VERSION "HINBNNNYYNNNYYNNNNNNNNNNNNYNNNYYYNNYNNNNNN/4//%%/4/'%**4NNN///"

NS_ :

BS_:

BU_: VirtualNMTMaster Sensor_3_ID28 Sensor_2_ID27 Sensor_1_ID23 Display_ID10

BO_ 1820 HBGuard_028: 1 Sensor_3_ID28
 SG_ Toggle : 7|1@1+ (1,0) [0|0] "" Vector__XXX
 SG_ State : 0|7@1+ (1,0) [0|0] "" Vector__XXX

BO_ 262 N28_SRDO1_Inv: 4 Sensor_3_ID28
 SG_ Pressure_1_inverted : 0|32@1- (1,0) [0|1200] "" Vector__XXX

BO_ 261 N28_SRDO1: 4 Sensor_3_ID28
 SG_ Pressure_1 : 0|32@1- (1,0) [0|1200] "" Vector__XXX

BO_ 1436 SSDO_028: 8 Sensor_3_ID28
 SG_ Pressure_1_inverted_6402_02 m2 : 32|32@1- (1,0) [0|1200] "" Vector__XXX
 SG_ Pressure_1_6402_01 m1 : 32|32@1- (1,0) [0|1200] "" Vector__XXX
 SG_ Highest_sub_index_supported_6402 m0 : 32|8@1+ (1,0) [0|255] "" Vector__XXX
 SG_ SubIndex_6402 m25602M : 24|8@1+ (1,0) [0|2] "" Vector__XXX
 SG_ Safety_Checksum_13FF_01 m1 : 32|16@1+ (1,0) [0|65535] "" Vector__XXX
 SG_ Safety_checksum_Number_of_entrie m0 : 32|8@1+ (1,0) [0|255] "" Vector__XXX
 SG_ SubIndex_13FF m5119M : 24|8@1+ (1,0) [0|1] "" Vector__XXX
 SG_ Configuration_valid_13FE m0 : 32|8@1+ (1,0) [0|255] "" Vector__XXX
 SG_ SubIndex_13FE m5118M : 24|8@1+ (1,0) [0|0] "" Vector__XXX
 SG_ SRDO1_mapping_inv_Byte1_1381_02 m2 : 32|32@1+ (1,0) [0|4294967295] "" Vector__XXX
 SG_ SRDO1_mapping_Byte1_1381_01 m1 : 32|32@1+ (1,0) [0|4294967295] "" Vector__XXX
 SG_ SRDO1_Number_of_mapped_objects_1 m0 : 32|8@1+ (1,0) [0|255] "" Vector__XXX
 SG_ SubIndex_1381 m4993M : 24|8@1+ (1,0) [0|2] "" Vector__XXX
 SG_ SRDO1_communication_par_COB_ID_2 m6 : 32|32@1+ (1,0) [0|4294967295] "" Vector__XXX
 SG_ SRDO1_communication_par_COB_ID_1 m5 : 32|32@1+ (1,0) [0|4294967295] "" Vector__XXX
 SG_ SRDO1_communication_par_Transmis m4 : 32|8@1+ (1,0) [254|254] "" Vector__XXX
 SG_ SRDO1_communication_par_refresh_ m2 : 32|16@1+ (1,0) [10|65535] "" Vector__XXX
 SG_ SRDO1_communication_par_Informat m1 : 32|8@1+ (1,0) [0|1] "" Vector__XXX
 SG_ Highest_sub_index_supported_1301 m0 : 32|8@1+ (1,0) [0|255] "" Vector__XXX
 SG_ SubIndex_1301 m4865M : 24|8@1+ (1,0) [0|6] "" Vector__XXX
 SG_ Serial_number_1018_04 m4 : 32|32@1+ (1,0) [0|4294967295] "" Vector__XXX
 SG_ Revision_number_1018_03 m3 : 32|32@1+ (1,0) [0|4294967295] "" Vector__XXX
 SG_ Product_Code_1018_02 m2 : 32|32@1+ (1,0) [0|4294967295] "" Vector__XXX
 SG_ Vendor_Id_1018_01 m1 : 32|32@1+ (1,0) [0|4294967295] "" Vector__XXX
 SG_ Highest_sub_index_supported_1018 m0 : 32|8@1+ (1,0) [1|4] "" Vector__XXX
 SG_ SubIndex_1018 m4120M : 24|8@1+ (1,0) [0|4] "" Vector__XXX
 SG_ Producer_Heartbeat_Time_1017 m0 : 32|16@1+ (1,0) [0|65535] "" Vector__XXX
 SG_ SubIndex_1017 m4119M : 24|8@1+ (1,0) [0|0] "" Vector__XXX
 SG_ Consumer_Heartbeat_Time16_1016_1 m16 : 32|32@1+ (1,0) [0|4294967295] "" Vector__XXX
 SG_ Consumer_Heartbeat_Time15_1016_0 m15 : 32|32@1+ (1,0) [0|4294967295] "" Vector__XXX
 SG_ Consumer_Heartbeat_Time14_1016_0 m14 : 32|32@1+ (1,0) [0|4294967295] "" Vector__XXX
 SG_ Consumer_Heartbeat_Time13_1016_0 m13 : 32|32@1+ (1,0) [0|4294967295] "" Vector__XXX
 SG_ Consumer_Heartbeat_Time12_1016_0 m12 : 32|32@1+ (1,0) [0|4294967295] "" Vector__XXX
 SG_ Consumer_Heartbeat_Time11_1016_0 m11 : 32|32@1+ (1,0) [0|4294967295] "" Vector__XXX
 SG_ Consumer_Heartbeat_Time10_1016_0 m10 : 32|32@1+ (1,0) [0|4294967295] "" Vector__XXX
 SG_ Consumer_Heartbeat_Time9_1016_09 m9 : 32|32@1+ (1,0) [0|4294967295] "" Vector__XXX
 SG_ Consumer_Heartbeat_Time8_1016_08 m8 : 32|32@1+ (1,0) [0|4294967295] "" Vector__XXX
 SG_ Consumer_Heartbeat_Time7_1016_07 m7 : 32|32@1+ (1,0) [0|4294967295] "" Vector__XXX
 SG_ Consumer_Heartbeat_Time6_1016_06 m6 : 32|32@1+ (1,0) [0|4294967295] "" Vector__XXX
 SG_ Consumer_Heartbeat_Time5_1016_05 m5 : 32|32@1+ (1,0) [0|4294967295] "" Vector__XXX
 SG_ Consumer_Heartbeat_Time4_1016_04 m4 : 32|32@1+ (1,0) [0|4294967295] "" Vector__XXX
 SG_ Consumer_Heartbeat_Time3_1016_03 m3 : 32|32@1+ (1,0) [0|4294967295] "" Vector__XXX
 SG_ Consumer_Heartbeat_Time2_1016_02 m2 : 32|32@1+ (1,0) [0|4294967295] "" Vector__XXX
 SG_ Consumer_Heartbeat_Time1_1016_01 m1 : 32|32@1+ (1,0) [0|4294967295] "" Vector__XXX
 SG_ NrOfObjects_1016_00 m0 : 32|8@1+ (1,0) [0|255] "" Vector__XXX
 SG_ SubIndex_1016 m4118M : 24|8@1+ (1,0) [0|16] "" Vector__XXX
 SG_ COB_ID_EMCY_1014 m0 : 32|32@1+ (1,0) [128|3221225471] "" Vector__XXX
 SG_ SubIndex_1014 m4116M : 24|8@1+ (1,0) [0|0] "" Vector__XXX
 SG_ Restore_all_Default_Parameters_1 m1 : 32|32@1+ (1,0) [0|4294967295] "" Vector__XXX
 SG_ Highest_sub_index_supported_1011 m0 : 32|8@1+ (1,0) [0|255] "" Vector__XXX
 SG_ SubIndex_1011 m4113M : 24|8@1+ (1,0) [0|1] "" Vector__XXX
 SG_ Save_all_Parameters_1010_01 m1 : 32|32@1+ (1,0) [0|4294967295] "" Vector__XXX
 SG_ Highest_sub_index_supported_1010 m0 : 32|8@1+ (1,0) [0|255] "" Vector__XXX
 SG_ SubIndex_1010 m4112M : 24|8@1+ (1,0) [0|1] "" Vector__XXX
 SG_ Life_Time_Factor_100D m0 : 32|8@1+ (1,0) [0|255] "" Vector__XXX
 SG_ SubIndex_100D m4109M : 24|8@1+ (1,0) [0|0] "" Vector__XXX
 SG_ Guard_Time_100C m0 : 32|16@1+ (1,0) [0|65535] "" Vector__XXX
 SG_ SubIndex_100C m4108M : 24|8@1+ (1,0) [0|0] "" Vector__XXX
 SG_ Sync_Window_Length_1007 m0 : 32|32@1+ (1,0) [0|4294967295] "" Vector__XXX
 SG_ SubIndex_1007 m4103M : 24|8@1+ (1,0) [0|0] "" Vector__XXX
 SG_ Communication_Cycle_Period_1006 m0 : 32|32@1+ (1,0) [0|4294967295] "" Vector__XXX
 SG_ SubIndex_1006 m4102M : 24|8@1+ (1,0) [0|0] "" Vector__XXX
 SG_ COB_ID_SYNC_1005 m0 : 32|32@1+ (1,0) [128|4294967295] "" Vector__XXX
 SG_ SubIndex_1005 m4101M : 24|8@1+ (1,0) [0|0] "" Vector__XXX
 SG_ Standard_error_field_1003_09 m9 : 32|32@1+ (1,0) [0|4294967295] "" Vector__XXX
 SG_ Standard_error_field_1003_08 m8 : 32|32@1+ (1,0) [0|4294967295] "" Vector__XXX
 SG_ Standard_error_field_1003_07 m7 : 32|32@1+ (1,0) [0|4294967295] "" Vector__XXX
 SG_ Standard_error_field_1003_06 m6 : 32|32@1+ (1,0) [0|4294967295] "" Vector__XXX
 SG_ Standard_error_field_1003_05 m5 : 32|32@1+ (1,0) [0|4294967295] "" Vector__XXX
 SG_ Standard_error_field_1003_04 m4 : 32|32@1+ (1,0) [0|4294967295] "" Vector__XXX
 SG_ Standard_error_field_1003_03 m3 : 32|32@1+ (1,0) [0|4294967295] "" Vector__XXX
 SG_ Standard_error_field_1003_02 m2 : 32|32@1+ (1,0) [0|4294967295] "" Vector__XXX
 SG_ Standard_error_field_1003_01 m1 : 32|32@1+ (1,0) [0|4294967295] "" Vector__XXX
 SG_ Number_of_Errors_1003_00 m0 : 32|8@1+ (1,0) [0|255] "" Vector__XXX
 SG_ SubIndex_1003 m4099M : 24|8@1+ (1,0) [0|9] "" Vector__XXX
 SG_ Error_Register_1001 m0 : 32|8@1+ (1,0) [0|255] "" Vector__XXX
 SG_ SubIndex_1001 m4097M : 24|8@1+ (1,0) [0|0] "" Vector__XXX
 SG_ Device_Type_1000 m0 : 32|32@1+ (1,0) [0|4294967295] "" Vector__XXX
 SG_ SubIndex_1000 m4096M : 24|8@1+ (1,0) [0|0] "" Vector__XXX
 SG_ Index m1M : 8|16@1+ (1,0) [4096|25602] "" Vector__XXX
 SG_ TransferType m1M : 1|1@1+ (1,0) [0|1] "" Vector__XXX
 SG_ NotUsedBytes m1 : 2|2@1+ (1,0) [0|3] "" Vector__XXX
 SG_ SizeIndicator m1 : 0|1@1+ (1,0) [0|1] "" Vector__XXX
 SG_ SCS M : 5|3@1+ (1,0) [0|6] "" Vector__XXX

BO_ 1564 CSDO_028: 8 Vector__XXX
 SG_ Pressure_1_inverted_6402_02 m2 : 32|32@1- (1,0) [0|1200] ""  Sensor_3_ID28
 SG_ Pressure_1_6402_01 m1 : 32|32@1- (1,0) [0|1200] ""  Sensor_3_ID28
 SG_ Highest_sub_index_supported_0000 m0 : 32|8@1+ (1,0) [0|255] ""  Sensor_3_ID28
 SG_ SubIndex_6402 m25602M : 24|8@1+ (1,0) [0|2] ""  Sensor_3_ID28
 SG_ Safety_Checksum_13FF_01 m1 : 32|16@1+ (1,0) [0|65535] ""  Sensor_3_ID28
 SG_ Safety_checksum_Number_of_e_0000 m0 : 32|8@1+ (1,0) [0|255] ""  Sensor_3_ID28
 SG_ SubIndex_13FF m5119M : 24|8@1+ (1,0) [0|1] ""  Sensor_3_ID28
 SG_ Configuration_valid_13FE m0 : 32|8@1+ (1,0) [0|255] ""  Sensor_3_ID28
 SG_ SubIndex_13FE m5118M : 24|8@1+ (1,0) [0|0] ""  Sensor_3_ID28
 SG_ SRDO1_mapping_inv_Byte1_1381_02 m2 : 32|32@1+ (1,0) [0|4294967295] ""  Sensor_3_ID28
 SG_ SRDO1_mapping_Byte1_1381_01 m1 : 32|32@1+ (1,0) [0|4294967295] ""  Sensor_3_ID28
 SG_ SRDO1_Number_of_mapped_obje_0000 m0 : 32|8@1+ (1,0) [0|255] ""  Sensor_3_ID28
 SG_ SubIndex_1381 m4993M : 24|8@1+ (1,0) [0|2] ""  Sensor_3_ID28
 SG_ SRDO1_communication_par_COB_0000 m6 : 32|32@1+ (1,0) [0|4294967295] ""  Sensor_3_ID28
 SG_ SRDO1_communication_par_COB_0001 m5 : 32|32@1+ (1,0) [0|4294967295] ""  Sensor_3_ID28
 SG_ SRDO1_communication_par_Tra_0000 m4 : 32|8@1+ (1,0) [254|254] ""  Sensor_3_ID28
 SG_ SRDO1_communication_par_ref_0000 m2 : 32|16@1+ (1,0) [10|65535] ""  Sensor_3_ID28
 SG_ SRDO1_communication_par_Inf_0000 m1 : 32|8@1+ (1,0) [0|1] ""  Sensor_3_ID28
 SG_ Highest_sub_index_supported_0001 m0 : 32|8@1+ (1,0) [0|255] ""  Sensor_3_ID28
 SG_ SubIndex_1301 m4865M : 24|8@1+ (1,0) [0|6] ""  Sensor_3_ID28
 SG_ Serial_number_1018_04 m4 : 32|32@1+ (1,0) [0|4294967295] ""  Sensor_3_ID28
 SG_ Revision_number_1018_03 m3 : 32|32@1+ (1,0) [0|4294967295] ""  Sensor_3_ID28
 SG_ Product_Code_1018_02 m2 : 32|32@1+ (1,0) [0|4294967295] ""  Sensor_3_ID28
 SG_ Vendor_Id_1018_01 m1 : 32|32@1+ (1,0) [0|4294967295] ""  Sensor_3_ID28
 SG_ Highest_sub_index_supported_0002 m0 : 32|8@1+ (1,0) [1|4] ""  Sensor_3_ID28
 SG_ SubIndex_1018 m4120M : 24|8@1+ (1,0) [0|4] ""  Sensor_3_ID28
 SG_ Producer_Heartbeat_Time_1017 m0 : 32|16@1+ (1,0) [0|65535] ""  Sensor_3_ID28
 SG_ SubIndex_1017 m4119M : 24|8@1+ (1,0) [0|0] ""  Sensor_3_ID28
 SG_ Consumer_Heartbeat_Time16_1_0000 m16 : 32|32@1+ (1,0) [0|4294967295] ""  Sensor_3_ID28
 SG_ Consumer_Heartbeat_Time15_1_0000 m15 : 32|32@1+ (1,0) [0|4294967295] ""  Sensor_3_ID28
 SG_ Consumer_Heartbeat_Time14_1_0000 m14 : 32|32@1+ (1,0) [0|4294967295] ""  Sensor_3_ID28
 SG_ Consumer_Heartbeat_Time13_1_0000 m13 : 32|32@1+ (1,0) [0|4294967295] ""  Sensor_3_ID28
 SG_ Consumer_Heartbeat_Time12_1_0000 m12 : 32|32@1+ (1,0) [0|4294967295] ""  Sensor_3_ID28
 SG_ Consumer_Heartbeat_Time11_1_0000 m11 : 32|32@1+ (1,0) [0|4294967295] ""  Sensor_3_ID28
 SG_ Consumer_Heartbeat_Time10_1_0000 m10 : 32|32@1+ (1,0) [0|4294967295] ""  Sensor_3_ID28
 SG_ Consumer_Heartbeat_Time9_1016_09 m9 : 32|32@1+ (1,0) [0|4294967295] ""  Sensor_3_ID28
 SG_ Consumer_Heartbeat_Time8_1016_08 m8 : 32|32@1+ (1,0) [0|4294967295] ""  Sensor_3_ID28
 SG_ Consumer_Heartbeat_Time7_1016_07 m7 : 32|32@1+ (1,0) [0|4294967295] ""  Sensor_3_ID28
 SG_ Consumer_Heartbeat_Time6_1016_06 m6 : 32|32@1+ (1,0) [0|4294967295] ""  Sensor_3_ID28
 SG_ Consumer_Heartbeat_Time5_1016_05 m5 : 32|32@1+ (1,0) [0|4294967295] ""  Sensor_3_ID28
 SG_ Consumer_Heartbeat_Time4_1016_04 m4 : 32|32@1+ (1,0) [0|4294967295] ""  Sensor_3_ID28
 SG_ Consumer_Heartbeat_Time3_1016_03 m3 : 32|32@1+ (1,0) [0|4294967295] ""  Sensor_3_ID28
 SG_ Consumer_Heartbeat_Time2_1016_02 m2 : 32|32@1+ (1,0) [0|4294967295] ""  Sensor_3_ID28
 SG_ Consumer_Heartbeat_Time1_1016_01 m1 : 32|32@1+ (1,0) [0|4294967295] ""  Sensor_3_ID28
 SG_ NrOfObjects_1016_00 m0 : 32|8@1+ (1,0) [0|255] ""  Sensor_3_ID28
 SG_ SubIndex_1016 m4118M : 24|8@1+ (1,0) [0|16] ""  Sensor_3_ID28
 SG_ COB_ID_EMCY_1014 m0 : 32|32@1+ (1,0) [128|3221225471] ""  Sensor_3_ID28
 SG_ SubIndex_1014 m4116M : 24|8@1+ (1,0) [0|0] ""  Sensor_3_ID28
 SG_ Restore_all_Default_Paramet_0000 m1 : 32|32@1+ (1,0) [0|4294967295] ""  Sensor_3_ID28
 SG_ Highest_sub_index_supported_0003 m0 : 32|8@1+ (1,0) [0|255] ""  Sensor_3_ID28
 SG_ SubIndex_1011 m4113M : 24|8@1+ (1,0) [0|1] ""  Sensor_3_ID28
 SG_ Save_all_Parameters_1010_01 m1 : 32|32@1+ (1,0) [0|4294967295] ""  Sensor_3_ID28
 SG_ Highest_sub_index_supported_0004 m0 : 32|8@1+ (1,0) [0|255] ""  Sensor_3_ID28
 SG_ SubIndex_1010 m4112M : 24|8@1+ (1,0) [0|1] ""  Sensor_3_ID28
 SG_ Life_Time_Factor_100D m0 : 32|8@1+ (1,0) [0|255] ""  Sensor_3_ID28
 SG_ SubIndex_100D m4109M : 24|8@1+ (1,0) [0|0] ""  Sensor_3_ID28
 SG_ Guard_Time_100C m0 : 32|16@1+ (1,0) [0|65535] ""  Sensor_3_ID28
 SG_ SubIndex_100C m4108M : 24|8@1+ (1,0) [0|0] ""  Sensor_3_ID28
 SG_ Sync_Window_Length_1007 m0 : 32|32@1+ (1,0) [0|4294967295] ""  Sensor_3_ID28
 SG_ SubIndex_1007 m4103M : 24|8@1+ (1,0) [0|0] ""  Sensor_3_ID28
 SG_ Communication_Cycle_Period_1006 m0 : 32|32@1+ (1,0) [0|4294967295] ""  Sensor_3_ID28
 SG_ SubIndex_1006 m4102M : 24|8@1+ (1,0) [0|0] ""  Sensor_3_ID28
 SG_ COB_ID_SYNC_1005 m0 : 32|32@1+ (1,0) [128|4294967295] ""  Sensor_3_ID28
 SG_ SubIndex_1005 m4101M : 24|8@1+ (1,0) [0|0] ""  Sensor_3_ID28
 SG_ Standard_error_field_1003_09 m9 : 32|32@1+ (1,0) [0|4294967295] ""  Sensor_3_ID28
 SG_ Standard_error_field_1003_08 m8 : 32|32@1+ (1,0) [0|4294967295] ""  Sensor_3_ID28
 SG_ Standard_error_field_1003_07 m7 : 32|32@1+ (1,0) [0|4294967295] ""  Sensor_3_ID28
 SG_ Standard_error_field_1003_06 m6 : 32|32@1+ (1,0) [0|4294967295] ""  Sensor_3_ID28
 SG_ Standard_error_field_1003_05 m5 : 32|32@1+ (1,0) [0|4294967295] ""  Sensor_3_ID28
 SG_ Standard_error_field_1003_04 m4 : 32|32@1+ (1,0) [0|4294967295] ""  Sensor_3_ID28
 SG_ Standard_error_field_1003_03 m3 : 32|32@1+ (1,0) [0|4294967295] ""  Sensor_3_ID28
 SG_ Standard_error_field_1003_02 m2 : 32|32@1+ (1,0) [0|4294967295] ""  Sensor_3_ID28
 SG_ Standard_error_field_1003_01 m1 : 32|32@1+ (1,0) [0|4294967295] ""  Sensor_3_ID28
 SG_ Number_of_Errors_1003_00 m0 : 32|8@1+ (1,0) [0|255] ""  Sensor_3_ID28
 SG_ SubIndex_1003 m4099M : 24|8@1+ (1,0) [0|9] ""  Sensor_3_ID28
 SG_ Error_Register_1001 m0 : 32|8@1+ (1,0) [0|255] ""  Sensor_3_ID28
 SG_ SubIndex_1001 m4097M : 24|8@1+ (1,0) [0|0] ""  Sensor_3_ID28
 SG_ Device_Type_1000 m0 : 32|32@1+ (1,0) [0|4294967295] ""  Sensor_3_ID28
 SG_ SubIndex_1000 m4096M : 24|8@1+ (1,0) [0|0] ""  Sensor_3_ID28
 SG_ Index m1M : 8|16@1+ (1,0) [4096|25602] ""  Sensor_3_ID28
 SG_ TransferType m1M : 1|1@1+ (1,0) [0|1] ""  Sensor_3_ID28
 SG_ NotUsedBytes m1 : 2|2@1+ (1,0) [0|3] ""  Sensor_3_ID28
 SG_ SizeIndicator m1 : 0|1@1+ (1,0) [0|1] ""  Sensor_3_ID28
 SG_ CCS M : 5|3@1+ (1,0) [0|6] ""  Sensor_3_ID28

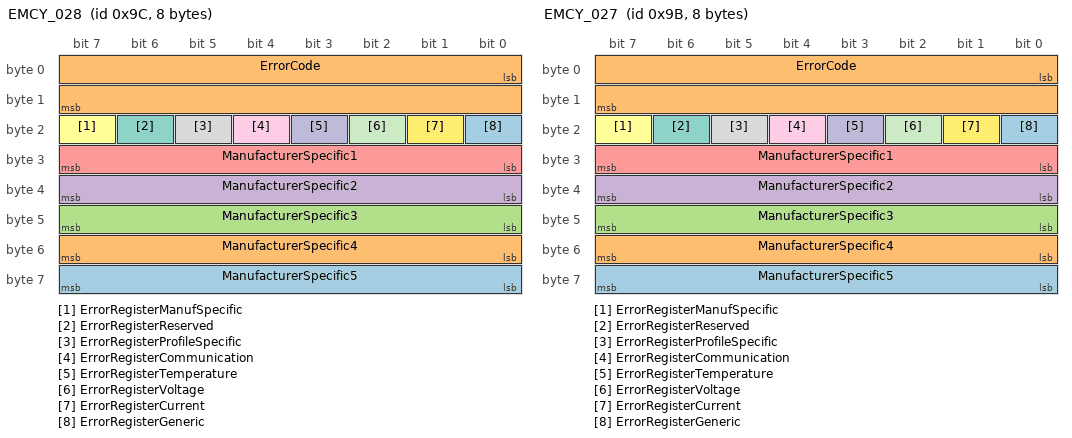
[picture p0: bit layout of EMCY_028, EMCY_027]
BO_ 156 EMCY_028: 8 Sensor_3_ID28
 SG_ ManufacturerSpecific5 : 56|8@1+ (1,0) [0|0] "" Vector__XXX
 SG_ ManufacturerSpecific4 : 48|8@1+ (1,0) [0|0] "" Vector__XXX
 SG_ ManufacturerSpecific3 : 40|8@1+ (1,0) [0|0] "" Vector__XXX
 SG_ ManufacturerSpecific2 : 32|8@1+ (1,0) [0|0] "" Vector__XXX
 SG_ ManufacturerSpecific1 : 24|8@1+ (1,0) [0|0] "" Vector__XXX
 SG_ ErrorRegisterManufSpecific : 23|1@1+ (1,0) [0|0] "" Vector__XXX
 SG_ ErrorRegisterReserved : 22|1@1+ (1,0) [0|0] "" Vector__XXX
 SG_ ErrorRegisterProfileSpecific : 21|1@1+ (1,0) [0|0] "" Vector__XXX
 SG_ ErrorRegisterCommunication : 20|1@1+ (1,0) [0|0] "" Vector__XXX
 SG_ ErrorRegisterTemperature : 19|1@1+ (1,0) [0|0] "" Vector__XXX
 SG_ ErrorRegisterVoltage : 18|1@1+ (1,0) [0|0] "" Vector__XXX
 SG_ ErrorRegisterCurrent : 17|1@1+ (1,0) [0|0] "" Vector__XXX
 SG_ ErrorRegisterGeneric : 16|1@1+ (1,0) [0|0] "" Vector__XXX
 SG_ ErrorCode : 0|16@1+ (1,0) [0|0] "" Vector__XXX

BO_ 1819 HBGuard_027: 1 Sensor_2_ID27
 SG_ Toggle : 7|1@1+ (1,0) [0|0] "" Vector__XXX
 SG_ State : 0|7@1+ (1,0) [0|0] "" Vector__XXX

BO_ 260 N27_SRDO1_Inv: 4 Sensor_2_ID27
 SG_ Pressure_1_inverted : 0|32@1- (1,0) [0|1200] "" Vector__XXX

BO_ 259 N27_SRDO1: 4 Sensor_2_ID27
 SG_ Pressure_1 : 0|32@1- (1,0) [0|1200] "" Vector__XXX

BO_ 1435 SSDO_027: 8 Sensor_2_ID27
 SG_ Pressure_1_inverted_6402_02 m2 : 32|32@1- (1,0) [0|1200] "" Vector__XXX
 SG_ Pressure_1_6402_01 m1 : 32|32@1- (1,0) [0|1200] "" Vector__XXX
 SG_ Highest_sub_index_supported_0005 m0 : 32|8@1+ (1,0) [0|255] "" Vector__XXX
 SG_ SubIndex_6402 m25602M : 24|8@1+ (1,0) [0|2] "" Vector__XXX
 SG_ Safety_Checksum_13FF_01 m1 : 32|16@1+ (1,0) [0|65535] "" Vector__XXX
 SG_ Safety_checksum_Number_of_e_0001 m0 : 32|8@1+ (1,0) [0|255] "" Vector__XXX
 SG_ SubIndex_13FF m5119M : 24|8@1+ (1,0) [0|1] "" Vector__XXX
 SG_ Configuration_valid_13FE m0 : 32|8@1+ (1,0) [0|255] "" Vector__XXX
 SG_ SubIndex_13FE m5118M : 24|8@1+ (1,0) [0|0] "" Vector__XXX
 SG_ SRDO1_mapping_inv_Byte1_1381_02 m2 : 32|32@1+ (1,0) [0|4294967295] "" Vector__XXX
 SG_ SRDO1_mapping_Byte1_1381_01 m1 : 32|32@1+ (1,0) [0|4294967295] "" Vector__XXX
 SG_ SRDO1_Number_of_mapped_obje_0001 m0 : 32|8@1+ (1,0) [0|255] "" Vector__XXX
 SG_ SubIndex_1381 m4993M : 24|8@1+ (1,0) [0|2] "" Vector__XXX
 SG_ SRDO1_communication_par_COB_0002 m6 : 32|32@1+ (1,0) [0|4294967295] "" Vector__XXX
 SG_ SRDO1_communication_par_COB_0003 m5 : 32|32@1+ (1,0) [0|4294967295] "" Vector__XXX
 SG_ SRDO1_communication_par_Tra_0001 m4 : 32|8@1+ (1,0) [254|254] "" Vector__XXX
 SG_ SRDO1_communication_par_ref_0001 m2 : 32|16@1+ (1,0) [10|65535] "" Vector__XXX
 SG_ SRDO1_communication_par_Inf_0001 m1 : 32|8@1+ (1,0) [0|1] "" Vector__XXX
 SG_ Highest_sub_index_supported_0006 m0 : 32|8@1+ (1,0) [0|255] "" Vector__XXX
 SG_ SubIndex_1301 m4865M : 24|8@1+ (1,0) [0|6] "" Vector__XXX
 SG_ Serial_number_1018_04 m4 : 32|32@1+ (1,0) [0|4294967295] "" Vector__XXX
 SG_ Revision_number_1018_03 m3 : 32|32@1+ (1,0) [0|4294967295] "" Vector__XXX
 SG_ Product_Code_1018_02 m2 : 32|32@1+ (1,0) [0|4294967295] "" Vector__XXX
 SG_ Vendor_Id_1018_01 m1 : 32|32@1+ (1,0) [0|4294967295] "" Vector__XXX
 SG_ Highest_sub_index_supported_0007 m0 : 32|8@1+ (1,0) [1|4] "" Vector__XXX
 SG_ SubIndex_1018 m4120M : 24|8@1+ (1,0) [0|4] "" Vector__XXX
 SG_ Producer_Heartbeat_Time_1017 m0 : 32|16@1+ (1,0) [0|65535] "" Vector__XXX
 SG_ SubIndex_1017 m4119M : 24|8@1+ (1,0) [0|0] "" Vector__XXX
 SG_ Consumer_Heartbeat_Time16_1_0001 m16 : 32|32@1+ (1,0) [0|4294967295] "" Vector__XXX
 SG_ Consumer_Heartbeat_Time15_1_0001 m15 : 32|32@1+ (1,0) [0|4294967295] "" Vector__XXX
 SG_ Consumer_Heartbeat_Time14_1_0001 m14 : 32|32@1+ (1,0) [0|4294967295] "" Vector__XXX
 SG_ Consumer_Heartbeat_Time13_1_0001 m13 : 32|32@1+ (1,0) [0|4294967295] "" Vector__XXX
 SG_ Consumer_Heartbeat_Time12_1_0001 m12 : 32|32@1+ (1,0) [0|4294967295] "" Vector__XXX
 SG_ Consumer_Heartbeat_Time11_1_0001 m11 : 32|32@1+ (1,0) [0|4294967295] "" Vector__XXX
 SG_ Consumer_Heartbeat_Time10_1_0001 m10 : 32|32@1+ (1,0) [0|4294967295] "" Vector__XXX
 SG_ Consumer_Heartbeat_Time9_1016_09 m9 : 32|32@1+ (1,0) [0|4294967295] "" Vector__XXX
 SG_ Consumer_Heartbeat_Time8_1016_08 m8 : 32|32@1+ (1,0) [0|4294967295] "" Vector__XXX
 SG_ Consumer_Heartbeat_Time7_1016_07 m7 : 32|32@1+ (1,0) [0|4294967295] "" Vector__XXX
 SG_ Consumer_Heartbeat_Time6_1016_06 m6 : 32|32@1+ (1,0) [0|4294967295] "" Vector__XXX
 SG_ Consumer_Heartbeat_Time5_1016_05 m5 : 32|32@1+ (1,0) [0|4294967295] "" Vector__XXX
 SG_ Consumer_Heartbeat_Time4_1016_04 m4 : 32|32@1+ (1,0) [0|4294967295] "" Vector__XXX
 SG_ Consumer_Heartbeat_Time3_1016_03 m3 : 32|32@1+ (1,0) [0|4294967295] "" Vector__XXX
 SG_ Consumer_Heartbeat_Time2_1016_02 m2 : 32|32@1+ (1,0) [0|4294967295] "" Vector__XXX
 SG_ Consumer_Heartbeat_Time1_1016_01 m1 : 32|32@1+ (1,0) [0|4294967295] "" Vector__XXX
 SG_ NrOfObjects_1016_00 m0 : 32|8@1+ (1,0) [0|255] "" Vector__XXX
 SG_ SubIndex_1016 m4118M : 24|8@1+ (1,0) [0|16] "" Vector__XXX
 SG_ COB_ID_EMCY_1014 m0 : 32|32@1+ (1,0) [128|3221225471] "" Vector__XXX
 SG_ SubIndex_1014 m4116M : 24|8@1+ (1,0) [0|0] "" Vector__XXX
 SG_ Restore_all_Default_Paramet_0001 m1 : 32|32@1+ (1,0) [0|4294967295] "" Vector__XXX
 SG_ Highest_sub_index_supported_0008 m0 : 32|8@1+ (1,0) [0|255] "" Vector__XXX
 SG_ SubIndex_1011 m4113M : 24|8@1+ (1,0) [0|1] "" Vector__XXX
 SG_ Save_all_Parameters_1010_01 m1 : 32|32@1+ (1,0) [0|4294967295] "" Vector__XXX
 SG_ Highest_sub_index_supported_0009 m0 : 32|8@1+ (1,0) [0|255] "" Vector__XXX
 SG_ SubIndex_1010 m4112M : 24|8@1+ (1,0) [0|1] "" Vector__XXX
 SG_ Life_Time_Factor_100D m0 : 32|8@1+ (1,0) [0|255] "" Vector__XXX
 SG_ SubIndex_100D m4109M : 24|8@1+ (1,0) [0|0] "" Vector__XXX
 SG_ Guard_Time_100C m0 : 32|16@1+ (1,0) [0|65535] "" Vector__XXX
 SG_ SubIndex_100C m4108M : 24|8@1+ (1,0) [0|0] "" Vector__XXX
 SG_ Sync_Window_Length_1007 m0 : 32|32@1+ (1,0) [0|4294967295] "" Vector__XXX
 SG_ SubIndex_1007 m4103M : 24|8@1+ (1,0) [0|0] "" Vector__XXX
 SG_ Communication_Cycle_Period_1006 m0 : 32|32@1+ (1,0) [0|4294967295] "" Vector__XXX
 SG_ SubIndex_1006 m4102M : 24|8@1+ (1,0) [0|0] "" Vector__XXX
 SG_ COB_ID_SYNC_1005 m0 : 32|32@1+ (1,0) [128|4294967295] "" Vector__XXX
 SG_ SubIndex_1005 m4101M : 24|8@1+ (1,0) [0|0] "" Vector__XXX
 SG_ Standard_error_field_1003_09 m9 : 32|32@1+ (1,0) [0|4294967295] "" Vector__XXX
 SG_ Standard_error_field_1003_08 m8 : 32|32@1+ (1,0) [0|4294967295] "" Vector__XXX
 SG_ Standard_error_field_1003_07 m7 : 32|32@1+ (1,0) [0|4294967295] "" Vector__XXX
 SG_ Standard_error_field_1003_06 m6 : 32|32@1+ (1,0) [0|4294967295] "" Vector__XXX
 SG_ Standard_error_field_1003_05 m5 : 32|32@1+ (1,0) [0|4294967295] "" Vector__XXX
 SG_ Standard_error_field_1003_04 m4 : 32|32@1+ (1,0) [0|4294967295] "" Vector__XXX
 SG_ Standard_error_field_1003_03 m3 : 32|32@1+ (1,0) [0|4294967295] "" Vector__XXX
 SG_ Standard_error_field_1003_02 m2 : 32|32@1+ (1,0) [0|4294967295] "" Vector__XXX
 SG_ Standard_error_field_1003_01 m1 : 32|32@1+ (1,0) [0|4294967295] "" Vector__XXX
 SG_ Number_of_Errors_1003_00 m0 : 32|8@1+ (1,0) [0|255] "" Vector__XXX
 SG_ SubIndex_1003 m4099M : 24|8@1+ (1,0) [0|9] "" Vector__XXX
 SG_ Error_Register_1001 m0 : 32|8@1+ (1,0) [0|255] "" Vector__XXX
 SG_ SubIndex_1001 m4097M : 24|8@1+ (1,0) [0|0] "" Vector__XXX
 SG_ Device_Type_1000 m0 : 32|32@1+ (1,0) [0|4294967295] "" Vector__XXX
 SG_ SubIndex_1000 m4096M : 24|8@1+ (1,0) [0|0] "" Vector__XXX
 SG_ Index m1M : 8|16@1+ (1,0) [4096|25602] "" Vector__XXX
 SG_ TransferType m1M : 1|1@1+ (1,0) [0|1] "" Vector__XXX
 SG_ NotUsedBytes m1 : 2|2@1+ (1,0) [0|3] "" Vector__XXX
 SG_ SizeIndicator m1 : 0|1@1+ (1,0) [0|1] "" Vector__XXX
 SG_ SCS M : 5|3@1+ (1,0) [0|6] "" Vector__XXX

BO_ 1563 CSDO_027: 8 Vector__XXX
 SG_ Pressure_1_inverted_6402_02 m2 : 32|32@1- (1,0) [0|1200] ""  Sensor_2_ID27
 SG_ Pressure_1_6402_01 m1 : 32|32@1- (1,0) [0|1200] ""  Sensor_2_ID27
 SG_ Highest_sub_index_supported_0010 m0 : 32|8@1+ (1,0) [0|255] ""  Sensor_2_ID27
 SG_ SubIndex_6402 m25602M : 24|8@1+ (1,0) [0|2] ""  Sensor_2_ID27
 SG_ Safety_Checksum_13FF_01 m1 : 32|16@1+ (1,0) [0|65535] ""  Sensor_2_ID27
 SG_ Safety_checksum_Number_of_e_0002 m0 : 32|8@1+ (1,0) [0|255] ""  Sensor_2_ID27
 SG_ SubIndex_13FF m5119M : 24|8@1+ (1,0) [0|1] ""  Sensor_2_ID27
 SG_ Configuration_valid_13FE m0 : 32|8@1+ (1,0) [0|255] ""  Sensor_2_ID27
 SG_ SubIndex_13FE m5118M : 24|8@1+ (1,0) [0|0] ""  Sensor_2_ID27
 SG_ SRDO1_mapping_inv_Byte1_1381_02 m2 : 32|32@1+ (1,0) [0|4294967295] ""  Sensor_2_ID27
 SG_ SRDO1_mapping_Byte1_1381_01 m1 : 32|32@1+ (1,0) [0|4294967295] ""  Sensor_2_ID27
 SG_ SRDO1_Number_of_mapped_obje_0002 m0 : 32|8@1+ (1,0) [0|255] ""  Sensor_2_ID27
 SG_ SubIndex_1381 m4993M : 24|8@1+ (1,0) [0|2] ""  Sensor_2_ID27
 SG_ SRDO1_communication_par_COB_0004 m6 : 32|32@1+ (1,0) [0|4294967295] ""  Sensor_2_ID27
 SG_ SRDO1_communication_par_COB_0005 m5 : 32|32@1+ (1,0) [0|4294967295] ""  Sensor_2_ID27
 SG_ SRDO1_communication_par_Tra_0002 m4 : 32|8@1+ (1,0) [254|254] ""  Sensor_2_ID27
 SG_ SRDO1_communication_par_ref_0002 m2 : 32|16@1+ (1,0) [10|65535] ""  Sensor_2_ID27
 SG_ SRDO1_communication_par_Inf_0002 m1 : 32|8@1+ (1,0) [0|1] ""  Sensor_2_ID27
 SG_ Highest_sub_index_supported_0011 m0 : 32|8@1+ (1,0) [0|255] ""  Sensor_2_ID27
 SG_ SubIndex_1301 m4865M : 24|8@1+ (1,0) [0|6] ""  Sensor_2_ID27
 SG_ Serial_number_1018_04 m4 : 32|32@1+ (1,0) [0|4294967295] ""  Sensor_2_ID27
 SG_ Revision_number_1018_03 m3 : 32|32@1+ (1,0) [0|4294967295] ""  Sensor_2_ID27
 SG_ Product_Code_1018_02 m2 : 32|32@1+ (1,0) [0|4294967295] ""  Sensor_2_ID27
 SG_ Vendor_Id_1018_01 m1 : 32|32@1+ (1,0) [0|4294967295] ""  Sensor_2_ID27
 SG_ Highest_sub_index_supported_0012 m0 : 32|8@1+ (1,0) [1|4] ""  Sensor_2_ID27
 SG_ SubIndex_1018 m4120M : 24|8@1+ (1,0) [0|4] ""  Sensor_2_ID27
 SG_ Producer_Heartbeat_Time_1017 m0 : 32|16@1+ (1,0) [0|65535] ""  Sensor_2_ID27
 SG_ SubIndex_1017 m4119M : 24|8@1+ (1,0) [0|0] ""  Sensor_2_ID27
 SG_ Consumer_Heartbeat_Time16_1_0002 m16 : 32|32@1+ (1,0) [0|4294967295] ""  Sensor_2_ID27
 SG_ Consumer_Heartbeat_Time15_1_0002 m15 : 32|32@1+ (1,0) [0|4294967295] ""  Sensor_2_ID27
 SG_ Consumer_Heartbeat_Time14_1_0002 m14 : 32|32@1+ (1,0) [0|4294967295] ""  Sensor_2_ID27
 SG_ Consumer_Heartbeat_Time13_1_0002 m13 : 32|32@1+ (1,0) [0|4294967295] ""  Sensor_2_ID27
 SG_ Consumer_Heartbeat_Time12_1_0002 m12 : 32|32@1+ (1,0) [0|4294967295] ""  Sensor_2_ID27
 SG_ Consumer_Heartbeat_Time11_1_0002 m11 : 32|32@1+ (1,0) [0|4294967295] ""  Sensor_2_ID27
 SG_ Consumer_Heartbeat_Time10_1_0002 m10 : 32|32@1+ (1,0) [0|4294967295] ""  Sensor_2_ID27
 SG_ Consumer_Heartbeat_Time9_1016_09 m9 : 32|32@1+ (1,0) [0|4294967295] ""  Sensor_2_ID27
 SG_ Consumer_Heartbeat_Time8_1016_08 m8 : 32|32@1+ (1,0) [0|4294967295] ""  Sensor_2_ID27
 SG_ Consumer_Heartbeat_Time7_1016_07 m7 : 32|32@1+ (1,0) [0|4294967295] ""  Sensor_2_ID27
 SG_ Consumer_Heartbeat_Time6_1016_06 m6 : 32|32@1+ (1,0) [0|4294967295] ""  Sensor_2_ID27
 SG_ Consumer_Heartbeat_Time5_1016_05 m5 : 32|32@1+ (1,0) [0|4294967295] ""  Sensor_2_ID27
 SG_ Consumer_Heartbeat_Time4_1016_04 m4 : 32|32@1+ (1,0) [0|4294967295] ""  Sensor_2_ID27
 SG_ Consumer_Heartbeat_Time3_1016_03 m3 : 32|32@1+ (1,0) [0|4294967295] ""  Sensor_2_ID27
 SG_ Consumer_Heartbeat_Time2_1016_02 m2 : 32|32@1+ (1,0) [0|4294967295] ""  Sensor_2_ID27
 SG_ Consumer_Heartbeat_Time1_1016_01 m1 : 32|32@1+ (1,0) [0|4294967295] ""  Sensor_2_ID27
 SG_ NrOfObjects_1016_00 m0 : 32|8@1+ (1,0) [0|255] ""  Sensor_2_ID27
 SG_ SubIndex_1016 m4118M : 24|8@1+ (1,0) [0|16] ""  Sensor_2_ID27
 SG_ COB_ID_EMCY_1014 m0 : 32|32@1+ (1,0) [128|3221225471] ""  Sensor_2_ID27
 SG_ SubIndex_1014 m4116M : 24|8@1+ (1,0) [0|0] ""  Sensor_2_ID27
 SG_ Restore_all_Default_Paramet_0002 m1 : 32|32@1+ (1,0) [0|4294967295] ""  Sensor_2_ID27
 SG_ Highest_sub_index_supported_0013 m0 : 32|8@1+ (1,0) [0|255] ""  Sensor_2_ID27
 SG_ SubIndex_1011 m4113M : 24|8@1+ (1,0) [0|1] ""  Sensor_2_ID27
 SG_ Save_all_Parameters_1010_01 m1 : 32|32@1+ (1,0) [0|4294967295] ""  Sensor_2_ID27
 SG_ Highest_sub_index_supported_0014 m0 : 32|8@1+ (1,0) [0|255] ""  Sensor_2_ID27
 SG_ SubIndex_1010 m4112M : 24|8@1+ (1,0) [0|1] ""  Sensor_2_ID27
 SG_ Life_Time_Factor_100D m0 : 32|8@1+ (1,0) [0|255] ""  Sensor_2_ID27
 SG_ SubIndex_100D m4109M : 24|8@1+ (1,0) [0|0] ""  Sensor_2_ID27
 SG_ Guard_Time_100C m0 : 32|16@1+ (1,0) [0|65535] ""  Sensor_2_ID27
 SG_ SubIndex_100C m4108M : 24|8@1+ (1,0) [0|0] ""  Sensor_2_ID27
 SG_ Sync_Window_Length_1007 m0 : 32|32@1+ (1,0) [0|4294967295] ""  Sensor_2_ID27
 SG_ SubIndex_1007 m4103M : 24|8@1+ (1,0) [0|0] ""  Sensor_2_ID27
 SG_ Communication_Cycle_Period_1006 m0 : 32|32@1+ (1,0) [0|4294967295] ""  Sensor_2_ID27
 SG_ SubIndex_1006 m4102M : 24|8@1+ (1,0) [0|0] ""  Sensor_2_ID27
 SG_ COB_ID_SYNC_1005 m0 : 32|32@1+ (1,0) [128|4294967295] ""  Sensor_2_ID27
 SG_ SubIndex_1005 m4101M : 24|8@1+ (1,0) [0|0] ""  Sensor_2_ID27
 SG_ Standard_error_field_1003_09 m9 : 32|32@1+ (1,0) [0|4294967295] ""  Sensor_2_ID27
 SG_ Standard_error_field_1003_08 m8 : 32|32@1+ (1,0) [0|4294967295] ""  Sensor_2_ID27
 SG_ Standard_error_field_1003_07 m7 : 32|32@1+ (1,0) [0|4294967295] ""  Sensor_2_ID27
 SG_ Standard_error_field_1003_06 m6 : 32|32@1+ (1,0) [0|4294967295] ""  Sensor_2_ID27
 SG_ Standard_error_field_1003_05 m5 : 32|32@1+ (1,0) [0|4294967295] ""  Sensor_2_ID27
 SG_ Standard_error_field_1003_04 m4 : 32|32@1+ (1,0) [0|4294967295] ""  Sensor_2_ID27
 SG_ Standard_error_field_1003_03 m3 : 32|32@1+ (1,0) [0|4294967295] ""  Sensor_2_ID27
 SG_ Standard_error_field_1003_02 m2 : 32|32@1+ (1,0) [0|4294967295] ""  Sensor_2_ID27
 SG_ Standard_error_field_1003_01 m1 : 32|32@1+ (1,0) [0|4294967295] ""  Sensor_2_ID27
 SG_ Number_of_Errors_1003_00 m0 : 32|8@1+ (1,0) [0|255] ""  Sensor_2_ID27
 SG_ SubIndex_1003 m4099M : 24|8@1+ (1,0) [0|9] ""  Sensor_2_ID27
 SG_ Error_Register_1001 m0 : 32|8@1+ (1,0) [0|255] ""  Sensor_2_ID27
 SG_ SubIndex_1001 m4097M : 24|8@1+ (1,0) [0|0] ""  Sensor_2_ID27
 SG_ Device_Type_1000 m0 : 32|32@1+ (1,0) [0|4294967295] ""  Sensor_2_ID27
 SG_ SubIndex_1000 m4096M : 24|8@1+ (1,0) [0|0] ""  Sensor_2_ID27
 SG_ Index m1M : 8|16@1+ (1,0) [4096|25602] ""  Sensor_2_ID27
 SG_ TransferType m1M : 1|1@1+ (1,0) [0|1] ""  Sensor_2_ID27
 SG_ NotUsedBytes m1 : 2|2@1+ (1,0) [0|3] ""  Sensor_2_ID27
 SG_ SizeIndicator m1 : 0|1@1+ (1,0) [0|1] ""  Sensor_2_ID27
 SG_ CCS M : 5|3@1+ (1,0) [0|6] ""  Sensor_2_ID27

BO_ 155 EMCY_027: 8 Sensor_2_ID27
 SG_ ManufacturerSpecific5 : 56|8@1+ (1,0) [0|0] "" Vector__XXX
 SG_ ManufacturerSpecific4 : 48|8@1+ (1,0) [0|0] "" Vector__XXX
 SG_ ManufacturerSpecific3 : 40|8@1+ (1,0) [0|0] "" Vector__XXX
 SG_ ManufacturerSpecific2 : 32|8@1+ (1,0) [0|0] "" Vector__XXX
 SG_ ManufacturerSpecific1 : 24|8@1+ (1,0) [0|0] "" Vector__XXX
 SG_ ErrorRegisterManufSpecific : 23|1@1+ (1,0) [0|0] "" Vector__XXX
 SG_ ErrorRegisterReserved : 22|1@1+ (1,0) [0|0] "" Vector__XXX
 SG_ ErrorRegisterProfileSpecific : 21|1@1+ (1,0) [0|0] "" Vector__XXX
 SG_ ErrorRegisterCommunication : 20|1@1+ (1,0) [0|0] "" Vector__XXX
 SG_ ErrorRegisterTemperature : 19|1@1+ (1,0) [0|0] "" Vector__XXX
 SG_ ErrorRegisterVoltage : 18|1@1+ (1,0) [0|0] "" Vector__XXX
 SG_ ErrorRegisterCurrent : 17|1@1+ (1,0) [0|0] "" Vector__XXX
 SG_ ErrorRegisterGeneric : 16|1@1+ (1,0) [0|0] "" Vector__XXX
 SG_ ErrorCode : 0|16@1+ (1,0) [0|0] "" Vector__XXX

BO_ 1815 HBGuard_023: 1 Sensor_1_ID23
 SG_ Toggle : 7|1@1+ (1,0) [0|0] "" Vector__XXX
 SG_ State : 0|7@1+ (1,0) [0|0] "" Vector__XXX

BO_ 258 N23_SRDO1_Inv: 4 Sensor_1_ID23
 SG_ Pressure_1_inverted : 0|32@1- (1,0) [0|1200] "" Vector__XXX

BO_ 257 N23_SRDO1: 4 Sensor_1_ID23
 SG_ Pressure_1 : 0|32@1- (1,0) [0|1200] "" Vector__XXX

BO_ 1431 SSDO_023: 8 Sensor_1_ID23
 SG_ Pressure_1_inverted_6402_02 m2 : 32|32@1- (1,0) [0|1200] "" Vector__XXX
 SG_ Pressure_1_6402_01 m1 : 32|32@1- (1,0) [0|1200] "" Vector__XXX
 SG_ Highest_sub_index_supported_0015 m0 : 32|8@1+ (1,0) [0|255] "" Vector__XXX
 SG_ SubIndex_6402 m25602M : 24|8@1+ (1,0) [0|2] "" Vector__XXX
 SG_ Safety_Checksum_13FF_01 m1 : 32|16@1+ (1,0) [0|65535] "" Vector__XXX
 SG_ Safety_checksum_Number_of_e_0003 m0 : 32|8@1+ (1,0) [0|255] "" Vector__XXX
 SG_ SubIndex_13FF m5119M : 24|8@1+ (1,0) [0|1] "" Vector__XXX
 SG_ Configuration_valid_13FE m0 : 32|8@1+ (1,0) [0|255] "" Vector__XXX
 SG_ SubIndex_13FE m5118M : 24|8@1+ (1,0) [0|0] "" Vector__XXX
 SG_ SRDO1_mapping_inv_Byte1_1381_02 m2 : 32|32@1+ (1,0) [0|4294967295] "" Vector__XXX
 SG_ SRDO1_mapping_Byte1_1381_01 m1 : 32|32@1+ (1,0) [0|4294967295] "" Vector__XXX
 SG_ SRDO1_Number_of_mapped_obje_0003 m0 : 32|8@1+ (1,0) [0|255] "" Vector__XXX
 SG_ SubIndex_1381 m4993M : 24|8@1+ (1,0) [0|2] "" Vector__XXX
 SG_ SRDO1_communication_par_COB_0006 m6 : 32|32@1+ (1,0) [0|4294967295] "" Vector__XXX
 SG_ SRDO1_communication_par_COB_0007 m5 : 32|32@1+ (1,0) [0|4294967295] "" Vector__XXX
 SG_ SRDO1_communication_par_Tra_0003 m4 : 32|8@1+ (1,0) [254|254] "" Vector__XXX
 SG_ SRDO1_communication_par_ref_0003 m2 : 32|16@1+ (1,0) [10|65535] "" Vector__XXX
 SG_ SRDO1_communication_par_Inf_0003 m1 : 32|8@1+ (1,0) [0|1] "" Vector__XXX
 SG_ Highest_sub_index_supported_0016 m0 : 32|8@1+ (1,0) [0|255] "" Vector__XXX
 SG_ SubIndex_1301 m4865M : 24|8@1+ (1,0) [0|6] "" Vector__XXX
 SG_ Serial_number_1018_04 m4 : 32|32@1+ (1,0) [0|4294967295] "" Vector__XXX
 SG_ Revision_number_1018_03 m3 : 32|32@1+ (1,0) [0|4294967295] "" Vector__XXX
 SG_ Product_Code_1018_02 m2 : 32|32@1+ (1,0) [0|4294967295] "" Vector__XXX
 SG_ Vendor_Id_1018_01 m1 : 32|32@1+ (1,0) [0|4294967295] "" Vector__XXX
 SG_ Highest_sub_index_supported_0017 m0 : 32|8@1+ (1,0) [1|4] "" Vector__XXX
 SG_ SubIndex_1018 m4120M : 24|8@1+ (1,0) [0|4] "" Vector__XXX
 SG_ Producer_Heartbeat_Time_1017 m0 : 32|16@1+ (1,0) [0|65535] "" Vector__XXX
 SG_ SubIndex_1017 m4119M : 24|8@1+ (1,0) [0|0] "" Vector__XXX
 SG_ Consumer_Heartbeat_Time16_1_0003 m16 : 32|32@1+ (1,0) [0|4294967295] "" Vector__XXX
 SG_ Consumer_Heartbeat_Time15_1_0003 m15 : 32|32@1+ (1,0) [0|4294967295] "" Vector__XXX
 SG_ Consumer_Heartbeat_Time14_1_0003 m14 : 32|32@1+ (1,0) [0|4294967295] "" Vector__XXX
 SG_ Consumer_Heartbeat_Time13_1_0003 m13 : 32|32@1+ (1,0) [0|4294967295] "" Vector__XXX
 SG_ Consumer_Heartbeat_Time12_1_0003 m12 : 32|32@1+ (1,0) [0|4294967295] "" Vector__XXX
 SG_ Consumer_Heartbeat_Time11_1_0003 m11 : 32|32@1+ (1,0) [0|4294967295] "" Vector__XXX
 SG_ Consumer_Heartbeat_Time10_1_0003 m10 : 32|32@1+ (1,0) [0|4294967295] "" Vector__XXX
 SG_ Consumer_Heartbeat_Time9_1016_09 m9 : 32|32@1+ (1,0) [0|4294967295] "" Vector__XXX
 SG_ Consumer_Heartbeat_Time8_1016_08 m8 : 32|32@1+ (1,0) [0|4294967295] "" Vector__XXX
 SG_ Consumer_Heartbeat_Time7_1016_07 m7 : 32|32@1+ (1,0) [0|4294967295] "" Vector__XXX
 SG_ Consumer_Heartbeat_Time6_1016_06 m6 : 32|32@1+ (1,0) [0|4294967295] "" Vector__XXX
 SG_ Consumer_Heartbeat_Time5_1016_05 m5 : 32|32@1+ (1,0) [0|4294967295] "" Vector__XXX
 SG_ Consumer_Heartbeat_Time4_1016_04 m4 : 32|32@1+ (1,0) [0|4294967295] "" Vector__XXX
 SG_ Consumer_Heartbeat_Time3_1016_03 m3 : 32|32@1+ (1,0) [0|4294967295] "" Vector__XXX
 SG_ Consumer_Heartbeat_Time2_1016_02 m2 : 32|32@1+ (1,0) [0|4294967295] "" Vector__XXX
 SG_ Consumer_Heartbeat_Time1_1016_01 m1 : 32|32@1+ (1,0) [0|4294967295] "" Vector__XXX
 SG_ NrOfObjects_1016_00 m0 : 32|8@1+ (1,0) [0|255] "" Vector__XXX
 SG_ SubIndex_1016 m4118M : 24|8@1+ (1,0) [0|16] "" Vector__XXX
 SG_ COB_ID_EMCY_1014 m0 : 32|32@1+ (1,0) [128|3221225471] "" Vector__XXX
 SG_ SubIndex_1014 m4116M : 24|8@1+ (1,0) [0|0] "" Vector__XXX
 SG_ Restore_all_Default_Paramet_0003 m1 : 32|32@1+ (1,0) [0|4294967295] "" Vector__XXX
 SG_ Highest_sub_index_supported_0018 m0 : 32|8@1+ (1,0) [0|255] "" Vector__XXX
 SG_ SubIndex_1011 m4113M : 24|8@1+ (1,0) [0|1] "" Vector__XXX
 SG_ Save_all_Parameters_1010_01 m1 : 32|32@1+ (1,0) [0|4294967295] "" Vector__XXX
 SG_ Highest_sub_index_supported_0019 m0 : 32|8@1+ (1,0) [0|255] "" Vector__XXX
 SG_ SubIndex_1010 m4112M : 24|8@1+ (1,0) [0|1] "" Vector__XXX
 SG_ Life_Time_Factor_100D m0 : 32|8@1+ (1,0) [0|255] "" Vector__XXX
 SG_ SubIndex_100D m4109M : 24|8@1+ (1,0) [0|0] "" Vector__XXX
 SG_ Guard_Time_100C m0 : 32|16@1+ (1,0) [0|65535] "" Vector__XXX
 SG_ SubIndex_100C m4108M : 24|8@1+ (1,0) [0|0] "" Vector__XXX
 SG_ Sync_Window_Length_1007 m0 : 32|32@1+ (1,0) [0|4294967295] "" Vector__XXX
 SG_ SubIndex_1007 m4103M : 24|8@1+ (1,0) [0|0] "" Vector__XXX
 SG_ Communication_Cycle_Period_1006 m0 : 32|32@1+ (1,0) [0|4294967295] "" Vector__XXX
 SG_ SubIndex_1006 m4102M : 24|8@1+ (1,0) [0|0] "" Vector__XXX
 SG_ COB_ID_SYNC_1005 m0 : 32|32@1+ (1,0) [128|4294967295] "" Vector__XXX
 SG_ SubIndex_1005 m4101M : 24|8@1+ (1,0) [0|0] "" Vector__XXX
 SG_ Standard_error_field_1003_09 m9 : 32|32@1+ (1,0) [0|4294967295] "" Vector__XXX
 SG_ Standard_error_field_1003_08 m8 : 32|32@1+ (1,0) [0|4294967295] "" Vector__XXX
 SG_ Standard_error_field_1003_07 m7 : 32|32@1+ (1,0) [0|4294967295] "" Vector__XXX
 SG_ Standard_error_field_1003_06 m6 : 32|32@1+ (1,0) [0|4294967295] "" Vector__XXX
 SG_ Standard_error_field_1003_05 m5 : 32|32@1+ (1,0) [0|4294967295] "" Vector__XXX
 SG_ Standard_error_field_1003_04 m4 : 32|32@1+ (1,0) [0|4294967295] "" Vector__XXX
 SG_ Standard_error_field_1003_03 m3 : 32|32@1+ (1,0) [0|4294967295] "" Vector__XXX
 SG_ Standard_error_field_1003_02 m2 : 32|32@1+ (1,0) [0|4294967295] "" Vector__XXX
 SG_ Standard_error_field_1003_01 m1 : 32|32@1+ (1,0) [0|4294967295] "" Vector__XXX
 SG_ Number_of_Errors_1003_00 m0 : 32|8@1+ (1,0) [0|255] "" Vector__XXX
 SG_ SubIndex_1003 m4099M : 24|8@1+ (1,0) [0|9] "" Vector__XXX
 SG_ Error_Register_1001 m0 : 32|8@1+ (1,0) [0|255] "" Vector__XXX
 SG_ SubIndex_1001 m4097M : 24|8@1+ (1,0) [0|0] "" Vector__XXX
 SG_ Device_Type_1000 m0 : 32|32@1+ (1,0) [0|4294967295] "" Vector__XXX
 SG_ SubIndex_1000 m4096M : 24|8@1+ (1,0) [0|0] "" Vector__XXX
 SG_ Index m1M : 8|16@1+ (1,0) [4096|25602] "" Vector__XXX
 SG_ TransferType m1M : 1|1@1+ (1,0) [0|1] "" Vector__XXX
 SG_ NotUsedBytes m1 : 2|2@1+ (1,0) [0|3] "" Vector__XXX
 SG_ SizeIndicator m1 : 0|1@1+ (1,0) [0|1] "" Vector__XXX
 SG_ SCS M : 5|3@1+ (1,0) [0|6] "" Vector__XXX

BO_ 1559 CSDO_023: 8 Vector__XXX
 SG_ Pressure_1_inverted_6402_02 m2 : 32|32@1- (1,0) [0|1200] ""  Sensor_1_ID23
 SG_ Pressure_1_6402_01 m1 : 32|32@1- (1,0) [0|1200] ""  Sensor_1_ID23
 SG_ Highest_sub_index_supported_0020 m0 : 32|8@1+ (1,0) [0|255] ""  Sensor_1_ID23
 SG_ SubIndex_6402 m25602M : 24|8@1+ (1,0) [0|2] ""  Sensor_1_ID23
 SG_ Safety_Checksum_13FF_01 m1 : 32|16@1+ (1,0) [0|65535] ""  Sensor_1_ID23
 SG_ Safety_checksum_Number_of_e_0004 m0 : 32|8@1+ (1,0) [0|255] ""  Sensor_1_ID23
 SG_ SubIndex_13FF m5119M : 24|8@1+ (1,0) [0|1] ""  Sensor_1_ID23
 SG_ Configuration_valid_13FE m0 : 32|8@1+ (1,0) [0|255] ""  Sensor_1_ID23
 SG_ SubIndex_13FE m5118M : 24|8@1+ (1,0) [0|0] ""  Sensor_1_ID23
 SG_ SRDO1_mapping_inv_Byte1_1381_02 m2 : 32|32@1+ (1,0) [0|4294967295] ""  Sensor_1_ID23
 SG_ SRDO1_mapping_Byte1_1381_01 m1 : 32|32@1+ (1,0) [0|4294967295] ""  Sensor_1_ID23
 SG_ SRDO1_Number_of_mapped_obje_0004 m0 : 32|8@1+ (1,0) [0|255] ""  Sensor_1_ID23
 SG_ SubIndex_1381 m4993M : 24|8@1+ (1,0) [0|2] ""  Sensor_1_ID23
 SG_ SRDO1_communication_par_COB_0008 m6 : 32|32@1+ (1,0) [0|4294967295] ""  Sensor_1_ID23
 SG_ SRDO1_communication_par_COB_0009 m5 : 32|32@1+ (1,0) [0|4294967295] ""  Sensor_1_ID23
 SG_ SRDO1_communication_par_Tra_0004 m4 : 32|8@1+ (1,0) [254|254] ""  Sensor_1_ID23
 SG_ SRDO1_communication_par_ref_0004 m2 : 32|16@1+ (1,0) [10|65535] ""  Sensor_1_ID23
 SG_ SRDO1_communication_par_Inf_0004 m1 : 32|8@1+ (1,0) [0|1] ""  Sensor_1_ID23
 SG_ Highest_sub_index_supported_0021 m0 : 32|8@1+ (1,0) [0|255] ""  Sensor_1_ID23
 SG_ SubIndex_1301 m4865M : 24|8@1+ (1,0) [0|6] ""  Sensor_1_ID23
 SG_ Serial_number_1018_04 m4 : 32|32@1+ (1,0) [0|4294967295] ""  Sensor_1_ID23
 SG_ Revision_number_1018_03 m3 : 32|32@1+ (1,0) [0|4294967295] ""  Sensor_1_ID23
 SG_ Product_Code_1018_02 m2 : 32|32@1+ (1,0) [0|4294967295] ""  Sensor_1_ID23
 SG_ Vendor_Id_1018_01 m1 : 32|32@1+ (1,0) [0|4294967295] ""  Sensor_1_ID23
 SG_ Highest_sub_index_supported_0022 m0 : 32|8@1+ (1,0) [1|4] ""  Sensor_1_ID23
 SG_ SubIndex_1018 m4120M : 24|8@1+ (1,0) [0|4] ""  Sensor_1_ID23
 SG_ Producer_Heartbeat_Time_1017 m0 : 32|16@1+ (1,0) [0|65535] ""  Sensor_1_ID23
 SG_ SubIndex_1017 m4119M : 24|8@1+ (1,0) [0|0] ""  Sensor_1_ID23
 SG_ Consumer_Heartbeat_Time16_1_0004 m16 : 32|32@1+ (1,0) [0|4294967295] ""  Sensor_1_ID23
 SG_ Consumer_Heartbeat_Time15_1_0004 m15 : 32|32@1+ (1,0) [0|4294967295] ""  Sensor_1_ID23
 SG_ Consumer_Heartbeat_Time14_1_0004 m14 : 32|32@1+ (1,0) [0|4294967295] ""  Sensor_1_ID23
 SG_ Consumer_Heartbeat_Time13_1_0004 m13 : 32|32@1+ (1,0) [0|4294967295] ""  Sensor_1_ID23
 SG_ Consumer_Heartbeat_Time12_1_0004 m12 : 32|32@1+ (1,0) [0|4294967295] ""  Sensor_1_ID23
 SG_ Consumer_Heartbeat_Time11_1_0004 m11 : 32|32@1+ (1,0) [0|4294967295] ""  Sensor_1_ID23
 SG_ Consumer_Heartbeat_Time10_1_0004 m10 : 32|32@1+ (1,0) [0|4294967295] ""  Sensor_1_ID23
 SG_ Consumer_Heartbeat_Time9_1016_09 m9 : 32|32@1+ (1,0) [0|4294967295] ""  Sensor_1_ID23
 SG_ Consumer_Heartbeat_Time8_1016_08 m8 : 32|32@1+ (1,0) [0|4294967295] ""  Sensor_1_ID23
 SG_ Consumer_Heartbeat_Time7_1016_07 m7 : 32|32@1+ (1,0) [0|4294967295] ""  Sensor_1_ID23
 SG_ Consumer_Heartbeat_Time6_1016_06 m6 : 32|32@1+ (1,0) [0|4294967295] ""  Sensor_1_ID23
 SG_ Consumer_Heartbeat_Time5_1016_05 m5 : 32|32@1+ (1,0) [0|4294967295] ""  Sensor_1_ID23
 SG_ Consumer_Heartbeat_Time4_1016_04 m4 : 32|32@1+ (1,0) [0|4294967295] ""  Sensor_1_ID23
 SG_ Consumer_Heartbeat_Time3_1016_03 m3 : 32|32@1+ (1,0) [0|4294967295] ""  Sensor_1_ID23
 SG_ Consumer_Heartbeat_Time2_1016_02 m2 : 32|32@1+ (1,0) [0|4294967295] ""  Sensor_1_ID23
 SG_ Consumer_Heartbeat_Time1_1016_01 m1 : 32|32@1+ (1,0) [0|4294967295] ""  Sensor_1_ID23
 SG_ NrOfObjects_1016_00 m0 : 32|8@1+ (1,0) [0|255] ""  Sensor_1_ID23
 SG_ SubIndex_1016 m4118M : 24|8@1+ (1,0) [0|16] ""  Sensor_1_ID23
 SG_ COB_ID_EMCY_1014 m0 : 32|32@1+ (1,0) [128|3221225471] ""  Sensor_1_ID23
 SG_ SubIndex_1014 m4116M : 24|8@1+ (1,0) [0|0] ""  Sensor_1_ID23
 SG_ Restore_all_Default_Paramet_0004 m1 : 32|32@1+ (1,0) [0|4294967295] ""  Sensor_1_ID23
 SG_ Highest_sub_index_supported_0023 m0 : 32|8@1+ (1,0) [0|255] ""  Sensor_1_ID23
 SG_ SubIndex_1011 m4113M : 24|8@1+ (1,0) [0|1] ""  Sensor_1_ID23
 SG_ Save_all_Parameters_1010_01 m1 : 32|32@1+ (1,0) [0|4294967295] ""  Sensor_1_ID23
 SG_ Highest_sub_index_supported_0024 m0 : 32|8@1+ (1,0) [0|255] ""  Sensor_1_ID23
 SG_ SubIndex_1010 m4112M : 24|8@1+ (1,0) [0|1] ""  Sensor_1_ID23
 SG_ Life_Time_Factor_100D m0 : 32|8@1+ (1,0) [0|255] ""  Sensor_1_ID23
 SG_ SubIndex_100D m4109M : 24|8@1+ (1,0) [0|0] ""  Sensor_1_ID23
 SG_ Guard_Time_100C m0 : 32|16@1+ (1,0) [0|65535] ""  Sensor_1_ID23
 SG_ SubIndex_100C m4108M : 24|8@1+ (1,0) [0|0] ""  Sensor_1_ID23
 SG_ Sync_Window_Length_1007 m0 : 32|32@1+ (1,0) [0|4294967295] ""  Sensor_1_ID23
 SG_ SubIndex_1007 m4103M : 24|8@1+ (1,0) [0|0] ""  Sensor_1_ID23
 SG_ Communication_Cycle_Period_1006 m0 : 32|32@1+ (1,0) [0|4294967295] ""  Sensor_1_ID23
 SG_ SubIndex_1006 m4102M : 24|8@1+ (1,0) [0|0] ""  Sensor_1_ID23
 SG_ COB_ID_SYNC_1005 m0 : 32|32@1+ (1,0) [128|4294967295] ""  Sensor_1_ID23
 SG_ SubIndex_1005 m4101M : 24|8@1+ (1,0) [0|0] ""  Sensor_1_ID23
 SG_ Standard_error_field_1003_09 m9 : 32|32@1+ (1,0) [0|4294967295] ""  Sensor_1_ID23
 SG_ Standard_error_field_1003_08 m8 : 32|32@1+ (1,0) [0|4294967295] ""  Sensor_1_ID23
 SG_ Standard_error_field_1003_07 m7 : 32|32@1+ (1,0) [0|4294967295] ""  Sensor_1_ID23
 SG_ Standard_error_field_1003_06 m6 : 32|32@1+ (1,0) [0|4294967295] ""  Sensor_1_ID23
 SG_ Standard_error_field_1003_05 m5 : 32|32@1+ (1,0) [0|4294967295] ""  Sensor_1_ID23
 SG_ Standard_error_field_1003_04 m4 : 32|32@1+ (1,0) [0|4294967295] ""  Sensor_1_ID23
 SG_ Standard_error_field_1003_03 m3 : 32|32@1+ (1,0) [0|4294967295] ""  Sensor_1_ID23
 SG_ Standard_error_field_1003_02 m2 : 32|32@1+ (1,0) [0|4294967295] ""  Sensor_1_ID23
 SG_ Standard_error_field_1003_01 m1 : 32|32@1+ (1,0) [0|4294967295] ""  Sensor_1_ID23
 SG_ Number_of_Errors_1003_00 m0 : 32|8@1+ (1,0) [0|255] ""  Sensor_1_ID23
 SG_ SubIndex_1003 m4099M : 24|8@1+ (1,0) [0|9] ""  Sensor_1_ID23
 SG_ Error_Register_1001 m0 : 32|8@1+ (1,0) [0|255] ""  Sensor_1_ID23
 SG_ SubIndex_1001 m4097M : 24|8@1+ (1,0) [0|0] ""  Sensor_1_ID23
 SG_ Device_Type_1000 m0 : 32|32@1+ (1,0) [0|4294967295] ""  Sensor_1_ID23
 SG_ SubIndex_1000 m4096M : 24|8@1+ (1,0) [0|0] ""  Sensor_1_ID23
 SG_ Index m1M : 8|16@1+ (1,0) [4096|25602] ""  Sensor_1_ID23
 SG_ TransferType m1M : 1|1@1+ (1,0) [0|1] ""  Sensor_1_ID23
 SG_ NotUsedBytes m1 : 2|2@1+ (1,0) [0|3] ""  Sensor_1_ID23
 SG_ SizeIndicator m1 : 0|1@1+ (1,0) [0|1] ""  Sensor_1_ID23
 SG_ CCS M : 5|3@1+ (1,0) [0|6] ""  Sensor_1_ID23

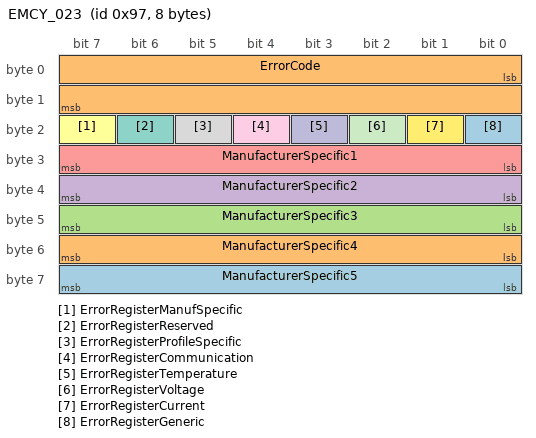
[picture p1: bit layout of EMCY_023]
BO_ 151 EMCY_023: 8 Sensor_1_ID23
 SG_ ManufacturerSpecific5 : 56|8@1+ (1,0) [0|0] "" Vector__XXX
 SG_ ManufacturerSpecific4 : 48|8@1+ (1,0) [0|0] "" Vector__XXX
 SG_ ManufacturerSpecific3 : 40|8@1+ (1,0) [0|0] "" Vector__XXX
 SG_ ManufacturerSpecific2 : 32|8@1+ (1,0) [0|0] "" Vector__XXX
 SG_ ManufacturerSpecific1 : 24|8@1+ (1,0) [0|0] "" Vector__XXX
 SG_ ErrorRegisterManufSpecific : 23|1@1+ (1,0) [0|0] "" Vector__XXX
 SG_ ErrorRegisterReserved : 22|1@1+ (1,0) [0|0] "" Vector__XXX
 SG_ ErrorRegisterProfileSpecific : 21|1@1+ (1,0) [0|0] "" Vector__XXX
 SG_ ErrorRegisterCommunication : 20|1@1+ (1,0) [0|0] "" Vector__XXX
 SG_ ErrorRegisterTemperature : 19|1@1+ (1,0) [0|0] "" Vector__XXX
 SG_ ErrorRegisterVoltage : 18|1@1+ (1,0) [0|0] "" Vector__XXX
 SG_ ErrorRegisterCurrent : 17|1@1+ (1,0) [0|0] "" Vector__XXX
 SG_ ErrorRegisterGeneric : 16|1@1+ (1,0) [0|0] "" Vector__XXX
 SG_ ErrorCode : 0|16@1+ (1,0) [0|0] "" Vector__XXX

BO_ 128 SYNC_010: 0 Vector__XXX

BO_ 1802 HBGuard_010: 1 Display_ID10
 SG_ Toggle : 7|1@1+ (1,0) [0|0] "" Vector__XXX
 SG_ State : 0|7@1+ (1,0) [0|0] "" Vector__XXX

BO_ 1418 SSDO_010: 8 Display_ID10
 SG_ UInt32_2_A643_03 m3 : 32|32@1+ (1,0) [0|4294967295] "" Vector__XXX
 SG_ UInt32_2_A643_02 m2 : 32|32@1+ (1,0) [0|4294967295] "" Vector__XXX
 SG_ UInt32_1_A643_01 m1 : 32|32@1+ (1,0) [0|4294967295] "" Vector__XXX
 SG_ NrOfObjects_A643_00 m0 : 32|8@1+ (1,0) [0|255] "" Vector__XXX
 SG_ SubIndex_A643 m42563M : 24|8@1+ (1,0) [0|3] "" Vector__XXX
 SG_ Int16_2_A642_03 m3 : 32|16@1- (1,0) [-32768|32767] "" Vector__XXX
 SG_ Int16_2_A642_02 m2 : 32|16@1- (1,0) [-32768|32767] "" Vector__XXX
 SG_ Int16_1_A642_01 m1 : 32|16@1- (1,0) [-32768|32767] "" Vector__XXX
 SG_ NrOfObjects_A642_00 m0 : 32|8@1+ (1,0) [0|255] "" Vector__XXX
 SG_ SubIndex_A642 m42562M : 24|8@1+ (1,0) [0|3] "" Vector__XXX
 SG_ Pressure_1_Sensor3_Inverted_A641 m3 : 32|32@1- (1,0) [-2147483648|2147483647] "" Vector__XXX
 SG_ Pressure_1_Sensor2_Inverted_A641 m2 : 32|32@1- (1,0) [-2147483648|2147483647] "" Vector__XXX
 SG_ Pressure_1_Sensor1_Inverted_A641 m1 : 32|32@1- (1,0) [-2147483648|2147483647] "" Vector__XXX
 SG_ NrOfObjects_A641_00 m0 : 32|8@1+ (1,0) [0|255] "" Vector__XXX
 SG_ SubIndex_A641 m42561M : 24|8@1+ (1,0) [0|3] "" Vector__XXX
 SG_ Pressure_1_Sensor3_A640_03 m3 : 32|32@1- (1,0) [-2147483648|2147483647] "" Vector__XXX
 SG_ Pressure_1_Sensor2_A640_02 m2 : 32|32@1- (1,0) [-2147483648|2147483647] "" Vector__XXX
 SG_ Pressure_1_Sensor1_A640_01 m1 : 32|32@1- (1,0) [-2147483648|2147483647] "" Vector__XXX
 SG_ NrOfObjects_A640_00 m0 : 32|8@1+ (1,0) [0|255] "" Vector__XXX
 SG_ SubIndex_A640 m42560M : 24|8@1+ (1,0) [0|3] "" Vector__XXX
 SG_ BootTime_1F89 m0 : 32|32@1+ (1,0) [0|4294967295] "" Vector__XXX
 SG_ SubIndex_1F89 m8073M : 24|8@1+ (1,0) [0|0] "" Vector__XXX
 SG_ SerialNumber127_1F88_7F m127 : 32|32@1+ (1,0) [0|4294967295] "" Vector__XXX
 SG_ SerialNumber126_1F88_7E m126 : 32|32@1+ (1,0) [0|4294967295] "" Vector__XXX
 SG_ SerialNumber125_1F88_7D m125 : 32|32@1+ (1,0) [0|4294967295] "" Vector__XXX
 SG_ SerialNumber124_1F88_7C m124 : 32|32@1+ (1,0) [0|4294967295] "" Vector__XXX
 SG_ SerialNumber123_1F88_7B m123 : 32|32@1+ (1,0) [0|4294967295] "" Vector__XXX
 SG_ SerialNumber122_1F88_7A m122 : 32|32@1+ (1,0) [0|4294967295] "" Vector__XXX
 SG_ SerialNumber121_1F88_79 m121 : 32|32@1+ (1,0) [0|4294967295] "" Vector__XXX
 SG_ SerialNumber120_1F88_78 m120 : 32|32@1+ (1,0) [0|4294967295] "" Vector__XXX
 SG_ SerialNumber119_1F88_77 m119 : 32|32@1+ (1,0) [0|4294967295] "" Vector__XXX
 SG_ SerialNumber118_1F88_76 m118 : 32|32@1+ (1,0) [0|4294967295] "" Vector__XXX
 SG_ SerialNumber117_1F88_75 m117 : 32|32@1+ (1,0) [0|4294967295] "" Vector__XXX
 SG_ SerialNumber116_1F88_74 m116 : 32|32@1+ (1,0) [0|4294967295] "" Vector__XXX
 SG_ SerialNumber115_1F88_73 m115 : 32|32@1+ (1,0) [0|4294967295] "" Vector__XXX
 SG_ SerialNumber114_1F88_72 m114 : 32|32@1+ (1,0) [0|4294967295] "" Vector__XXX
 SG_ SerialNumber113_1F88_71 m113 : 32|32@1+ (1,0) [0|4294967295] "" Vector__XXX
 SG_ SerialNumber112_1F88_70 m112 : 32|32@1+ (1,0) [0|4294967295] "" Vector__XXX
 SG_ SerialNumber111_1F88_6F m111 : 32|32@1+ (1,0) [0|4294967295] "" Vector__XXX
 SG_ SerialNumber110_1F88_6E m110 : 32|32@1+ (1,0) [0|4294967295] "" Vector__XXX
 SG_ SerialNumber109_1F88_6D m109 : 32|32@1+ (1,0) [0|4294967295] "" Vector__XXX
 SG_ SerialNumber108_1F88_6C m108 : 32|32@1+ (1,0) [0|4294967295] "" Vector__XXX
 SG_ SerialNumber107_1F88_6B m107 : 32|32@1+ (1,0) [0|4294967295] "" Vector__XXX
 SG_ SerialNumber106_1F88_6A m106 : 32|32@1+ (1,0) [0|4294967295] "" Vector__XXX
 SG_ SerialNumber105_1F88_69 m105 : 32|32@1+ (1,0) [0|4294967295] "" Vector__XXX
 SG_ SerialNumber104_1F88_68 m104 : 32|32@1+ (1,0) [0|4294967295] "" Vector__XXX
 SG_ SerialNumber103_1F88_67 m103 : 32|32@1+ (1,0) [0|4294967295] "" Vector__XXX
 SG_ SerialNumber102_1F88_66 m102 : 32|32@1+ (1,0) [0|4294967295] "" Vector__XXX
 SG_ SerialNumber101_1F88_65 m101 : 32|32@1+ (1,0) [0|4294967295] "" Vector__XXX
 SG_ SerialNumber100_1F88_64 m100 : 32|32@1+ (1,0) [0|4294967295] "" Vector__XXX
 SG_ SerialNumber99_1F88_63 m99 : 32|32@1+ (1,0) [0|4294967295] "" Vector__XXX
 SG_ SerialNumber98_1F88_62 m98 : 32|32@1+ (1,0) [0|4294967295] "" Vector__XXX
 SG_ SerialNumber97_1F88_61 m97 : 32|32@1+ (1,0) [0|4294967295] "" Vector__XXX
 SG_ SerialNumber96_1F88_60 m96 : 32|32@1+ (1,0) [0|4294967295] "" Vector__XXX
 SG_ SerialNumber95_1F88_5F m95 : 32|32@1+ (1,0) [0|4294967295] "" Vector__XXX
 SG_ SerialNumber94_1F88_5E m94 : 32|32@1+ (1,0) [0|4294967295] "" Vector__XXX
 SG_ SerialNumber93_1F88_5D m93 : 32|32@1+ (1,0) [0|4294967295] "" Vector__XXX
 SG_ SerialNumber92_1F88_5C m92 : 32|32@1+ (1,0) [0|4294967295] "" Vector__XXX
 SG_ SerialNumber91_1F88_5B m91 : 32|32@1+ (1,0) [0|4294967295] "" Vector__XXX
 SG_ SerialNumber90_1F88_5A m90 : 32|32@1+ (1,0) [0|4294967295] "" Vector__XXX
 SG_ SerialNumber89_1F88_59 m89 : 32|32@1+ (1,0) [0|4294967295] "" Vector__XXX
 SG_ SerialNumber88_1F88_58 m88 : 32|32@1+ (1,0) [0|4294967295] "" Vector__XXX
 SG_ SerialNumber87_1F88_57 m87 : 32|32@1+ (1,0) [0|4294967295] "" Vector__XXX
 SG_ SerialNumber86_1F88_56 m86 : 32|32@1+ (1,0) [0|4294967295] "" Vector__XXX
 SG_ SerialNumber85_1F88_55 m85 : 32|32@1+ (1,0) [0|4294967295] "" Vector__XXX
 SG_ SerialNumber84_1F88_54 m84 : 32|32@1+ (1,0) [0|4294967295] "" Vector__XXX
 SG_ SerialNumber83_1F88_53 m83 : 32|32@1+ (1,0) [0|4294967295] "" Vector__XXX
 SG_ SerialNumber82_1F88_52 m82 : 32|32@1+ (1,0) [0|4294967295] "" Vector__XXX
 SG_ SerialNumber81_1F88_51 m81 : 32|32@1+ (1,0) [0|4294967295] "" Vector__XXX
 SG_ SerialNumber80_1F88_50 m80 : 32|32@1+ (1,0) [0|4294967295] "" Vector__XXX
 SG_ SerialNumber79_1F88_4F m79 : 32|32@1+ (1,0) [0|4294967295] "" Vector__XXX
 SG_ SerialNumber78_1F88_4E m78 : 32|32@1+ (1,0) [0|4294967295] "" Vector__XXX
 SG_ SerialNumber77_1F88_4D m77 : 32|32@1+ (1,0) [0|4294967295] "" Vector__XXX
 SG_ SerialNumber76_1F88_4C m76 : 32|32@1+ (1,0) [0|4294967295] "" Vector__XXX
 SG_ SerialNumber75_1F88_4B m75 : 32|32@1+ (1,0) [0|4294967295] "" Vector__XXX
 SG_ SerialNumber74_1F88_4A m74 : 32|32@1+ (1,0) [0|4294967295] "" Vector__XXX
 SG_ SerialNumber73_1F88_49 m73 : 32|32@1+ (1,0) [0|4294967295] "" Vector__XXX
 SG_ SerialNumber72_1F88_48 m72 : 32|32@1+ (1,0) [0|4294967295] "" Vector__XXX
 SG_ SerialNumber71_1F88_47 m71 : 32|32@1+ (1,0) [0|4294967295] "" Vector__XXX
 SG_ SerialNumber70_1F88_46 m70 : 32|32@1+ (1,0) [0|4294967295] "" Vector__XXX
 SG_ SerialNumber69_1F88_45 m69 : 32|32@1+ (1,0) [0|4294967295] "" Vector__XXX
 SG_ SerialNumber68_1F88_44 m68 : 32|32@1+ (1,0) [0|4294967295] "" Vector__XXX
 SG_ SerialNumber67_1F88_43 m67 : 32|32@1+ (1,0) [0|4294967295] "" Vector__XXX
 SG_ SerialNumber66_1F88_42 m66 : 32|32@1+ (1,0) [0|4294967295] "" Vector__XXX
 SG_ SerialNumber65_1F88_41 m65 : 32|32@1+ (1,0) [0|4294967295] "" Vector__XXX
 SG_ SerialNumber64_1F88_40 m64 : 32|32@1+ (1,0) [0|4294967295] "" Vector__XXX
 SG_ SerialNumber63_1F88_3F m63 : 32|32@1+ (1,0) [0|4294967295] "" Vector__XXX
 SG_ SerialNumber62_1F88_3E m62 : 32|32@1+ (1,0) [0|4294967295] "" Vector__XXX
 SG_ SerialNumber61_1F88_3D m61 : 32|32@1+ (1,0) [0|4294967295] "" Vector__XXX
 SG_ SerialNumber60_1F88_3C m60 : 32|32@1+ (1,0) [0|4294967295] "" Vector__XXX
 SG_ SerialNumber59_1F88_3B m59 : 32|32@1+ (1,0) [0|4294967295] "" Vector__XXX
 SG_ SerialNumber58_1F88_3A m58 : 32|32@1+ (1,0) [0|4294967295] "" Vector__XXX
 SG_ SerialNumber57_1F88_39 m57 : 32|32@1+ (1,0) [0|4294967295] "" Vector__XXX
 SG_ SerialNumber56_1F88_38 m56 : 32|32@1+ (1,0) [0|4294967295] "" Vector__XXX
 SG_ SerialNumber55_1F88_37 m55 : 32|32@1+ (1,0) [0|4294967295] "" Vector__XXX
 SG_ SerialNumber54_1F88_36 m54 : 32|32@1+ (1,0) [0|4294967295] "" Vector__XXX
 SG_ SerialNumber53_1F88_35 m53 : 32|32@1+ (1,0) [0|4294967295] "" Vector__XXX
 SG_ SerialNumber52_1F88_34 m52 : 32|32@1+ (1,0) [0|4294967295] "" Vector__XXX
 SG_ SerialNumber51_1F88_33 m51 : 32|32@1+ (1,0) [0|4294967295] "" Vector__XXX
 SG_ SerialNumber50_1F88_32 m50 : 32|32@1+ (1,0) [0|4294967295] "" Vector__XXX
 SG_ SerialNumber49_1F88_31 m49 : 32|32@1+ (1,0) [0|4294967295] "" Vector__XXX
 SG_ SerialNumber48_1F88_30 m48 : 32|32@1+ (1,0) [0|4294967295] "" Vector__XXX
 SG_ SerialNumber47_1F88_2F m47 : 32|32@1+ (1,0) [0|4294967295] "" Vector__XXX
 SG_ SerialNumber46_1F88_2E m46 : 32|32@1+ (1,0) [0|4294967295] "" Vector__XXX
 SG_ SerialNumber45_1F88_2D m45 : 32|32@1+ (1,0) [0|4294967295] "" Vector__XXX
 SG_ SerialNumber44_1F88_2C m44 : 32|32@1+ (1,0) [0|4294967295] "" Vector__XXX
 SG_ SerialNumber43_1F88_2B m43 : 32|32@1+ (1,0) [0|4294967295] "" Vector__XXX
 SG_ SerialNumber42_1F88_2A m42 : 32|32@1+ (1,0) [0|4294967295] "" Vector__XXX
 SG_ SerialNumber41_1F88_29 m41 : 32|32@1+ (1,0) [0|4294967295] "" Vector__XXX
 SG_ SerialNumber40_1F88_28 m40 : 32|32@1+ (1,0) [0|4294967295] "" Vector__XXX
 SG_ SerialNumber39_1F88_27 m39 : 32|32@1+ (1,0) [0|4294967295] "" Vector__XXX
 SG_ SerialNumber38_1F88_26 m38 : 32|32@1+ (1,0) [0|4294967295] "" Vector__XXX
 SG_ SerialNumber37_1F88_25 m37 : 32|32@1+ (1,0) [0|4294967295] "" Vector__XXX
 SG_ SerialNumber36_1F88_24 m36 : 32|32@1+ (1,0) [0|4294967295] "" Vector__XXX
 SG_ SerialNumber35_1F88_23 m35 : 32|32@1+ (1,0) [0|4294967295] "" Vector__XXX
 SG_ SerialNumber34_1F88_22 m34 : 32|32@1+ (1,0) [0|4294967295] "" Vector__XXX
 SG_ SerialNumber33_1F88_21 m33 : 32|32@1+ (1,0) [0|4294967295] "" Vector__XXX
 SG_ SerialNumber32_1F88_20 m32 : 32|32@1+ (1,0) [0|4294967295] "" Vector__XXX
 SG_ SerialNumber31_1F88_1F m31 : 32|32@1+ (1,0) [0|4294967295] "" Vector__XXX
 SG_ SerialNumber30_1F88_1E m30 : 32|32@1+ (1,0) [0|4294967295] "" Vector__XXX
 SG_ SerialNumber29_1F88_1D m29 : 32|32@1+ (1,0) [0|4294967295] "" Vector__XXX
 SG_ SerialNumber28_1F88_1C m28 : 32|32@1+ (1,0) [0|4294967295] "" Vector__XXX
 SG_ SerialNumber27_1F88_1B m27 : 32|32@1+ (1,0) [0|4294967295] "" Vector__XXX
 SG_ SerialNumber26_1F88_1A m26 : 32|32@1+ (1,0) [0|4294967295] "" Vector__XXX
 SG_ SerialNumber25_1F88_19 m25 : 32|32@1+ (1,0) [0|4294967295] "" Vector__XXX
 SG_ SerialNumber24_1F88_18 m24 : 32|32@1+ (1,0) [0|4294967295] "" Vector__XXX
 SG_ SerialNumber23_1F88_17 m23 : 32|32@1+ (1,0) [0|4294967295] "" Vector__XXX
 SG_ SerialNumber22_1F88_16 m22 : 32|32@1+ (1,0) [0|4294967295] "" Vector__XXX
 SG_ SerialNumber21_1F88_15 m21 : 32|32@1+ (1,0) [0|4294967295] "" Vector__XXX
 SG_ SerialNumber20_1F88_14 m20 : 32|32@1+ (1,0) [0|4294967295] "" Vector__XXX
 SG_ SerialNumber19_1F88_13 m19 : 32|32@1+ (1,0) [0|4294967295] "" Vector__XXX
 SG_ SerialNumber18_1F88_12 m18 : 32|32@1+ (1,0) [0|4294967295] "" Vector__XXX
 SG_ SerialNumber17_1F88_11 m17 : 32|32@1+ (1,0) [0|4294967295] "" Vector__XXX
 SG_ SerialNumber16_1F88_10 m16 : 32|32@1+ (1,0) [0|4294967295] "" Vector__XXX
 SG_ SerialNumber15_1F88_0F m15 : 32|32@1+ (1,0) [0|4294967295] "" Vector__XXX
 SG_ SerialNumber14_1F88_0E m14 : 32|32@1+ (1,0) [0|4294967295] "" Vector__XXX
 SG_ SerialNumber13_1F88_0D m13 : 32|32@1+ (1,0) [0|4294967295] "" Vector__XXX
 SG_ SerialNumber12_1F88_0C m12 : 32|32@1+ (1,0) [0|4294967295] "" Vector__XXX
 SG_ SerialNumber11_1F88_0B m11 : 32|32@1+ (1,0) [0|4294967295] "" Vector__XXX
 SG_ SerialNumber10_1F88_0A m10 : 32|32@1+ (1,0) [0|4294967295] "" Vector__XXX
 SG_ SerialNumber9_1F88_09 m9 : 32|32@1+ (1,0) [0|4294967295] "" Vector__XXX
 SG_ SerialNumber8_1F88_08 m8 : 32|32@1+ (1,0) [0|4294967295] "" Vector__XXX
 SG_ SerialNumber7_1F88_07 m7 : 32|32@1+ (1,0) [0|4294967295] "" Vector__XXX
 SG_ SerialNumber6_1F88_06 m6 : 32|32@1+ (1,0) [0|4294967295] "" Vector__XXX
 SG_ SerialNumber5_1F88_05 m5 : 32|32@1+ (1,0) [0|4294967295] "" Vector__XXX
 SG_ SerialNumber4_1F88_04 m4 : 32|32@1+ (1,0) [0|4294967295] "" Vector__XXX
 SG_ SerialNumber3_1F88_03 m3 : 32|32@1+ (1,0) [0|4294967295] "" Vector__XXX
 SG_ SerialNumber2_1F88_02 m2 : 32|32@1+ (1,0) [0|4294967295] "" Vector__XXX
 SG_ SerialNumber1_1F88_01 m1 : 32|32@1+ (1,0) [0|4294967295] "" Vector__XXX
 SG_ NrOfObjects_1F88_00 m0 : 32|8@1+ (1,0) [0|255] "" Vector__XXX
 SG_ SubIndex_1F88 m8072M : 24|8@1+ (1,0) [0|127] "" Vector__XXX
 SG_ RevisionNumber127_1F87_7F m127 : 32|32@1+ (1,0) [0|4294967295] "" Vector__XXX
 SG_ RevisionNumber126_1F87_7E m126 : 32|32@1+ (1,0) [0|4294967295] "" Vector__XXX
 SG_ RevisionNumber125_1F87_7D m125 : 32|32@1+ (1,0) [0|4294967295] "" Vector__XXX
 SG_ RevisionNumber124_1F87_7C m124 : 32|32@1+ (1,0) [0|4294967295] "" Vector__XXX
 SG_ RevisionNumber123_1F87_7B m123 : 32|32@1+ (1,0) [0|4294967295] "" Vector__XXX
 SG_ RevisionNumber122_1F87_7A m122 : 32|32@1+ (1,0) [0|4294967295] "" Vector__XXX
 SG_ RevisionNumber121_1F87_79 m121 : 32|32@1+ (1,0) [0|4294967295] "" Vector__XXX
 SG_ RevisionNumber120_1F87_78 m120 : 32|32@1+ (1,0) [0|4294967295] "" Vector__XXX
 SG_ RevisionNumber119_1F87_77 m119 : 32|32@1+ (1,0) [0|4294967295] "" Vector__XXX
 SG_ RevisionNumber118_1F87_76 m118 : 32|32@1+ (1,0) [0|4294967295] "" Vector__XXX
 SG_ RevisionNumber117_1F87_75 m117 : 32|32@1+ (1,0) [0|4294967295] "" Vector__XXX
 SG_ RevisionNumber116_1F87_74 m116 : 32|32@1+ (1,0) [0|4294967295] "" Vector__XXX
 SG_ RevisionNumber115_1F87_73 m115 : 32|32@1+ (1,0) [0|4294967295] "" Vector__XXX
 SG_ RevisionNumber114_1F87_72 m114 : 32|32@1+ (1,0) [0|4294967295] "" Vector__XXX
 SG_ RevisionNumber113_1F87_71 m113 : 32|32@1+ (1,0) [0|4294967295] "" Vector__XXX
 SG_ RevisionNumber112_1F87_70 m112 : 32|32@1+ (1,0) [0|4294967295] "" Vector__XXX
 SG_ RevisionNumber111_1F87_6F m111 : 32|32@1+ (1,0) [0|4294967295] "" Vector__XXX
 SG_ RevisionNumber110_1F87_6E m110 : 32|32@1+ (1,0) [0|4294967295] "" Vector__XXX
 SG_ RevisionNumber109_1F87_6D m109 : 32|32@1+ (1,0) [0|4294967295] "" Vector__XXX
 SG_ RevisionNumber108_1F87_6C m108 : 32|32@1+ (1,0) [0|4294967295] "" Vector__XXX
 SG_ RevisionNumber107_1F87_6B m107 : 32|32@1+ (1,0) [0|4294967295] "" Vector__XXX
 SG_ RevisionNumber106_1F87_6A m106 : 32|32@1+ (1,0) [0|4294967295] "" Vector__XXX
 SG_ RevisionNumber105_1F87_69 m105 : 32|32@1+ (1,0) [0|4294967295] "" Vector__XXX
 SG_ RevisionNumber104_1F87_68 m104 : 32|32@1+ (1,0) [0|4294967295] "" Vector__XXX
 SG_ RevisionNumber103_1F87_67 m103 : 32|32@1+ (1,0) [0|4294967295] "" Vector__XXX
 SG_ RevisionNumber102_1F87_66 m102 : 32|32@1+ (1,0) [0|4294967295] "" Vector__XXX
 SG_ RevisionNumber101_1F87_65 m101 : 32|32@1+ (1,0) [0|4294967295] "" Vector__XXX
 SG_ RevisionNumber100_1F87_64 m100 : 32|32@1+ (1,0) [0|4294967295] "" Vector__XXX
 SG_ RevisionNumber99_1F87_63 m99 : 32|32@1+ (1,0) [0|4294967295] "" Vector__XXX
 SG_ RevisionNumber98_1F87_62 m98 : 32|32@1+ (1,0) [0|4294967295] "" Vector__XXX
 SG_ RevisionNumber97_1F87_61 m97 : 32|32@1+ (1,0) [0|4294967295] "" Vector__XXX
 SG_ RevisionNumber96_1F87_60 m96 : 32|32@1+ (1,0) [0|4294967295] "" Vector__XXX
 SG_ RevisionNumber95_1F87_5F m95 : 32|32@1+ (1,0) [0|4294967295] "" Vector__XXX
 SG_ RevisionNumber94_1F87_5E m94 : 32|32@1+ (1,0) [0|4294967295] "" Vector__XXX
 SG_ RevisionNumber93_1F87_5D m93 : 32|32@1+ (1,0) [0|4294967295] "" Vector__XXX
 SG_ RevisionNumber92_1F87_5C m92 : 32|32@1+ (1,0) [0|4294967295] "" Vector__XXX
 SG_ RevisionNumber91_1F87_5B m91 : 32|32@1+ (1,0) [0|4294967295] "" Vector__XXX
 SG_ RevisionNumber90_1F87_5A m90 : 32|32@1+ (1,0) [0|4294967295] "" Vector__XXX
 SG_ RevisionNumber89_1F87_59 m89 : 32|32@1+ (1,0) [0|4294967295] "" Vector__XXX
 SG_ RevisionNumber88_1F87_58 m88 : 32|32@1+ (1,0) [0|4294967295] "" Vector__XXX
 SG_ RevisionNumber87_1F87_57 m87 : 32|32@1+ (1,0) [0|4294967295] "" Vector__XXX
 SG_ RevisionNumber86_1F87_56 m86 : 32|32@1+ (1,0) [0|4294967295] "" Vector__XXX
 SG_ RevisionNumber85_1F87_55 m85 : 32|32@1+ (1,0) [0|4294967295] "" Vector__XXX
 SG_ RevisionNumber84_1F87_54 m84 : 32|32@1+ (1,0) [0|4294967295] "" Vector__XXX
 SG_ RevisionNumber83_1F87_53 m83 : 32|32@1+ (1,0) [0|4294967295] "" Vector__XXX
 SG_ RevisionNumber82_1F87_52 m82 : 32|32@1+ (1,0) [0|4294967295] "" Vector__XXX
 SG_ RevisionNumber81_1F87_51 m81 : 32|32@1+ (1,0) [0|4294967295] "" Vector__XXX
 SG_ RevisionNumber80_1F87_50 m80 : 32|32@1+ (1,0) [0|4294967295] "" Vector__XXX
 SG_ RevisionNumber79_1F87_4F m79 : 32|32@1+ (1,0) [0|4294967295] "" Vector__XXX
 SG_ RevisionNumber78_1F87_4E m78 : 32|32@1+ (1,0) [0|4294967295] "" Vector__XXX
 SG_ RevisionNumber77_1F87_4D m77 : 32|32@1+ (1,0) [0|4294967295] "" Vector__XXX
 SG_ RevisionNumber76_1F87_4C m76 : 32|32@1+ (1,0) [0|4294967295] "" Vector__XXX
 SG_ RevisionNumber75_1F87_4B m75 : 32|32@1+ (1,0) [0|4294967295] "" Vector__XXX
 SG_ RevisionNumber74_1F87_4A m74 : 32|32@1+ (1,0) [0|4294967295] "" Vector__XXX
 SG_ RevisionNumber73_1F87_49 m73 : 32|32@1+ (1,0) [0|4294967295] "" Vector__XXX
 SG_ RevisionNumber72_1F87_48 m72 : 32|32@1+ (1,0) [0|4294967295] "" Vector__XXX
 SG_ RevisionNumber71_1F87_47 m71 : 32|32@1+ (1,0) [0|4294967295] "" Vector__XXX
 SG_ RevisionNumber70_1F87_46 m70 : 32|32@1+ (1,0) [0|4294967295] "" Vector__XXX
 SG_ RevisionNumber69_1F87_45 m69 : 32|32@1+ (1,0) [0|4294967295] "" Vector__XXX
 SG_ RevisionNumber68_1F87_44 m68 : 32|32@1+ (1,0) [0|4294967295] "" Vector__XXX
 SG_ RevisionNumber67_1F87_43 m67 : 32|32@1+ (1,0) [0|4294967295] "" Vector__XXX
 SG_ RevisionNumber66_1F87_42 m66 : 32|32@1+ (1,0) [0|4294967295] "" Vector__XXX
 SG_ RevisionNumber65_1F87_41 m65 : 32|32@1+ (1,0) [0|4294967295] "" Vector__XXX
 SG_ RevisionNumber64_1F87_40 m64 : 32|32@1+ (1,0) [0|4294967295] "" Vector__XXX
 SG_ RevisionNumber63_1F87_3F m63 : 32|32@1+ (1,0) [0|4294967295] "" Vector__XXX
 SG_ RevisionNumber62_1F87_3E m62 : 32|32@1+ (1,0) [0|4294967295] "" Vector__XXX
 SG_ RevisionNumber61_1F87_3D m61 : 32|32@1+ (1,0) [0|4294967295] "" Vector__XXX
 SG_ RevisionNumber60_1F87_3C m60 : 32|32@1+ (1,0) [0|4294967295] "" Vector__XXX
 SG_ RevisionNumber59_1F87_3B m59 : 32|32@1+ (1,0) [0|4294967295] "" Vector__XXX
 SG_ RevisionNumber58_1F87_3A m58 : 32|32@1+ (1,0) [0|4294967295] "" Vector__XXX
 SG_ RevisionNumber57_1F87_39 m57 : 32|32@1+ (1,0) [0|4294967295] "" Vector__XXX
 SG_ RevisionNumber56_1F87_38 m56 : 32|32@1+ (1,0) [0|4294967295] "" Vector__XXX
 SG_ RevisionNumber55_1F87_37 m55 : 32|32@1+ (1,0) [0|4294967295] "" Vector__XXX
 SG_ RevisionNumber54_1F87_36 m54 : 32|32@1+ (1,0) [0|4294967295] "" Vector__XXX
 SG_ RevisionNumber53_1F87_35 m53 : 32|32@1+ (1,0) [0|4294967295] "" Vector__XXX
 SG_ RevisionNumber52_1F87_34 m52 : 32|32@1+ (1,0) [0|4294967295] "" Vector__XXX
 SG_ RevisionNumber51_1F87_33 m51 : 32|32@1+ (1,0) [0|4294967295] "" Vector__XXX
 SG_ RevisionNumber50_1F87_32 m50 : 32|32@1+ (1,0) [0|4294967295] "" Vector__XXX
 SG_ RevisionNumber49_1F87_31 m49 : 32|32@1+ (1,0) [0|4294967295] "" Vector__XXX
 SG_ RevisionNumber48_1F87_30 m48 : 32|32@1+ (1,0) [0|4294967295] "" Vector__XXX
 SG_ RevisionNumber47_1F87_2F m47 : 32|32@1+ (1,0) [0|4294967295] "" Vector__XXX
 SG_ RevisionNumber46_1F87_2E m46 : 32|32@1+ (1,0) [0|4294967295] "" Vector__XXX
 SG_ RevisionNumber45_1F87_2D m45 : 32|32@1+ (1,0) [0|4294967295] "" Vector__XXX
 SG_ RevisionNumber44_1F87_2C m44 : 32|32@1+ (1,0) [0|4294967295] "" Vector__XXX
 SG_ RevisionNumber43_1F87_2B m43 : 32|32@1+ (1,0) [0|4294967295] "" Vector__XXX
 SG_ RevisionNumber42_1F87_2A m42 : 32|32@1+ (1,0) [0|4294967295] "" Vector__XXX
 SG_ RevisionNumber41_1F87_29 m41 : 32|32@1+ (1,0) [0|4294967295] "" Vector__XXX
 SG_ RevisionNumber40_1F87_28 m40 : 32|32@1+ (1,0) [0|4294967295] "" Vector__XXX
 SG_ RevisionNumber39_1F87_27 m39 : 32|32@1+ (1,0) [0|4294967295] "" Vector__XXX
 SG_ RevisionNumber38_1F87_26 m38 : 32|32@1+ (1,0) [0|4294967295] "" Vector__XXX
 SG_ RevisionNumber37_1F87_25 m37 : 32|32@1+ (1,0) [0|4294967295] "" Vector__XXX
 SG_ RevisionNumber36_1F87_24 m36 : 32|32@1+ (1,0) [0|4294967295] "" Vector__XXX
 SG_ RevisionNumber35_1F87_23 m35 : 32|32@1+ (1,0) [0|4294967295] "" Vector__XXX
 SG_ RevisionNumber34_1F87_22 m34 : 32|32@1+ (1,0) [0|4294967295] "" Vector__XXX
 SG_ RevisionNumber33_1F87_21 m33 : 32|32@1+ (1,0) [0|4294967295] "" Vector__XXX
 SG_ RevisionNumber32_1F87_20 m32 : 32|32@1+ (1,0) [0|4294967295] "" Vector__XXX
 SG_ RevisionNumber31_1F87_1F m31 : 32|32@1+ (1,0) [0|4294967295] "" Vector__XXX
 SG_ RevisionNumber30_1F87_1E m30 : 32|32@1+ (1,0) [0|4294967295] "" Vector__XXX
 SG_ RevisionNumber29_1F87_1D m29 : 32|32@1+ (1,0) [0|4294967295] "" Vector__XXX
 SG_ RevisionNumber28_1F87_1C m28 : 32|32@1+ (1,0) [0|4294967295] "" Vector__XXX
 SG_ RevisionNumber27_1F87_1B m27 : 32|32@1+ (1,0) [0|4294967295] "" Vector__XXX
 SG_ RevisionNumber26_1F87_1A m26 : 32|32@1+ (1,0) [0|4294967295] "" Vector__XXX
 SG_ RevisionNumber25_1F87_19 m25 : 32|32@1+ (1,0) [0|4294967295] "" Vector__XXX
 SG_ RevisionNumber24_1F87_18 m24 : 32|32@1+ (1,0) [0|4294967295] "" Vector__XXX
 SG_ RevisionNumber23_1F87_17 m23 : 32|32@1+ (1,0) [0|4294967295] "" Vector__XXX
 SG_ RevisionNumber22_1F87_16 m22 : 32|32@1+ (1,0) [0|4294967295] "" Vector__XXX
 SG_ RevisionNumber21_1F87_15 m21 : 32|32@1+ (1,0) [0|4294967295] "" Vector__XXX
 SG_ RevisionNumber20_1F87_14 m20 : 32|32@1+ (1,0) [0|4294967295] "" Vector__XXX
 SG_ RevisionNumber19_1F87_13 m19 : 32|32@1+ (1,0) [0|4294967295] "" Vector__XXX
 SG_ RevisionNumber18_1F87_12 m18 : 32|32@1+ (1,0) [0|4294967295] "" Vector__XXX
 SG_ RevisionNumber17_1F87_11 m17 : 32|32@1+ (1,0) [0|4294967295] "" Vector__XXX
 SG_ RevisionNumber16_1F87_10 m16 : 32|32@1+ (1,0) [0|4294967295] "" Vector__XXX
 SG_ RevisionNumber15_1F87_0F m15 : 32|32@1+ (1,0) [0|4294967295] "" Vector__XXX
 SG_ RevisionNumber14_1F87_0E m14 : 32|32@1+ (1,0) [0|4294967295] "" Vector__XXX
 SG_ RevisionNumber13_1F87_0D m13 : 32|32@1+ (1,0) [0|4294967295] "" Vector__XXX
 SG_ RevisionNumber12_1F87_0C m12 : 32|32@1+ (1,0) [0|4294967295] "" Vector__XXX
 SG_ RevisionNumber11_1F87_0B m11 : 32|32@1+ (1,0) [0|4294967295] "" Vector__XXX
 SG_ RevisionNumber10_1F87_0A m10 : 32|32@1+ (1,0) [0|4294967295] "" Vector__XXX
 SG_ RevisionNumber9_1F87_09 m9 : 32|32@1+ (1,0) [0|4294967295] "" Vector__XXX
 SG_ RevisionNumber8_1F87_08 m8 : 32|32@1+ (1,0) [0|4294967295] "" Vector__XXX
 SG_ RevisionNumber7_1F87_07 m7 : 32|32@1+ (1,0) [0|4294967295] "" Vector__XXX
 SG_ RevisionNumber6_1F87_06 m6 : 32|32@1+ (1,0) [0|4294967295] "" Vector__XXX
 SG_ RevisionNumber5_1F87_05 m5 : 32|32@1+ (1,0) [0|4294967295] "" Vector__XXX
 SG_ RevisionNumber4_1F87_04 m4 : 32|32@1+ (1,0) [0|4294967295] "" Vector__XXX
 SG_ RevisionNumber3_1F87_03 m3 : 32|32@1+ (1,0) [0|4294967295] "" Vector__XXX
 SG_ RevisionNumber2_1F87_02 m2 : 32|32@1+ (1,0) [0|4294967295] "" Vector__XXX
 SG_ RevisionNumber1_1F87_01 m1 : 32|32@1+ (1,0) [0|4294967295] "" Vector__XXX
 SG_ SubIndex_1F87 m8071M : 24|8@1+ (1,0) [0|127] "" Vector__XXX
 SG_ Index m1M : 8|16@1+ (1,0) [4096|42563] "" Vector__XXX
 SG_ SCS M : 5|3@1+ (1,0) [0|6] "" Vector__XXX

BA_DEF_ BU_  "CO_DCF" STRING ;
BA_DEF_ BU_  "CO_ID" INT 0 127;
BA_DEF_ BU_  "CO_NVSEGMENT0" STRING ;
BA_DEF_ BU_  "CO_NVSEGMENT1" STRING ;
BA_DEF_ BU_  "CO_NVSEGMENT2" STRING ;
BA_DEF_ BU_  "CO_NVSEGMENT3" STRING ;
BA_DEF_ BU_  "CO_NVSEGMENT4" STRING ;
BA_DEF_ BU_  "CO_NVSEGMENT5" STRING ;
BA_DEF_ BU_  "CO_NVSEGMENT6" STRING ;
BA_DEF_ BU_  "CO_NVSEGMENT7" STRING ;
BA_DEF_ BU_  "CO_NVSEGMENT8" STRING ;
BA_DEF_ BU_  "CO_NVSEGMENT9" STRING ;
BA_DEF_ BU_  "CO_NVSEGMENT10" STRING ;
BA_DEF_ BU_  "CO_NVSEGMENT11" STRING ;
BA_DEF_ BU_  "CO_NVSEGMENT12" STRING ;
BA_DEF_ BU_  "CO_NVSEGMENT13" STRING ;
BA_DEF_ BU_  "CO_NVSEGMENT14" STRING ;
BA_DEF_ BU_  "CO_NVSEGMENT15" STRING ;
BA_DEF_ BU_  "CO_NVSEGMENT16" STRING ;
BA_DEF_ BU_  "CO_NVSEGMENT17" STRING ;
BA_DEF_ BU_  "CO_NVSEGMENT18" STRING ;
BA_DEF_ BU_  "CO_NVSEGMENT19" STRING ;
BA_DEF_ BU_  "CO_NVSEGMENT20" STRING ;
BA_DEF_ BU_  "CO_NVSEGMENT21" STRING ;
BA_DEF_ BU_  "CO_NVSEGMENT22" STRING ;
BA_DEF_ BU_  "CO_NVSEGMENT23" STRING ;
BA_DEF_ BU_  "CO_NVSEGMENT24" STRING ;
BA_DEF_ BU_  "CO_NVSEGMENT25" STRING ;
BA_DEF_ BU_  "CO_NVSEGMENT26" STRING ;
BA_DEF_ BU_  "CO_NVSEGMENT27" STRING ;
BA_DEF_ BU_  "CO_NVSEGMENT28" STRING ;
BA_DEF_ BU_  "CO_NVSEGMENT29" STRING ;
BA_DEF_ BU_  "CO_NVSEGMENT30" STRING ;
BA_DEF_ BU_  "CO_NVSEGMENT31" STRING ;
BA_DEF_ BU_  "CO_NVSEGMENT32" STRING ;
BA_DEF_ BU_  "CO_NVSEGMENT33" STRING ;
BA_DEF_ BU_  "CO_NVSEGMENT34" STRING ;
BA_DEF_ BU_  "CO_NVSEGMENT35" STRING ;
BA_DEF_ BU_  "CO_NVSEGMENT36" STRING ;
BA_DEF_ BU_  "CO_NVSEGMENT37" STRING ;
BA_DEF_ BU_  "CO_NVSEGMENT38" STRING ;
BA_DEF_ BU_  "CO_NVSEGMENT39" STRING ;
BA_DEF_ BU_  "CO_NVSEGMENT40" STRING ;
BA_DEF_ BU_  "CO_NVSEGMENT41" STRING ;
BA_DEF_ BU_  "CO_NVSEGMENT42" STRING ;
BA_DEF_ BU_  "CO_NVSEGMENT43" STRING ;
BA_DEF_ BU_  "CO_NVSEGMENT44" STRING ;
BA_DEF_ BU_  "CO_NVSEGMENT45" STRING ;
BA_DEF_  "OptionLoadDCF" INT 0 1;
BA_DEF_ BO_  "GenMsgSendType" ENUM  "Cyclic","SendType1","SendType2","SendType3","SendType4","SendType5","SendType6","SendType7","SendType8","SendType9";
BA_DEF_ BO_  "GenMsgCycleTime" INT 0 0;
BA_DEF_ SG_  "GenSigStartValue" INT 0 0;
BA_DEF_ BO_  "CO_MsgCategory" INT 0 0;
BA_DEF_  "CO_MsgColourSupported" INT 0 1;
BA_DEF_  "GeneratedBy" STRING ;
BA_DEF_  "CANopenApplProfile" INT 0 0;
BA_DEF_  "ProtocolType" STRING ;
BA_DEF_  "AUTOGENERATION" INT 0 1;
BA_DEF_ SG_  "SystemSignalLongSymbol" STRING ;
BA_DEF_DEF_  "CO_DCF" "";
BA_DEF_DEF_  "CO_ID" 0;
BA_DEF_DEF_  "CO_NVSEGMENT0" "";
BA_DEF_DEF_  "CO_NVSEGMENT1" "";
BA_DEF_DEF_  "CO_NVSEGMENT2" "";
BA_DEF_DEF_  "CO_NVSEGMENT3" "";
BA_DEF_DEF_  "CO_NVSEGMENT4" "";
BA_DEF_DEF_  "CO_NVSEGMENT5" "";
BA_DEF_DEF_  "CO_NVSEGMENT6" "";
BA_DEF_DEF_  "CO_NVSEGMENT7" "";
BA_DEF_DEF_  "CO_NVSEGMENT8" "";
BA_DEF_DEF_  "CO_NVSEGMENT9" "";
BA_DEF_DEF_  "CO_NVSEGMENT10" "";
BA_DEF_DEF_  "CO_NVSEGMENT11" "";
BA_DEF_DEF_  "CO_NVSEGMENT12" "";
BA_DEF_DEF_  "CO_NVSEGMENT13" "";
BA_DEF_DEF_  "CO_NVSEGMENT14" "";
BA_DEF_DEF_  "CO_NVSEGMENT15" "";
BA_DEF_DEF_  "CO_NVSEGMENT16" "";
BA_DEF_DEF_  "CO_NVSEGMENT17" "";
BA_DEF_DEF_  "CO_NVSEGMENT18" "";
BA_DEF_DEF_  "CO_NVSEGMENT19" "";
BA_DEF_DEF_  "CO_NVSEGMENT20" "";
BA_DEF_DEF_  "CO_NVSEGMENT21" "";
BA_DEF_DEF_  "CO_NVSEGMENT22" "";
BA_DEF_DEF_  "CO_NVSEGMENT23" "";
BA_DEF_DEF_  "CO_NVSEGMENT24" "";
BA_DEF_DEF_  "CO_NVSEGMENT25" "";
BA_DEF_DEF_  "CO_NVSEGMENT26" "";
BA_DEF_DEF_  "CO_NVSEGMENT27" "";
BA_DEF_DEF_  "CO_NVSEGMENT28" "";
BA_DEF_DEF_  "CO_NVSEGMENT29" "";
BA_DEF_DEF_  "CO_NVSEGMENT30" "";
BA_DEF_DEF_  "CO_NVSEGMENT31" "";
BA_DEF_DEF_  "CO_NVSEGMENT32" "";
BA_DEF_DEF_  "CO_NVSEGMENT33" "";
BA_DEF_DEF_  "CO_NVSEGMENT34" "";
BA_DEF_DEF_  "CO_NVSEGMENT35" "";
BA_DEF_DEF_  "CO_NVSEGMENT36" "";
BA_DEF_DEF_  "CO_NVSEGMENT37" "";
BA_DEF_DEF_  "CO_NVSEGMENT38" "";
BA_DEF_DEF_  "CO_NVSEGMENT39" "";
BA_DEF_DEF_  "CO_NVSEGMENT40" "";
BA_DEF_DEF_  "CO_NVSEGMENT41" "";
BA_DEF_DEF_  "CO_NVSEGMENT42" "";
BA_DEF_DEF_  "CO_NVSEGMENT43" "";
BA_DEF_DEF_  "CO_NVSEGMENT44" "";
BA_DEF_DEF_  "CO_NVSEGMENT45" "";
BA_DEF_DEF_  "OptionLoadDCF" 0;
BA_DEF_DEF_  "GenMsgSendType" "";
BA_DEF_DEF_  "GenMsgCycleTime" 0;
BA_DEF_DEF_  "GenSigStartValue" 0;
BA_DEF_DEF_  "CO_MsgCategory" 0;
BA_DEF_DEF_  "CO_MsgColourSupported" 1;
BA_DEF_DEF_  "GeneratedBy" "";
BA_DEF_DEF_  "CANopenApplProfile" 301;
BA_DEF_DEF_  "ProtocolType" "CANopenSafety";
BA_DEF_DEF_  "AUTOGENERATION" 0;
BA_DEF_DEF_  "SystemSignalLongSymbol" "";
BA_ "OptionLoadDCF" 1;
BA_ "GeneratedBy" "CANoe 13.0.86";
BA_ "AUTOGENERATION" 1;
BA_ "CO_DCF" BU_ Sensor_3_ID28 "Sensor_3_ID28.dcf";
BA_ "CO_ID" BU_ Sensor_3_ID28 28;
BA_ "CO_DCF" BU_ Sensor_2_ID27 "Sensor_2_ID27.dcf";
BA_ "CO_ID" BU_ Sensor_2_ID27 27;
BA_ "CO_DCF" BU_ Sensor_1_ID23 "Sensor_1_ID23.dcf";
BA_ "CO_ID" BU_ Sensor_1_ID23 23;
BA_ "CO_NVSEGMENT39" BU_ Display_ID10 "a440,a447,1,27,0,0";
BA_ "CO_NVSEGMENT38" BU_ Display_ID10 "a440,a447,1,27,0,0";
BA_ "CO_NVSEGMENT37" BU_ Display_ID10 "a400,a407,1,21,0,0";
BA_ "CO_NVSEGMENT36" BU_ Display_ID10 "a400,a407,1,21,0,0";
BA_ "CO_NVSEGMENT35" BU_ Display_ID10 "a240,a247,1,8,0,0";
BA_ "CO_NVSEGMENT34" BU_ Display_ID10 "a240,a247,1,8,0,0";
BA_ "CO_NVSEGMENT33" BU_ Display_ID10 "a200,a207,1,7,0,0";
BA_ "CO_NVSEGMENT32" BU_ Display_ID10 "a200,a207,1,7,0,0";
BA_ "CO_NVSEGMENT31" BU_ Display_ID10 "a1c0,a1c7,1,4,0,0";
BA_ "CO_NVSEGMENT30" BU_ Display_ID10 "a1c0,a1c7,1,4,0,0";
BA_ "CO_NVSEGMENT29" BU_ Display_ID10 "a100,a107,1,6,0,0";
BA_ "CO_NVSEGMENT28" BU_ Display_ID10 "a100,a107,1,6,0,0";
BA_ "CO_NVSEGMENT27" BU_ Display_ID10 "a0c0,a0c7,1,3,0,0";
BA_ "CO_NVSEGMENT26" BU_ Display_ID10 "a0c0,a0c7,1,3,0,0";
BA_ "CO_NVSEGMENT25" BU_ Display_ID10 "a040,a047,1,5,0,0";
BA_ "CO_NVSEGMENT24" BU_ Display_ID10 "a040,a047,1,5,0,0";
BA_ "CO_NVSEGMENT23" BU_ Display_ID10 "a000,a007,1,2,0,0";
BA_ "CO_NVSEGMENT22" BU_ Display_ID10 "a000,a007,1,2,0,0";
BA_ "CO_NVSEGMENT21" BU_ Display_ID10 "a080,a087,1,1,0,8";
BA_ "CO_NVSEGMENT20" BU_ Display_ID10 "a080,a087,1,1,0,8";
BA_ "CO_NVSEGMENT19" BU_ Display_ID10 "a8c0,a8c7,0,27,0,0";
BA_ "CO_NVSEGMENT18" BU_ Display_ID10 "a8c0,a8c7,0,27,0,0";
BA_ "CO_NVSEGMENT17" BU_ Display_ID10 "a880,a887,0,21,0,0";
BA_ "CO_NVSEGMENT16" BU_ Display_ID10 "a880,a887,0,21,0,0";
BA_ "CO_NVSEGMENT15" BU_ Display_ID10 "a6c0,a6c7,0,8,0,0";
BA_ "CO_NVSEGMENT14" BU_ Display_ID10 "a6c0,a6c7,0,8,0,0";
BA_ "CO_NVSEGMENT13" BU_ Display_ID10 "a680,a687,0,7,0,0";
BA_ "CO_NVSEGMENT12" BU_ Display_ID10 "a680,a687,0,7,0,0";
BA_ "CO_NVSEGMENT11" BU_ Display_ID10 "a640,a647,0,4,0,0";
BA_ "CO_NVSEGMENT10" BU_ Display_ID10 "a640,a647,0,4,0,0";
BA_ "CO_NVSEGMENT9" BU_ Display_ID10 "a580,a587,0,6,0,0";
BA_ "CO_NVSEGMENT8" BU_ Display_ID10 "a580,a587,0,6,0,0";
BA_ "CO_NVSEGMENT7" BU_ Display_ID10 "a540,a547,0,3,0,0";
BA_ "CO_NVSEGMENT6" BU_ Display_ID10 "a540,a547,0,3,0,0";
BA_ "CO_NVSEGMENT5" BU_ Display_ID10 "a4c0,a4c7,0,5,0,0";
BA_ "CO_NVSEGMENT4" BU_ Display_ID10 "a4c0,a4c7,0,5,0,0";
BA_ "CO_NVSEGMENT3" BU_ Display_ID10 "a480,a487,0,2,0,0";
BA_ "CO_NVSEGMENT2" BU_ Display_ID10 "a480,a487,0,2,0,0";
BA_ "CO_NVSEGMENT1" BU_ Display_ID10 "a500,a507,0,1,0,8";
BA_ "CO_NVSEGMENT0" BU_ Display_ID10 "a500,a507,0,1,0,8";
BA_ "CO_DCF" BU_ Display_ID10 "Display_ID10.dcf";
BA_ "CO_ID" BU_ Display_ID10 10;
BA_ "GenMsgSendType" BO_ 1820 0;
BA_ "GenMsgCycleTime" BO_ 1820 500;
BA_ "CO_MsgCategory" BO_ 1820 505;
BA_ "CO_MsgCategory" BO_ 262 805;
BA_ "CO_MsgCategory" BO_ 261 810;
BA_ "CO_MsgCategory" BO_ 1436 410;
BA_ "CO_MsgCategory" BO_ 1564 405;
BA_ "CO_MsgCategory" BO_ 156 205;
BA_ "GenMsgSendType" BO_ 1819 0;
BA_ "GenMsgCycleTime" BO_ 1819 500;
BA_ "CO_MsgCategory" BO_ 1819 505;
BA_ "CO_MsgCategory" BO_ 260 805;
BA_ "CO_MsgCategory" BO_ 259 810;
BA_ "CO_MsgCategory" BO_ 1435 410;
BA_ "CO_MsgCategory" BO_ 1563 405;
BA_ "CO_MsgCategory" BO_ 155 205;
BA_ "GenMsgSendType" BO_ 1815 0;
BA_ "GenMsgCycleTime" BO_ 1815 500;
BA_ "CO_MsgCategory" BO_ 1815 505;
BA_ "CO_MsgCategory" BO_ 258 805;
BA_ "CO_MsgCategory" BO_ 257 810;
BA_ "CO_MsgCategory" BO_ 1431 410;
BA_ "CO_MsgCategory" BO_ 1559 405;
BA_ "CO_MsgCategory" BO_ 151 205;
BA_ "CO_MsgCategory" BO_ 128 110;
BA_ "CO_MsgCategory" BO_ 1802 505;
BA_ "CO_MsgCategory" BO_ 1418 410;
BA_ "GenSigStartValue" SG_ 1436 Pressure_1_inverted_6402_02 4294967295;
BA_ "GenSigStartValue" SG_ 1436 Highest_sub_index_supported_6402 2;
BA_ "SystemSignalLongSymbol" SG_ 1436 Highest_sub_index_supported_6402 "Highest_sub_index_supported_6402_00";
BA_ "GenSigStartValue" SG_ 1436 Safety_Checksum_13FF_01 24931;
BA_ "GenSigStartValue" SG_ 1436 Safety_checksum_Number_of_entrie 1;
BA_ "SystemSignalLongSymbol" SG_ 1436 Safety_checksum_Number_of_entrie "Safety_checksum_Number_of_entries_13FF_00";
BA_ "GenSigStartValue" SG_ 1436 Configuration_valid_13FE 165;
BA_ "GenSigStartValue" SG_ 1436 SRDO1_mapping_inv_Byte1_1381_02 1677853216;
BA_ "GenSigStartValue" SG_ 1436 SRDO1_mapping_Byte1_1381_01 1677852960;
BA_ "GenSigStartValue" SG_ 1436 SRDO1_Number_of_mapped_objects_1 2;
BA_ "SystemSignalLongSymbol" SG_ 1436 SRDO1_Number_of_mapped_objects_1 "SRDO1_Number_of_mapped_objects_1381_00";
BA_ "GenSigStartValue" SG_ 1436 SRDO1_communication_par_COB_ID_2 262;
BA_ "SystemSignalLongSymbol" SG_ 1436 SRDO1_communication_par_COB_ID_2 "SRDO1_communication_par_COB_ID_2_1301_06";
BA_ "GenSigStartValue" SG_ 1436 SRDO1_communication_par_COB_ID_1 261;
BA_ "SystemSignalLongSymbol" SG_ 1436 SRDO1_communication_par_COB_ID_1 "SRDO1_communication_par_COB_ID_1_1301_05";
BA_ "GenSigStartValue" SG_ 1436 SRDO1_communication_par_Transmis 254;
BA_ "SystemSignalLongSymbol" SG_ 1436 SRDO1_communication_par_Transmis "SRDO1_communication_par_Transmission_type_1301_04";
BA_ "GenSigStartValue" SG_ 1436 SRDO1_communication_par_refresh_ 25;
BA_ "SystemSignalLongSymbol" SG_ 1436 SRDO1_communication_par_refresh_ "SRDO1_communication_par_refresh_time_1301_02";
BA_ "GenSigStartValue" SG_ 1436 SRDO1_communication_par_Informat 1;
BA_ "SystemSignalLongSymbol" SG_ 1436 SRDO1_communication_par_Informat "SRDO1_communication_par_Information_direction_1301_01";
BA_ "GenSigStartValue" SG_ 1436 Highest_sub_index_supported_1301 6;
BA_ "SystemSignalLongSymbol" SG_ 1436 Highest_sub_index_supported_1301 "Highest_sub_index_supported_1301_00";
BA_ "GenSigStartValue" SG_ 1436 Revision_number_1018_03 256;
BA_ "GenSigStartValue" SG_ 1436 Product_Code_1018_02 4660;
BA_ "GenSigStartValue" SG_ 1436 Vendor_Id_1018_01 5;
BA_ "GenSigStartValue" SG_ 1436 Highest_sub_index_supported_1018 4;
BA_ "SystemSignalLongSymbol" SG_ 1436 Highest_sub_index_supported_1018 "Highest_sub_index_supported_1018_00";
BA_ "GenSigStartValue" SG_ 1436 Producer_Heartbeat_Time_1017 500;
BA_ "SystemSignalLongSymbol" SG_ 1436 Consumer_Heartbeat_Time16_1016_1 "Consumer_Heartbeat_Time16_1016_10";
BA_ "SystemSignalLongSymbol" SG_ 1436 Consumer_Heartbeat_Time15_1016_0 "Consumer_Heartbeat_Time15_1016_0F";
BA_ "SystemSignalLongSymbol" SG_ 1436 Consumer_Heartbeat_Time14_1016_0 "Consumer_Heartbeat_Time14_1016_0E";
BA_ "SystemSignalLongSymbol" SG_ 1436 Consumer_Heartbeat_Time13_1016_0 "Consumer_Heartbeat_Time13_1016_0D";
BA_ "SystemSignalLongSymbol" SG_ 1436 Consumer_Heartbeat_Time12_1016_0 "Consumer_Heartbeat_Time12_1016_0C";
BA_ "SystemSignalLongSymbol" SG_ 1436 Consumer_Heartbeat_Time11_1016_0 "Consumer_Heartbeat_Time11_1016_0B";
BA_ "SystemSignalLongSymbol" SG_ 1436 Consumer_Heartbeat_Time10_1016_0 "Consumer_Heartbeat_Time10_1016_0A";
BA_ "GenSigStartValue" SG_ 1436 NrOfObjects_1016_00 16;
BA_ "GenSigStartValue" SG_ 1436 COB_ID_EMCY_1014 156;
BA_ "SystemSignalLongSymbol" SG_ 1436 Restore_all_Default_Parameters_1 "Restore_all_Default_Parameters_1011_01";
BA_ "GenSigStartValue" SG_ 1436 Highest_sub_index_supported_1011 1;
BA_ "SystemSignalLongSymbol" SG_ 1436 Highest_sub_index_supported_1011 "Highest_sub_index_supported_1011_00";
BA_ "GenSigStartValue" SG_ 1436 Highest_sub_index_supported_1010 1;
BA_ "SystemSignalLongSymbol" SG_ 1436 Highest_sub_index_supported_1010 "Highest_sub_index_supported_1010_00";
BA_ "GenSigStartValue" SG_ 1436 Life_Time_Factor_100D 244;
BA_ "GenSigStartValue" SG_ 1436 Guard_Time_100C 2000;
BA_ "GenSigStartValue" SG_ 1436 Sync_Window_Length_1007 50000;
BA_ "GenSigStartValue" SG_ 1436 Communication_Cycle_Period_1006 100000;
BA_ "GenSigStartValue" SG_ 1436 COB_ID_SYNC_1005 2147483776;
BA_ "GenSigStartValue" SG_ 1436 Device_Type_1000 197009;
BA_ "GenSigStartValue" SG_ 1436 Index 4096;
BA_ "GenSigStartValue" SG_ 1564 Pressure_1_inverted_6402_02 4294967295;
BA_ "GenSigStartValue" SG_ 1564 Highest_sub_index_supported_0000 2;
BA_ "SystemSignalLongSymbol" SG_ 1564 Highest_sub_index_supported_0000 "Highest_sub_index_supported_6402_00";
BA_ "GenSigStartValue" SG_ 1564 Safety_Checksum_13FF_01 24931;
BA_ "GenSigStartValue" SG_ 1564 Safety_checksum_Number_of_e_0000 1;
BA_ "SystemSignalLongSymbol" SG_ 1564 Safety_checksum_Number_of_e_0000 "Safety_checksum_Number_of_entries_13FF_00";
BA_ "GenSigStartValue" SG_ 1564 Configuration_valid_13FE 165;
BA_ "GenSigStartValue" SG_ 1564 SRDO1_mapping_inv_Byte1_1381_02 1677853216;
BA_ "GenSigStartValue" SG_ 1564 SRDO1_mapping_Byte1_1381_01 1677852960;
BA_ "GenSigStartValue" SG_ 1564 SRDO1_Number_of_mapped_obje_0000 2;
BA_ "SystemSignalLongSymbol" SG_ 1564 SRDO1_Number_of_mapped_obje_0000 "SRDO1_Number_of_mapped_objects_1381_00";
BA_ "GenSigStartValue" SG_ 1564 SRDO1_communication_par_COB_0000 262;
BA_ "SystemSignalLongSymbol" SG_ 1564 SRDO1_communication_par_COB_0000 "SRDO1_communication_par_COB_ID_2_1301_06";
BA_ "GenSigStartValue" SG_ 1564 SRDO1_communication_par_COB_0001 261;
BA_ "SystemSignalLongSymbol" SG_ 1564 SRDO1_communication_par_COB_0001 "SRDO1_communication_par_COB_ID_1_1301_05";
BA_ "GenSigStartValue" SG_ 1564 SRDO1_communication_par_Tra_0000 254;
BA_ "SystemSignalLongSymbol" SG_ 1564 SRDO1_communication_par_Tra_0000 "SRDO1_communication_par_Transmission_type_1301_04";
BA_ "GenSigStartValue" SG_ 1564 SRDO1_communication_par_ref_0000 25;
BA_ "SystemSignalLongSymbol" SG_ 1564 SRDO1_communication_par_ref_0000 "SRDO1_communication_par_refresh_time_1301_02";
BA_ "GenSigStartValue" SG_ 1564 SRDO1_communication_par_Inf_0000 1;
BA_ "SystemSignalLongSymbol" SG_ 1564 SRDO1_communication_par_Inf_0000 "SRDO1_communication_par_Information_direction_1301_01";
BA_ "GenSigStartValue" SG_ 1564 Highest_sub_index_supported_0001 6;
BA_ "SystemSignalLongSymbol" SG_ 1564 Highest_sub_index_supported_0001 "Highest_sub_index_supported_1301_00";
BA_ "GenSigStartValue" SG_ 1564 Revision_number_1018_03 256;
BA_ "GenSigStartValue" SG_ 1564 Product_Code_1018_02 4660;
BA_ "GenSigStartValue" SG_ 1564 Vendor_Id_1018_01 5;
BA_ "GenSigStartValue" SG_ 1564 Highest_sub_index_supported_0002 4;
BA_ "SystemSignalLongSymbol" SG_ 1564 Highest_sub_index_supported_0002 "Highest_sub_index_supported_1018_00";
BA_ "GenSigStartValue" SG_ 1564 Producer_Heartbeat_Time_1017 500;
BA_ "SystemSignalLongSymbol" SG_ 1564 Consumer_Heartbeat_Time16_1_0000 "Consumer_Heartbeat_Time16_1016_10";
BA_ "SystemSignalLongSymbol" SG_ 1564 Consumer_Heartbeat_Time15_1_0000 "Consumer_Heartbeat_Time15_1016_0F";
BA_ "SystemSignalLongSymbol" SG_ 1564 Consumer_Heartbeat_Time14_1_0000 "Consumer_Heartbeat_Time14_1016_0E";
BA_ "SystemSignalLongSymbol" SG_ 1564 Consumer_Heartbeat_Time13_1_0000 "Consumer_Heartbeat_Time13_1016_0D";
BA_ "SystemSignalLongSymbol" SG_ 1564 Consumer_Heartbeat_Time12_1_0000 "Consumer_Heartbeat_Time12_1016_0C";
BA_ "SystemSignalLongSymbol" SG_ 1564 Consumer_Heartbeat_Time11_1_0000 "Consumer_Heartbeat_Time11_1016_0B";
BA_ "SystemSignalLongSymbol" SG_ 1564 Consumer_Heartbeat_Time10_1_0000 "Consumer_Heartbeat_Time10_1016_0A";
BA_ "GenSigStartValue" SG_ 1564 NrOfObjects_1016_00 16;
BA_ "GenSigStartValue" SG_ 1564 COB_ID_EMCY_1014 156;
BA_ "SystemSignalLongSymbol" SG_ 1564 Restore_all_Default_Paramet_0000 "Restore_all_Default_Parameters_1011_01";
BA_ "GenSigStartValue" SG_ 1564 Highest_sub_index_supported_0003 1;
BA_ "SystemSignalLongSymbol" SG_ 1564 Highest_sub_index_supported_0003 "Highest_sub_index_supported_1011_00";
BA_ "GenSigStartValue" SG_ 1564 Highest_sub_index_supported_0004 1;
BA_ "SystemSignalLongSymbol" SG_ 1564 Highest_sub_index_supported_0004 "Highest_sub_index_supported_1010_00";
BA_ "GenSigStartValue" SG_ 1564 Life_Time_Factor_100D 244;
BA_ "GenSigStartValue" SG_ 1564 Guard_Time_100C 2000;
BA_ "GenSigStartValue" SG_ 1564 Sync_Window_Length_1007 50000;
BA_ "GenSigStartValue" SG_ 1564 Communication_Cycle_Period_1006 100000;
BA_ "GenSigStartValue" SG_ 1564 COB_ID_SYNC_1005 2147483776;
BA_ "GenSigStartValue" SG_ 1564 Device_Type_1000 197009;
BA_ "GenSigStartValue" SG_ 1564 Index 4096;
BA_ "GenSigStartValue" SG_ 1435 Pressure_1_inverted_6402_02 4294967295;
BA_ "GenSigStartValue" SG_ 1435 Highest_sub_index_supported_0005 2;
BA_ "SystemSignalLongSymbol" SG_ 1435 Highest_sub_index_supported_0005 "Highest_sub_index_supported_6402_00";
BA_ "GenSigStartValue" SG_ 1435 Safety_Checksum_13FF_01 51386;
BA_ "GenSigStartValue" SG_ 1435 Safety_checksum_Number_of_e_0001 1;
BA_ "SystemSignalLongSymbol" SG_ 1435 Safety_checksum_Number_of_e_0001 "Safety_checksum_Number_of_entries_13FF_00";
BA_ "GenSigStartValue" SG_ 1435 Configuration_valid_13FE 165;
BA_ "GenSigStartValue" SG_ 1435 SRDO1_mapping_inv_Byte1_1381_02 1677853216;
BA_ "GenSigStartValue" SG_ 1435 SRDO1_mapping_Byte1_1381_01 1677852960;
BA_ "GenSigStartValue" SG_ 1435 SRDO1_Number_of_mapped_obje_0001 2;
BA_ "SystemSignalLongSymbol" SG_ 1435 SRDO1_Number_of_mapped_obje_0001 "SRDO1_Number_of_mapped_objects_1381_00";
BA_ "GenSigStartValue" SG_ 1435 SRDO1_communication_par_COB_0002 260;
BA_ "SystemSignalLongSymbol" SG_ 1435 SRDO1_communication_par_COB_0002 "SRDO1_communication_par_COB_ID_2_1301_06";
BA_ "GenSigStartValue" SG_ 1435 SRDO1_communication_par_COB_0003 259;
BA_ "SystemSignalLongSymbol" SG_ 1435 SRDO1_communication_par_COB_0003 "SRDO1_communication_par_COB_ID_1_1301_05";
BA_ "GenSigStartValue" SG_ 1435 SRDO1_communication_par_Tra_0001 254;
BA_ "SystemSignalLongSymbol" SG_ 1435 SRDO1_communication_par_Tra_0001 "SRDO1_communication_par_Transmission_type_1301_04";
BA_ "GenSigStartValue" SG_ 1435 SRDO1_communication_par_ref_0001 25;
BA_ "SystemSignalLongSymbol" SG_ 1435 SRDO1_communication_par_ref_0001 "SRDO1_communication_par_refresh_time_1301_02";
BA_ "GenSigStartValue" SG_ 1435 SRDO1_communication_par_Inf_0001 1;
BA_ "SystemSignalLongSymbol" SG_ 1435 SRDO1_communication_par_Inf_0001 "SRDO1_communication_par_Information_direction_1301_01";
BA_ "GenSigStartValue" SG_ 1435 Highest_sub_index_supported_0006 6;
BA_ "SystemSignalLongSymbol" SG_ 1435 Highest_sub_index_supported_0006 "Highest_sub_index_supported_1301_00";
BA_ "GenSigStartValue" SG_ 1435 Revision_number_1018_03 256;
BA_ "GenSigStartValue" SG_ 1435 Product_Code_1018_02 4660;
BA_ "GenSigStartValue" SG_ 1435 Vendor_Id_1018_01 5;
BA_ "GenSigStartValue" SG_ 1435 Highest_sub_index_supported_0007 4;
BA_ "SystemSignalLongSymbol" SG_ 1435 Highest_sub_index_supported_0007 "Highest_sub_index_supported_1018_00";
BA_ "GenSigStartValue" SG_ 1435 Producer_Heartbeat_Time_1017 500;
BA_ "SystemSignalLongSymbol" SG_ 1435 Consumer_Heartbeat_Time16_1_0001 "Consumer_Heartbeat_Time16_1016_10";
BA_ "SystemSignalLongSymbol" SG_ 1435 Consumer_Heartbeat_Time15_1_0001 "Consumer_Heartbeat_Time15_1016_0F";
BA_ "SystemSignalLongSymbol" SG_ 1435 Consumer_Heartbeat_Time14_1_0001 "Consumer_Heartbeat_Time14_1016_0E";
BA_ "SystemSignalLongSymbol" SG_ 1435 Consumer_Heartbeat_Time13_1_0001 "Consumer_Heartbeat_Time13_1016_0D";
BA_ "SystemSignalLongSymbol" SG_ 1435 Consumer_Heartbeat_Time12_1_0001 "Consumer_Heartbeat_Time12_1016_0C";
BA_ "SystemSignalLongSymbol" SG_ 1435 Consumer_Heartbeat_Time11_1_0001 "Consumer_Heartbeat_Time11_1016_0B";
BA_ "SystemSignalLongSymbol" SG_ 1435 Consumer_Heartbeat_Time10_1_0001 "Consumer_Heartbeat_Time10_1016_0A";
BA_ "GenSigStartValue" SG_ 1435 NrOfObjects_1016_00 16;
BA_ "GenSigStartValue" SG_ 1435 COB_ID_EMCY_1014 155;
BA_ "SystemSignalLongSymbol" SG_ 1435 Restore_all_Default_Paramet_0001 "Restore_all_Default_Parameters_1011_01";
BA_ "GenSigStartValue" SG_ 1435 Highest_sub_index_supported_0008 1;
BA_ "SystemSignalLongSymbol" SG_ 1435 Highest_sub_index_supported_0008 "Highest_sub_index_supported_1011_00";
BA_ "GenSigStartValue" SG_ 1435 Highest_sub_index_supported_0009 1;
BA_ "SystemSignalLongSymbol" SG_ 1435 Highest_sub_index_supported_0009 "Highest_sub_index_supported_1010_00";
BA_ "GenSigStartValue" SG_ 1435 Life_Time_Factor_100D 244;
BA_ "GenSigStartValue" SG_ 1435 Guard_Time_100C 2000;
BA_ "GenSigStartValue" SG_ 1435 Sync_Window_Length_1007 50000;
BA_ "GenSigStartValue" SG_ 1435 Communication_Cycle_Period_1006 100000;
BA_ "GenSigStartValue" SG_ 1435 COB_ID_SYNC_1005 2147483776;
BA_ "GenSigStartValue" SG_ 1435 Device_Type_1000 197009;
BA_ "GenSigStartValue" SG_ 1435 Index 4096;
BA_ "GenSigStartValue" SG_ 1563 Pressure_1_inverted_6402_02 4294967295;
BA_ "GenSigStartValue" SG_ 1563 Highest_sub_index_supported_0010 2;
BA_ "SystemSignalLongSymbol" SG_ 1563 Highest_sub_index_supported_0010 "Highest_sub_index_supported_6402_00";
BA_ "GenSigStartValue" SG_ 1563 Safety_Checksum_13FF_01 51386;
BA_ "GenSigStartValue" SG_ 1563 Safety_checksum_Number_of_e_0002 1;
BA_ "SystemSignalLongSymbol" SG_ 1563 Safety_checksum_Number_of_e_0002 "Safety_checksum_Number_of_entries_13FF_00";
BA_ "GenSigStartValue" SG_ 1563 Configuration_valid_13FE 165;
BA_ "GenSigStartValue" SG_ 1563 SRDO1_mapping_inv_Byte1_1381_02 1677853216;
BA_ "GenSigStartValue" SG_ 1563 SRDO1_mapping_Byte1_1381_01 1677852960;
BA_ "GenSigStartValue" SG_ 1563 SRDO1_Number_of_mapped_obje_0002 2;
BA_ "SystemSignalLongSymbol" SG_ 1563 SRDO1_Number_of_mapped_obje_0002 "SRDO1_Number_of_mapped_objects_1381_00";
BA_ "GenSigStartValue" SG_ 1563 SRDO1_communication_par_COB_0004 260;
BA_ "SystemSignalLongSymbol" SG_ 1563 SRDO1_communication_par_COB_0004 "SRDO1_communication_par_COB_ID_2_1301_06";
BA_ "GenSigStartValue" SG_ 1563 SRDO1_communication_par_COB_0005 259;
BA_ "SystemSignalLongSymbol" SG_ 1563 SRDO1_communication_par_COB_0005 "SRDO1_communication_par_COB_ID_1_1301_05";
BA_ "GenSigStartValue" SG_ 1563 SRDO1_communication_par_Tra_0002 254;
BA_ "SystemSignalLongSymbol" SG_ 1563 SRDO1_communication_par_Tra_0002 "SRDO1_communication_par_Transmission_type_1301_04";
BA_ "GenSigStartValue" SG_ 1563 SRDO1_communication_par_ref_0002 25;
BA_ "SystemSignalLongSymbol" SG_ 1563 SRDO1_communication_par_ref_0002 "SRDO1_communication_par_refresh_time_1301_02";
BA_ "GenSigStartValue" SG_ 1563 SRDO1_communication_par_Inf_0002 1;
BA_ "SystemSignalLongSymbol" SG_ 1563 SRDO1_communication_par_Inf_0002 "SRDO1_communication_par_Information_direction_1301_01";
BA_ "GenSigStartValue" SG_ 1563 Highest_sub_index_supported_0011 6;
BA_ "SystemSignalLongSymbol" SG_ 1563 Highest_sub_index_supported_0011 "Highest_sub_index_supported_1301_00";
BA_ "GenSigStartValue" SG_ 1563 Revision_number_1018_03 256;
BA_ "GenSigStartValue" SG_ 1563 Product_Code_1018_02 4660;
BA_ "GenSigStartValue" SG_ 1563 Vendor_Id_1018_01 5;
BA_ "GenSigStartValue" SG_ 1563 Highest_sub_index_supported_0012 4;
BA_ "SystemSignalLongSymbol" SG_ 1563 Highest_sub_index_supported_0012 "Highest_sub_index_supported_1018_00";
BA_ "GenSigStartValue" SG_ 1563 Producer_Heartbeat_Time_1017 500;
BA_ "SystemSignalLongSymbol" SG_ 1563 Consumer_Heartbeat_Time16_1_0002 "Consumer_Heartbeat_Time16_1016_10";
BA_ "SystemSignalLongSymbol" SG_ 1563 Consumer_Heartbeat_Time15_1_0002 "Consumer_Heartbeat_Time15_1016_0F";
BA_ "SystemSignalLongSymbol" SG_ 1563 Consumer_Heartbeat_Time14_1_0002 "Consumer_Heartbeat_Time14_1016_0E";
BA_ "SystemSignalLongSymbol" SG_ 1563 Consumer_Heartbeat_Time13_1_0002 "Consumer_Heartbeat_Time13_1016_0D";
BA_ "SystemSignalLongSymbol" SG_ 1563 Consumer_Heartbeat_Time12_1_0002 "Consumer_Heartbeat_Time12_1016_0C";
BA_ "SystemSignalLongSymbol" SG_ 1563 Consumer_Heartbeat_Time11_1_0002 "Consumer_Heartbeat_Time11_1016_0B";
BA_ "SystemSignalLongSymbol" SG_ 1563 Consumer_Heartbeat_Time10_1_0002 "Consumer_Heartbeat_Time10_1016_0A";
BA_ "GenSigStartValue" SG_ 1563 NrOfObjects_1016_00 16;
BA_ "GenSigStartValue" SG_ 1563 COB_ID_EMCY_1014 155;
BA_ "SystemSignalLongSymbol" SG_ 1563 Restore_all_Default_Paramet_0002 "Restore_all_Default_Parameters_1011_01";
BA_ "GenSigStartValue" SG_ 1563 Highest_sub_index_supported_0013 1;
BA_ "SystemSignalLongSymbol" SG_ 1563 Highest_sub_index_supported_0013 "Highest_sub_index_supported_1011_00";
BA_ "GenSigStartValue" SG_ 1563 Highest_sub_index_supported_0014 1;
BA_ "SystemSignalLongSymbol" SG_ 1563 Highest_sub_index_supported_0014 "Highest_sub_index_supported_1010_00";
BA_ "GenSigStartValue" SG_ 1563 Life_Time_Factor_100D 244;
BA_ "GenSigStartValue" SG_ 1563 Guard_Time_100C 2000;
BA_ "GenSigStartValue" SG_ 1563 Sync_Window_Length_1007 50000;
BA_ "GenSigStartValue" SG_ 1563 Communication_Cycle_Period_1006 100000;
BA_ "GenSigStartValue" SG_ 1563 COB_ID_SYNC_1005 2147483776;
BA_ "GenSigStartValue" SG_ 1563 Device_Type_1000 197009;
BA_ "GenSigStartValue" SG_ 1563 Index 4096;
BA_ "GenSigStartValue" SG_ 1431 Pressure_1_inverted_6402_02 4294967295;
BA_ "GenSigStartValue" SG_ 1431 Highest_sub_index_supported_0015 2;
BA_ "SystemSignalLongSymbol" SG_ 1431 Highest_sub_index_supported_0015 "Highest_sub_index_supported_6402_00";
BA_ "GenSigStartValue" SG_ 1431 Safety_Checksum_13FF_01 45774;
BA_ "GenSigStartValue" SG_ 1431 Safety_checksum_Number_of_e_0003 1;
BA_ "SystemSignalLongSymbol" SG_ 1431 Safety_checksum_Number_of_e_0003 "Safety_checksum_Number_of_entries_13FF_00";
BA_ "GenSigStartValue" SG_ 1431 Configuration_valid_13FE 165;
BA_ "GenSigStartValue" SG_ 1431 SRDO1_mapping_inv_Byte1_1381_02 1677853216;
BA_ "GenSigStartValue" SG_ 1431 SRDO1_mapping_Byte1_1381_01 1677852960;
BA_ "GenSigStartValue" SG_ 1431 SRDO1_Number_of_mapped_obje_0003 2;
BA_ "SystemSignalLongSymbol" SG_ 1431 SRDO1_Number_of_mapped_obje_0003 "SRDO1_Number_of_mapped_objects_1381_00";
BA_ "GenSigStartValue" SG_ 1431 SRDO1_communication_par_COB_0006 258;
BA_ "SystemSignalLongSymbol" SG_ 1431 SRDO1_communication_par_COB_0006 "SRDO1_communication_par_COB_ID_2_1301_06";
BA_ "GenSigStartValue" SG_ 1431 SRDO1_communication_par_COB_0007 257;
BA_ "SystemSignalLongSymbol" SG_ 1431 SRDO1_communication_par_COB_0007 "SRDO1_communication_par_COB_ID_1_1301_05";
BA_ "GenSigStartValue" SG_ 1431 SRDO1_communication_par_Tra_0003 254;
BA_ "SystemSignalLongSymbol" SG_ 1431 SRDO1_communication_par_Tra_0003 "SRDO1_communication_par_Transmission_type_1301_04";
BA_ "GenSigStartValue" SG_ 1431 SRDO1_communication_par_ref_0003 25;
BA_ "SystemSignalLongSymbol" SG_ 1431 SRDO1_communication_par_ref_0003 "SRDO1_communication_par_refresh_time_1301_02";
BA_ "GenSigStartValue" SG_ 1431 SRDO1_communication_par_Inf_0003 1;
BA_ "SystemSignalLongSymbol" SG_ 1431 SRDO1_communication_par_Inf_0003 "SRDO1_communication_par_Information_direction_1301_01";
BA_ "GenSigStartValue" SG_ 1431 Highest_sub_index_supported_0016 6;
BA_ "SystemSignalLongSymbol" SG_ 1431 Highest_sub_index_supported_0016 "Highest_sub_index_supported_1301_00";
BA_ "GenSigStartValue" SG_ 1431 Revision_number_1018_03 256;
BA_ "GenSigStartValue" SG_ 1431 Product_Code_1018_02 4660;
BA_ "GenSigStartValue" SG_ 1431 Vendor_Id_1018_01 5;
BA_ "GenSigStartValue" SG_ 1431 Highest_sub_index_supported_0017 4;
BA_ "SystemSignalLongSymbol" SG_ 1431 Highest_sub_index_supported_0017 "Highest_sub_index_supported_1018_00";
BA_ "GenSigStartValue" SG_ 1431 Producer_Heartbeat_Time_1017 500;
BA_ "SystemSignalLongSymbol" SG_ 1431 Consumer_Heartbeat_Time16_1_0003 "Consumer_Heartbeat_Time16_1016_10";
BA_ "SystemSignalLongSymbol" SG_ 1431 Consumer_Heartbeat_Time15_1_0003 "Consumer_Heartbeat_Time15_1016_0F";
BA_ "SystemSignalLongSymbol" SG_ 1431 Consumer_Heartbeat_Time14_1_0003 "Consumer_Heartbeat_Time14_1016_0E";
BA_ "SystemSignalLongSymbol" SG_ 1431 Consumer_Heartbeat_Time13_1_0003 "Consumer_Heartbeat_Time13_1016_0D";
BA_ "SystemSignalLongSymbol" SG_ 1431 Consumer_Heartbeat_Time12_1_0003 "Consumer_Heartbeat_Time12_1016_0C";
BA_ "SystemSignalLongSymbol" SG_ 1431 Consumer_Heartbeat_Time11_1_0003 "Consumer_Heartbeat_Time11_1016_0B";
BA_ "SystemSignalLongSymbol" SG_ 1431 Consumer_Heartbeat_Time10_1_0003 "Consumer_Heartbeat_Time10_1016_0A";
BA_ "GenSigStartValue" SG_ 1431 NrOfObjects_1016_00 16;
BA_ "GenSigStartValue" SG_ 1431 COB_ID_EMCY_1014 151;
BA_ "SystemSignalLongSymbol" SG_ 1431 Restore_all_Default_Paramet_0003 "Restore_all_Default_Parameters_1011_01";
BA_ "GenSigStartValue" SG_ 1431 Highest_sub_index_supported_0018 1;
BA_ "SystemSignalLongSymbol" SG_ 1431 Highest_sub_index_supported_0018 "Highest_sub_index_supported_1011_00";
BA_ "GenSigStartValue" SG_ 1431 Highest_sub_index_supported_0019 1;
BA_ "SystemSignalLongSymbol" SG_ 1431 Highest_sub_index_supported_0019 "Highest_sub_index_supported_1010_00";
BA_ "GenSigStartValue" SG_ 1431 Life_Time_Factor_100D 244;
BA_ "GenSigStartValue" SG_ 1431 Guard_Time_100C 2000;
BA_ "GenSigStartValue" SG_ 1431 Sync_Window_Length_1007 50000;
BA_ "GenSigStartValue" SG_ 1431 Communication_Cycle_Period_1006 100000;
BA_ "GenSigStartValue" SG_ 1431 COB_ID_SYNC_1005 2147483776;
BA_ "GenSigStartValue" SG_ 1431 Device_Type_1000 197009;
BA_ "GenSigStartValue" SG_ 1431 Index 4096;
BA_ "GenSigStartValue" SG_ 1559 Pressure_1_inverted_6402_02 4294967295;
BA_ "GenSigStartValue" SG_ 1559 Highest_sub_index_supported_0020 2;
BA_ "SystemSignalLongSymbol" SG_ 1559 Highest_sub_index_supported_0020 "Highest_sub_index_supported_6402_00";
BA_ "GenSigStartValue" SG_ 1559 Safety_Checksum_13FF_01 45774;
BA_ "GenSigStartValue" SG_ 1559 Safety_checksum_Number_of_e_0004 1;
BA_ "SystemSignalLongSymbol" SG_ 1559 Safety_checksum_Number_of_e_0004 "Safety_checksum_Number_of_entries_13FF_00";
BA_ "GenSigStartValue" SG_ 1559 Configuration_valid_13FE 165;
BA_ "GenSigStartValue" SG_ 1559 SRDO1_mapping_inv_Byte1_1381_02 1677853216;
BA_ "GenSigStartValue" SG_ 1559 SRDO1_mapping_Byte1_1381_01 1677852960;
BA_ "GenSigStartValue" SG_ 1559 SRDO1_Number_of_mapped_obje_0004 2;
BA_ "SystemSignalLongSymbol" SG_ 1559 SRDO1_Number_of_mapped_obje_0004 "SRDO1_Number_of_mapped_objects_1381_00";
BA_ "GenSigStartValue" SG_ 1559 SRDO1_communication_par_COB_0008 258;
BA_ "SystemSignalLongSymbol" SG_ 1559 SRDO1_communication_par_COB_0008 "SRDO1_communication_par_COB_ID_2_1301_06";
BA_ "GenSigStartValue" SG_ 1559 SRDO1_communication_par_COB_0009 257;
BA_ "SystemSignalLongSymbol" SG_ 1559 SRDO1_communication_par_COB_0009 "SRDO1_communication_par_COB_ID_1_1301_05";
BA_ "GenSigStartValue" SG_ 1559 SRDO1_communication_par_Tra_0004 254;
BA_ "SystemSignalLongSymbol" SG_ 1559 SRDO1_communication_par_Tra_0004 "SRDO1_communication_par_Transmission_type_1301_04";
BA_ "GenSigStartValue" SG_ 1559 SRDO1_communication_par_ref_0004 25;
BA_ "SystemSignalLongSymbol" SG_ 1559 SRDO1_communication_par_ref_0004 "SRDO1_communication_par_refresh_time_1301_02";
BA_ "GenSigStartValue" SG_ 1559 SRDO1_communication_par_Inf_0004 1;
BA_ "SystemSignalLongSymbol" SG_ 1559 SRDO1_communication_par_Inf_0004 "SRDO1_communication_par_Information_direction_1301_01";
BA_ "GenSigStartValue" SG_ 1559 Highest_sub_index_supported_0021 6;
BA_ "SystemSignalLongSymbol" SG_ 1559 Highest_sub_index_supported_0021 "Highest_sub_index_supported_1301_00";
BA_ "GenSigStartValue" SG_ 1559 Revision_number_1018_03 256;
BA_ "GenSigStartValue" SG_ 1559 Product_Code_1018_02 4660;
BA_ "GenSigStartValue" SG_ 1559 Vendor_Id_1018_01 5;
BA_ "GenSigStartValue" SG_ 1559 Highest_sub_index_supported_0022 4;
BA_ "SystemSignalLongSymbol" SG_ 1559 Highest_sub_index_supported_0022 "Highest_sub_index_supported_1018_00";
BA_ "GenSigStartValue" SG_ 1559 Producer_Heartbeat_Time_1017 500;
BA_ "SystemSignalLongSymbol" SG_ 1559 Consumer_Heartbeat_Time16_1_0004 "Consumer_Heartbeat_Time16_1016_10";
BA_ "SystemSignalLongSymbol" SG_ 1559 Consumer_Heartbeat_Time15_1_0004 "Consumer_Heartbeat_Time15_1016_0F";
BA_ "SystemSignalLongSymbol" SG_ 1559 Consumer_Heartbeat_Time14_1_0004 "Consumer_Heartbeat_Time14_1016_0E";
BA_ "SystemSignalLongSymbol" SG_ 1559 Consumer_Heartbeat_Time13_1_0004 "Consumer_Heartbeat_Time13_1016_0D";
BA_ "SystemSignalLongSymbol" SG_ 1559 Consumer_Heartbeat_Time12_1_0004 "Consumer_Heartbeat_Time12_1016_0C";
BA_ "SystemSignalLongSymbol" SG_ 1559 Consumer_Heartbeat_Time11_1_0004 "Consumer_Heartbeat_Time11_1016_0B";
BA_ "SystemSignalLongSymbol" SG_ 1559 Consumer_Heartbeat_Time10_1_0004 "Consumer_Heartbeat_Time10_1016_0A";
BA_ "GenSigStartValue" SG_ 1559 NrOfObjects_1016_00 16;
BA_ "GenSigStartValue" SG_ 1559 COB_ID_EMCY_1014 151;
BA_ "SystemSignalLongSymbol" SG_ 1559 Restore_all_Default_Paramet_0004 "Restore_all_Default_Parameters_1011_01";
BA_ "GenSigStartValue" SG_ 1559 Highest_sub_index_supported_0023 1;
BA_ "SystemSignalLongSymbol" SG_ 1559 Highest_sub_index_supported_0023 "Highest_sub_index_supported_1011_00";
BA_ "GenSigStartValue" SG_ 1559 Highest_sub_index_supported_0024 1;
BA_ "SystemSignalLongSymbol" SG_ 1559 Highest_sub_index_supported_0024 "Highest_sub_index_supported_1010_00";
BA_ "GenSigStartValue" SG_ 1559 Life_Time_Factor_100D 244;
BA_ "GenSigStartValue" SG_ 1559 Guard_Time_100C 2000;
BA_ "GenSigStartValue" SG_ 1559 Sync_Window_Length_1007 50000;
BA_ "GenSigStartValue" SG_ 1559 Communication_Cycle_Period_1006 100000;
BA_ "GenSigStartValue" SG_ 1559 COB_ID_SYNC_1005 2147483776;
BA_ "GenSigStartValue" SG_ 1559 Device_Type_1000 197009;
BA_ "GenSigStartValue" SG_ 1559 Index 4096;
BA_ "GenSigStartValue" SG_ 1418 UInt32_2_A643_03 4294967295;
BA_ "GenSigStartValue" SG_ 1418 UInt32_2_A643_02 4294967295;
BA_ "GenSigStartValue" SG_ 1418 UInt32_1_A643_01 4294967295;
BA_ "GenSigStartValue" SG_ 1418 NrOfObjects_A643_00 3;
BA_ "GenSigStartValue" SG_ 1418 Int16_2_A642_03 4294967295;
BA_ "GenSigStartValue" SG_ 1418 Int16_2_A642_02 4294967295;
BA_ "GenSigStartValue" SG_ 1418 Int16_1_A642_01 4294967295;
BA_ "GenSigStartValue" SG_ 1418 NrOfObjects_A642_00 3;
BA_ "GenSigStartValue" SG_ 1418 Pressure_1_Sensor3_Inverted_A641 4294967295;
BA_ "SystemSignalLongSymbol" SG_ 1418 Pressure_1_Sensor3_Inverted_A641 "Pressure_1_Sensor3_Inverted_A641_03";
BA_ "GenSigStartValue" SG_ 1418 Pressure_1_Sensor2_Inverted_A641 4294967295;
BA_ "SystemSignalLongSymbol" SG_ 1418 Pressure_1_Sensor2_Inverted_A641 "Pressure_1_Sensor2_Inverted_A641_02";
BA_ "GenSigStartValue" SG_ 1418 Pressure_1_Sensor1_Inverted_A641 4294967295;
BA_ "SystemSignalLongSymbol" SG_ 1418 Pressure_1_Sensor1_Inverted_A641 "Pressure_1_Sensor1_Inverted_A641_01";
BA_ "GenSigStartValue" SG_ 1418 NrOfObjects_A641_00 3;
BA_ "GenSigStartValue" SG_ 1418 NrOfObjects_A640_00 3;
BA_ "GenSigStartValue" SG_ 1418 NrOfObjects_1F88_00 127;
VAL_ 1820 State 127 "PreOperational" 5 "Operational" 4 "Stopped" 0 "Bootup" ;
VAL_ 1436 SubIndex_6402 2 "Pressure_1_inverted" 1 "Pressure_1" 0 "Highest sub-index supported" ;
VAL_ 1436 SubIndex_13FF 1 "Safety_Checksum" 0 "Safety_checksum_Number_of_entries" ;
VAL_ 1436 SubIndex_13FE 0 "Configuration_valid" ;
VAL_ 1436 SubIndex_1381 2 "SRDO1_mapping_inv_Byte1" 1 "SRDO1_mapping_Byte1" 0 "SRDO1_Number_of_mapped_objects" ;
VAL_ 1436 SubIndex_1301 6 "SRDO1_communication_par_COB_ID_2" 5 "SRDO1_communication_par_COB_ID_1" 4 "SRDO1_communication_par_Transmission_type" 2 "SRDO1_communication_par_refresh_time" 1 "SRDO1_communication_par_Information_direction" 0 "Highest sub-index supported" ;
VAL_ 1436 SubIndex_1018 4 "Serial number" 3 "Revision number" 2 "Product Code" 1 "Vendor Id" 0 "Highest sub-index supported" ;
VAL_ 1436 SubIndex_1017 0 "Producer Heartbeat Time" ;
VAL_ 1436 SubIndex_1016 16 "Consumer Heartbeat Time16" 15 "Consumer Heartbeat Time15" 14 "Consumer Heartbeat Time14" 13 "Consumer Heartbeat Time13" 12 "Consumer Heartbeat Time12" 11 "Consumer Heartbeat Time11" 10 "Consumer Heartbeat Time10" 9 "Consumer Heartbeat Time9" 8 "Consumer Heartbeat Time8" 7 "Consumer Heartbeat Time7" 6 "Consumer Heartbeat Time6" 5 "Consumer Heartbeat Time5" 4 "Consumer Heartbeat Time4" 3 "Consumer Heartbeat Time3" 2 "Consumer Heartbeat Time2" 1 "Consumer Heartbeat Time1" 0 "NrOfObjects" ;
VAL_ 1436 SubIndex_1014 0 "COB-ID EMCY" ;
VAL_ 1436 SubIndex_1011 1 "Restore all Default Parameters" 0 "Highest sub-index supported" ;
VAL_ 1436 SubIndex_1010 1 "Save all Parameters" 0 "Highest sub-index supported" ;
VAL_ 1436 SubIndex_100D 0 "Life Time Factor" ;
VAL_ 1436 SubIndex_100C 0 "Guard Time" ;
VAL_ 1436 SubIndex_1007 0 "Sync_Window Length" ;
VAL_ 1436 SubIndex_1006 0 "Communication Cycle Period" ;
VAL_ 1436 SubIndex_1005 0 "COB-ID SYNC" ;
VAL_ 1436 SubIndex_1003 9 "Standard error field" 8 "Standard error field" 7 "Standard error field" 6 "Standard error field" 5 "Standard error field" 4 "Standard error field" 3 "Standard error field" 2 "Standard error field" 1 "Standard error field" 0 "Number of Errors" ;
VAL_ 1436 SubIndex_1001 0 "Error Register" ;
VAL_ 1436 SubIndex_1000 0 "Device Type" ;
VAL_ 1436 Index 25602 "Pressure 32-Bit" 5119 "Safety_configuration_checksum" 5118 "Configuration_valid" 4993 "Safety_SRDO1_mapping_parameter" 4865 "Safety_SRDO1_communication_parameter" 4120 "Identity Object" 4119 "Producer Heartbeat Time" 4118 "Consumer Heartbeat Time" 4116 "COB-ID EMCY" 4113 "Restore Default Parameters" 4112 "Store Parameter Field" 4109 "Life Time Factor" 4108 "Guard Time" 4103 "Sync_Window Length" 4102 "Communication Cycle Period" 4101 "COB-ID SYNC" 4099 "Pre-defined Error Field" 4097 "Error Register" 4096 "Device Type" ;
VAL_ 1436 TransferType 1 "Expedited transfer" 0 "Normal transfer" ;
VAL_ 1436 SizeIndicator 1 "Size is indicated" 0 "Size is not indicated" ;
VAL_ 1436 SCS 2 "Upload" 1 "Download" ;
VAL_ 1564 SubIndex_6402 2 "Pressure_1_inverted" 1 "Pressure_1" 0 "Highest sub-index supported" ;
VAL_ 1564 SubIndex_13FF 1 "Safety_Checksum" 0 "Safety_checksum_Number_of_entries" ;
VAL_ 1564 SubIndex_13FE 0 "Configuration_valid" ;
VAL_ 1564 SubIndex_1381 2 "SRDO1_mapping_inv_Byte1" 1 "SRDO1_mapping_Byte1" 0 "SRDO1_Number_of_mapped_objects" ;
VAL_ 1564 SubIndex_1301 6 "SRDO1_communication_par_COB_ID_2" 5 "SRDO1_communication_par_COB_ID_1" 4 "SRDO1_communication_par_Transmission_type" 2 "SRDO1_communication_par_refresh_time" 1 "SRDO1_communication_par_Information_direction" 0 "Highest sub-index supported" ;
VAL_ 1564 SubIndex_1018 4 "Serial number" 3 "Revision number" 2 "Product Code" 1 "Vendor Id" 0 "Highest sub-index supported" ;
VAL_ 1564 SubIndex_1017 0 "Producer Heartbeat Time" ;
VAL_ 1564 SubIndex_1016 16 "Consumer Heartbeat Time16" 15 "Consumer Heartbeat Time15" 14 "Consumer Heartbeat Time14" 13 "Consumer Heartbeat Time13" 12 "Consumer Heartbeat Time12" 11 "Consumer Heartbeat Time11" 10 "Consumer Heartbeat Time10" 9 "Consumer Heartbeat Time9" 8 "Consumer Heartbeat Time8" 7 "Consumer Heartbeat Time7" 6 "Consumer Heartbeat Time6" 5 "Consumer Heartbeat Time5" 4 "Consumer Heartbeat Time4" 3 "Consumer Heartbeat Time3" 2 "Consumer Heartbeat Time2" 1 "Consumer Heartbeat Time1" 0 "NrOfObjects" ;
VAL_ 1564 SubIndex_1014 0 "COB-ID EMCY" ;
VAL_ 1564 SubIndex_1011 1 "Restore all Default Parameters" 0 "Highest sub-index supported" ;
VAL_ 1564 SubIndex_1010 1 "Save all Parameters" 0 "Highest sub-index supported" ;
VAL_ 1564 SubIndex_100D 0 "Life Time Factor" ;
VAL_ 1564 SubIndex_100C 0 "Guard Time" ;
VAL_ 1564 SubIndex_1007 0 "Sync_Window Length" ;
VAL_ 1564 SubIndex_1006 0 "Communication Cycle Period" ;
VAL_ 1564 SubIndex_1005 0 "COB-ID SYNC" ;
VAL_ 1564 SubIndex_1003 9 "Standard error field" 8 "Standard error field" 7 "Standard error field" 6 "Standard error field" 5 "Standard error field" 4 "Standard error field" 3 "Standard error field" 2 "Standard error field" 1 "Standard error field" 0 "Number of Errors" ;
VAL_ 1564 SubIndex_1001 0 "Error Register" ;
VAL_ 1564 SubIndex_1000 0 "Device Type" ;
VAL_ 1564 Index 25602 "Pressure 32-Bit" 5119 "Safety_configuration_checksum" 5118 "Configuration_valid" 4993 "Safety_SRDO1_mapping_parameter" 4865 "Safety_SRDO1_communication_parameter" 4120 "Identity Object" 4119 "Producer Heartbeat Time" 4118 "Consumer Heartbeat Time" 4116 "COB-ID EMCY" 4113 "Restore Default Parameters" 4112 "Store Parameter Field" 4109 "Life Time Factor" 4108 "Guard Time" 4103 "Sync_Window Length" 4102 "Communication Cycle Period" 4101 "COB-ID SYNC" 4099 "Pre-defined Error Field" 4097 "Error Register" 4096 "Device Type" ;
VAL_ 1564 TransferType 1 "Expedited transfer" 0 "Normal transfer" ;
VAL_ 1564 SizeIndicator 1 "Size is indicated" 0 "Size is not indicated" ;
VAL_ 1564 CCS 2 "Upload" 1 "Download" ;
VAL_ 156 ErrorCode 13088 "(DS-401) Output voltage too low" 13072 "(DS-401) Output voltage too high" 12832 "(DS-401) Internal voltage too low" 12816 "(DS-401) Internal voltage too high" 12576 "(DS-401) Input voltage too low" 12560 "(DS-401) Input voltage too high" 9008 "(DS-401) Load dump at outputs" 8992 "(DS-401) Short circuit at outputs" 8976 "(DS-401) Current at outputs too high (overload)" 128 "(DS-401) Warning: Analogue inputs disabled" 33360 "RPDO timeout" 33344 "Unexpected SYNC data length" 33328 "DAM MPDO not processed, destination object not available" 33312 "PDO length exceeded" 33296 "PDO not processed due to length error" 33104 "Transmit COB-ID collision" 33088 "Recovered from bus off state" 33072 "Life guard error or heartbeat error" 33056 "CAN in error passive mode" 33040 "CAN overrun (objects lost)" ;
VAL_ 1819 State 127 "PreOperational" 5 "Operational" 4 "Stopped" 0 "Bootup" ;
VAL_ 1435 SubIndex_6402 2 "Pressure_1_inverted" 1 "Pressure_1" 0 "Highest sub-index supported" ;
VAL_ 1435 SubIndex_13FF 1 "Safety_Checksum" 0 "Safety_checksum_Number_of_entries" ;
VAL_ 1435 SubIndex_13FE 0 "Configuration_valid" ;
VAL_ 1435 SubIndex_1381 2 "SRDO1_mapping_inv_Byte1" 1 "SRDO1_mapping_Byte1" 0 "SRDO1_Number_of_mapped_objects" ;
VAL_ 1435 SubIndex_1301 6 "SRDO1_communication_par_COB_ID_2" 5 "SRDO1_communication_par_COB_ID_1" 4 "SRDO1_communication_par_Transmission_type" 2 "SRDO1_communication_par_refresh_time" 1 "SRDO1_communication_par_Information_direction" 0 "Highest sub-index supported" ;
VAL_ 1435 SubIndex_1018 4 "Serial number" 3 "Revision number" 2 "Product Code" 1 "Vendor Id" 0 "Highest sub-index supported" ;
VAL_ 1435 SubIndex_1017 0 "Producer Heartbeat Time" ;
VAL_ 1435 SubIndex_1016 16 "Consumer Heartbeat Time16" 15 "Consumer Heartbeat Time15" 14 "Consumer Heartbeat Time14" 13 "Consumer Heartbeat Time13" 12 "Consumer Heartbeat Time12" 11 "Consumer Heartbeat Time11" 10 "Consumer Heartbeat Time10" 9 "Consumer Heartbeat Time9" 8 "Consumer Heartbeat Time8" 7 "Consumer Heartbeat Time7" 6 "Consumer Heartbeat Time6" 5 "Consumer Heartbeat Time5" 4 "Consumer Heartbeat Time4" 3 "Consumer Heartbeat Time3" 2 "Consumer Heartbeat Time2" 1 "Consumer Heartbeat Time1" 0 "NrOfObjects" ;
VAL_ 1435 SubIndex_1014 0 "COB-ID EMCY" ;
VAL_ 1435 SubIndex_1011 1 "Restore all Default Parameters" 0 "Highest sub-index supported" ;
VAL_ 1435 SubIndex_1010 1 "Save all Parameters" 0 "Highest sub-index supported" ;
VAL_ 1435 SubIndex_100D 0 "Life Time Factor" ;
VAL_ 1435 SubIndex_100C 0 "Guard Time" ;
VAL_ 1435 SubIndex_1007 0 "Sync_Window Length" ;
VAL_ 1435 SubIndex_1006 0 "Communication Cycle Period" ;
VAL_ 1435 SubIndex_1005 0 "COB-ID SYNC" ;
VAL_ 1435 SubIndex_1003 9 "Standard error field" 8 "Standard error field" 7 "Standard error field" 6 "Standard error field" 5 "Standard error field" 4 "Standard error field" 3 "Standard error field" 2 "Standard error field" 1 "Standard error field" 0 "Number of Errors" ;
VAL_ 1435 SubIndex_1001 0 "Error Register" ;
VAL_ 1435 SubIndex_1000 0 "Device Type" ;
VAL_ 1435 Index 25602 "Pressure 32-Bit" 5119 "Safety_configuration_checksum" 5118 "Configuration_valid" 4993 "Safety_SRDO1_mapping_parameter" 4865 "Safety_SRDO1_communication_parameter" 4120 "Identity Object" 4119 "Producer Heartbeat Time" 4118 "Consumer Heartbeat Time" 4116 "COB-ID EMCY" 4113 "Restore Default Parameters" 4112 "Store Parameter Field" 4109 "Life Time Factor" 4108 "Guard Time" 4103 "Sync_Window Length" 4102 "Communication Cycle Period" 4101 "COB-ID SYNC" 4099 "Pre-defined Error Field" 4097 "Error Register" 4096 "Device Type" ;
VAL_ 1435 TransferType 1 "Expedited transfer" 0 "Normal transfer" ;
VAL_ 1435 SizeIndicator 1 "Size is indicated" 0 "Size is not indicated" ;
VAL_ 1435 SCS 2 "Upload" 1 "Download" ;
VAL_ 1563 SubIndex_6402 2 "Pressure_1_inverted" 1 "Pressure_1" 0 "Highest sub-index supported" ;
VAL_ 1563 SubIndex_13FF 1 "Safety_Checksum" 0 "Safety_checksum_Number_of_entries" ;
VAL_ 1563 SubIndex_13FE 0 "Configuration_valid" ;
VAL_ 1563 SubIndex_1381 2 "SRDO1_mapping_inv_Byte1" 1 "SRDO1_mapping_Byte1" 0 "SRDO1_Number_of_mapped_objects" ;
VAL_ 1563 SubIndex_1301 6 "SRDO1_communication_par_COB_ID_2" 5 "SRDO1_communication_par_COB_ID_1" 4 "SRDO1_communication_par_Transmission_type" 2 "SRDO1_communication_par_refresh_time" 1 "SRDO1_communication_par_Information_direction" 0 "Highest sub-index supported" ;
VAL_ 1563 SubIndex_1018 4 "Serial number" 3 "Revision number" 2 "Product Code" 1 "Vendor Id" 0 "Highest sub-index supported" ;
VAL_ 1563 SubIndex_1017 0 "Producer Heartbeat Time" ;
VAL_ 1563 SubIndex_1016 16 "Consumer Heartbeat Time16" 15 "Consumer Heartbeat Time15" 14 "Consumer Heartbeat Time14" 13 "Consumer Heartbeat Time13" 12 "Consumer Heartbeat Time12" 11 "Consumer Heartbeat Time11" 10 "Consumer Heartbeat Time10" 9 "Consumer Heartbeat Time9" 8 "Consumer Heartbeat Time8" 7 "Consumer Heartbeat Time7" 6 "Consumer Heartbeat Time6" 5 "Consumer Heartbeat Time5" 4 "Consumer Heartbeat Time4" 3 "Consumer Heartbeat Time3" 2 "Consumer Heartbeat Time2" 1 "Consumer Heartbeat Time1" 0 "NrOfObjects" ;
VAL_ 1563 SubIndex_1014 0 "COB-ID EMCY" ;
VAL_ 1563 SubIndex_1011 1 "Restore all Default Parameters" 0 "Highest sub-index supported" ;
VAL_ 1563 SubIndex_1010 1 "Save all Parameters" 0 "Highest sub-index supported" ;
VAL_ 1563 SubIndex_100D 0 "Life Time Factor" ;
VAL_ 1563 SubIndex_100C 0 "Guard Time" ;
VAL_ 1563 SubIndex_1007 0 "Sync_Window Length" ;
VAL_ 1563 SubIndex_1006 0 "Communication Cycle Period" ;
VAL_ 1563 SubIndex_1005 0 "COB-ID SYNC" ;
VAL_ 1563 SubIndex_1003 9 "Standard error field" 8 "Standard error field" 7 "Standard error field" 6 "Standard error field" 5 "Standard error field" 4 "Standard error field" 3 "Standard error field" 2 "Standard error field" 1 "Standard error field" 0 "Number of Errors" ;
VAL_ 1563 SubIndex_1001 0 "Error Register" ;
VAL_ 1563 SubIndex_1000 0 "Device Type" ;
VAL_ 1563 Index 25602 "Pressure 32-Bit" 5119 "Safety_configuration_checksum" 5118 "Configuration_valid" 4993 "Safety_SRDO1_mapping_parameter" 4865 "Safety_SRDO1_communication_parameter" 4120 "Identity Object" 4119 "Producer Heartbeat Time" 4118 "Consumer Heartbeat Time" 4116 "COB-ID EMCY" 4113 "Restore Default Parameters" 4112 "Store Parameter Field" 4109 "Life Time Factor" 4108 "Guard Time" 4103 "Sync_Window Length" 4102 "Communication Cycle Period" 4101 "COB-ID SYNC" 4099 "Pre-defined Error Field" 4097 "Error Register" 4096 "Device Type" ;
VAL_ 1563 TransferType 1 "Expedited transfer" 0 "Normal transfer" ;
VAL_ 1563 SizeIndicator 1 "Size is indicated" 0 "Size is not indicated" ;
VAL_ 1563 CCS 2 "Upload" 1 "Download" ;
VAL_ 155 ErrorCode 13088 "(DS-401) Output voltage too low" 13072 "(DS-401) Output voltage too high" 12832 "(DS-401) Internal voltage too low" 12816 "(DS-401) Internal voltage too high" 12576 "(DS-401) Input voltage too low" 12560 "(DS-401) Input voltage too high" 9008 "(DS-401) Load dump at outputs" 8992 "(DS-401) Short circuit at outputs" 8976 "(DS-401) Current at outputs too high (overload)" 128 "(DS-401) Warning: Analogue inputs disabled" 33360 "RPDO timeout" 33344 "Unexpected SYNC data length" 33328 "DAM MPDO not processed, destination object not available" 33312 "PDO length exceeded" 33296 "PDO not processed due to length error" 33104 "Transmit COB-ID collision" 33088 "Recovered from bus off state" 33072 "Life guard error or heartbeat error" 33056 "CAN in error passive mode" 33040 "CAN overrun (objects lost)" ;
VAL_ 1815 State 127 "PreOperational" 5 "Operational" 4 "Stopped" 0 "Bootup" ;
VAL_ 1431 SubIndex_6402 2 "Pressure_1_inverted" 1 "Pressure_1" 0 "Highest sub-index supported" ;
VAL_ 1431 SubIndex_13FF 1 "Safety_Checksum" 0 "Safety_checksum_Number_of_entries" ;
VAL_ 1431 SubIndex_13FE 0 "Configuration_valid" ;
VAL_ 1431 SubIndex_1381 2 "SRDO1_mapping_inv_Byte1" 1 "SRDO1_mapping_Byte1" 0 "SRDO1_Number_of_mapped_objects" ;
VAL_ 1431 SubIndex_1301 6 "SRDO1_communication_par_COB_ID_2" 5 "SRDO1_communication_par_COB_ID_1" 4 "SRDO1_communication_par_Transmission_type" 2 "SRDO1_communication_par_refresh_time" 1 "SRDO1_communication_par_Information_direction" 0 "Highest sub-index supported" ;
VAL_ 1431 SubIndex_1018 4 "Serial number" 3 "Revision number" 2 "Product Code" 1 "Vendor Id" 0 "Highest sub-index supported" ;
VAL_ 1431 SubIndex_1017 0 "Producer Heartbeat Time" ;
VAL_ 1431 SubIndex_1016 16 "Consumer Heartbeat Time16" 15 "Consumer Heartbeat Time15" 14 "Consumer Heartbeat Time14" 13 "Consumer Heartbeat Time13" 12 "Consumer Heartbeat Time12" 11 "Consumer Heartbeat Time11" 10 "Consumer Heartbeat Time10" 9 "Consumer Heartbeat Time9" 8 "Consumer Heartbeat Time8" 7 "Consumer Heartbeat Time7" 6 "Consumer Heartbeat Time6" 5 "Consumer Heartbeat Time5" 4 "Consumer Heartbeat Time4" 3 "Consumer Heartbeat Time3" 2 "Consumer Heartbeat Time2" 1 "Consumer Heartbeat Time1" 0 "NrOfObjects" ;
VAL_ 1431 SubIndex_1014 0 "COB-ID EMCY" ;
VAL_ 1431 SubIndex_1011 1 "Restore all Default Parameters" 0 "Highest sub-index supported" ;
VAL_ 1431 SubIndex_1010 1 "Save all Parameters" 0 "Highest sub-index supported" ;
VAL_ 1431 SubIndex_100D 0 "Life Time Factor" ;
VAL_ 1431 SubIndex_100C 0 "Guard Time" ;
VAL_ 1431 SubIndex_1007 0 "Sync_Window Length" ;
VAL_ 1431 SubIndex_1006 0 "Communication Cycle Period" ;
VAL_ 1431 SubIndex_1005 0 "COB-ID SYNC" ;
VAL_ 1431 SubIndex_1003 9 "Standard error field" 8 "Standard error field" 7 "Standard error field" 6 "Standard error field" 5 "Standard error field" 4 "Standard error field" 3 "Standard error field" 2 "Standard error field" 1 "Standard error field" 0 "Number of Errors" ;
VAL_ 1431 SubIndex_1001 0 "Error Register" ;
VAL_ 1431 SubIndex_1000 0 "Device Type" ;
VAL_ 1431 Index 25602 "Pressure 32-Bit" 5119 "Safety_configuration_checksum" 5118 "Configuration_valid" 4993 "Safety_SRDO1_mapping_parameter" 4865 "Safety_SRDO1_communication_parameter" 4120 "Identity Object" 4119 "Producer Heartbeat Time" 4118 "Consumer Heartbeat Time" 4116 "COB-ID EMCY" 4113 "Restore Default Parameters" 4112 "Store Parameter Field" 4109 "Life Time Factor" 4108 "Guard Time" 4103 "Sync_Window Length" 4102 "Communication Cycle Period" 4101 "COB-ID SYNC" 4099 "Pre-defined Error Field" 4097 "Error Register" 4096 "Device Type" ;
VAL_ 1431 TransferType 1 "Expedited transfer" 0 "Normal transfer" ;
VAL_ 1431 SizeIndicator 1 "Size is indicated" 0 "Size is not indicated" ;
VAL_ 1431 SCS 2 "Upload" 1 "Download" ;
VAL_ 1559 SubIndex_6402 2 "Pressure_1_inverted" 1 "Pressure_1" 0 "Highest sub-index supported" ;
VAL_ 1559 SubIndex_13FF 1 "Safety_Checksum" 0 "Safety_checksum_Number_of_entries" ;
VAL_ 1559 SubIndex_13FE 0 "Configuration_valid" ;
VAL_ 1559 SubIndex_1381 2 "SRDO1_mapping_inv_Byte1" 1 "SRDO1_mapping_Byte1" 0 "SRDO1_Number_of_mapped_objects" ;
VAL_ 1559 SubIndex_1301 6 "SRDO1_communication_par_COB_ID_2" 5 "SRDO1_communication_par_COB_ID_1" 4 "SRDO1_communication_par_Transmission_type" 2 "SRDO1_communication_par_refresh_time" 1 "SRDO1_communication_par_Information_direction" 0 "Highest sub-index supported" ;
VAL_ 1559 SubIndex_1018 4 "Serial number" 3 "Revision number" 2 "Product Code" 1 "Vendor Id" 0 "Highest sub-index supported" ;
VAL_ 1559 SubIndex_1017 0 "Producer Heartbeat Time" ;
VAL_ 1559 SubIndex_1016 16 "Consumer Heartbeat Time16" 15 "Consumer Heartbeat Time15" 14 "Consumer Heartbeat Time14" 13 "Consumer Heartbeat Time13" 12 "Consumer Heartbeat Time12" 11 "Consumer Heartbeat Time11" 10 "Consumer Heartbeat Time10" 9 "Consumer Heartbeat Time9" 8 "Consumer Heartbeat Time8" 7 "Consumer Heartbeat Time7" 6 "Consumer Heartbeat Time6" 5 "Consumer Heartbeat Time5" 4 "Consumer Heartbeat Time4" 3 "Consumer Heartbeat Time3" 2 "Consumer Heartbeat Time2" 1 "Consumer Heartbeat Time1" 0 "NrOfObjects" ;
VAL_ 1559 SubIndex_1014 0 "COB-ID EMCY" ;
VAL_ 1559 SubIndex_1011 1 "Restore all Default Parameters" 0 "Highest sub-index supported" ;
VAL_ 1559 SubIndex_1010 1 "Save all Parameters" 0 "Highest sub-index supported" ;
VAL_ 1559 SubIndex_100D 0 "Life Time Factor" ;
VAL_ 1559 SubIndex_100C 0 "Guard Time" ;
VAL_ 1559 SubIndex_1007 0 "Sync_Window Length" ;
VAL_ 1559 SubIndex_1006 0 "Communication Cycle Period" ;
VAL_ 1559 SubIndex_1005 0 "COB-ID SYNC" ;
VAL_ 1559 SubIndex_1003 9 "Standard error field" 8 "Standard error field" 7 "Standard error field" 6 "Standard error field" 5 "Standard error field" 4 "Standard error field" 3 "Standard error field" 2 "Standard error field" 1 "Standard error field" 0 "Number of Errors" ;
VAL_ 1559 SubIndex_1001 0 "Error Register" ;
VAL_ 1559 SubIndex_1000 0 "Device Type" ;
VAL_ 1559 Index 25602 "Pressure 32-Bit" 5119 "Safety_configuration_checksum" 5118 "Configuration_valid" 4993 "Safety_SRDO1_mapping_parameter" 4865 "Safety_SRDO1_communication_parameter" 4120 "Identity Object" 4119 "Producer Heartbeat Time" 4118 "Consumer Heartbeat Time" 4116 "COB-ID EMCY" 4113 "Restore Default Parameters" 4112 "Store Parameter Field" 4109 "Life Time Factor" 4108 "Guard Time" 4103 "Sync_Window Length" 4102 "Communication Cycle Period" 4101 "COB-ID SYNC" 4099 "Pre-defined Error Field" 4097 "Error Register" 4096 "Device Type" ;
VAL_ 1559 TransferType 1 "Expedited transfer" 0 "Normal transfer" ;
VAL_ 1559 SizeIndicator 1 "Size is indicated" 0 "Size is not indicated" ;
VAL_ 1559 CCS 2 "Upload" 1 "Download" ;
VAL_ 151 ErrorCode 13088 "(DS-401) Output voltage too low" 13072 "(DS-401) Output voltage too high" 12832 "(DS-401) Internal voltage too low" 12816 "(DS-401) Internal voltage too high" 12576 "(DS-401) Input voltage too low" 12560 "(DS-401) Input voltage too high" 9008 "(DS-401) Load dump at outputs" 8992 "(DS-401) Short circuit at outputs" 8976 "(DS-401) Current at outputs too high (overload)" 128 "(DS-401) Warning: Analogue inputs disabled" 33360 "RPDO timeout" 33344 "Unexpected SYNC data length" 33328 "DAM MPDO not processed, destination object not available" 33312 "PDO length exceeded" 33296 "PDO not processed due to length error" 33104 "Transmit COB-ID collision" 33088 "Recovered from bus off state" 33072 "Life guard error or heartbeat error" 33056 "CAN in error passive mode" 33040 "CAN overrun (objects lost)" ;
VAL_ 1802 State 127 "PreOperational" 5 "Operational" 4 "Stopped" 0 "Bootup" ;
VAL_ 1418 SubIndex_A643 3 "UInt32_2" 2 "UInt32_2" 1 "UInt32_1" 0 "NrOfObjects" ;
VAL_ 1418 SubIndex_A642 3 "Int16_2" 2 "Int16_2" 1 "Int16_1" 0 "NrOfObjects" ;
VAL_ 1418 SubIndex_A641 3 "Pressure_1_Sensor3_Inverted" 2 "Pressure_1_Sensor2_Inverted" 1 "Pressure_1_Sensor1_Inverted" 0 "NrOfObjects" ;
VAL_ 1418 SubIndex_A640 3 "Pressure_1_Sensor3" 2 "Pressure_1_Sensor2" 1 "Pressure_1_Sensor1" 0 "NrOfObjects" ;
VAL_ 1418 SubIndex_1F89 0 "BootTime" ;
VAL_ 1418 SubIndex_1F88 127 "SerialNumber127" 126 "SerialNumber126" 125 "SerialNumber125" 124 "SerialNumber124" 123 "SerialNumber123" 122 "SerialNumber122" 121 "SerialNumber121" 120 "SerialNumber120" 119 "SerialNumber119" 118 "SerialNumber118" 117 "SerialNumber117" 116 "SerialNumber116" 115 "SerialNumber115" 114 "SerialNumber114" 113 "SerialNumber113" 112 "SerialNumber112" 111 "SerialNumber111" 110 "SerialNumber110" 109 "SerialNumber109" 108 "SerialNumber108" 107 "SerialNumber107" 106 "SerialNumber106" 105 "SerialNumber105" 104 "SerialNumber104" 103 "SerialNumber103" 102 "SerialNumber102" 101 "SerialNumber101" 100 "SerialNumber100" 99 "SerialNumber99" 98 "SerialNumber98" 97 "SerialNumber97" 96 "SerialNumber96" 95 "SerialNumber95" 94 "SerialNumber94" 93 "SerialNumber93" 92 "SerialNumber92" 91 "SerialNumber91" 90 "SerialNumber90" 89 "SerialNumber89" 88 "SerialNumber88" 87 "SerialNumber87" 86 "SerialNumber86" 85 "SerialNumber85" 84 "SerialNumber84" 83 "SerialNumber83" 82 "SerialNumber82" 81 "SerialNumber81" 80 "SerialNumber80" 79 "SerialNumber79" 78 "SerialNumber78" 77 "SerialNumber77" 76 "SerialNumber76" 75 "SerialNumber75" 74 "SerialNumber74" 73 "SerialNumber73" 72 "SerialNumber72" 71 "SerialNumber71" 70 "SerialNumber70" 69 "SerialNumber69" 68 "SerialNumber68" 67 "SerialNumber67" 66 "SerialNumber66" 65 "SerialNumber65" 64 "SerialNumber64" 63 "SerialNumber63" 62 "SerialNumber62" 61 "SerialNumber61" 60 "SerialNumber60" 59 "SerialNumber59" 58 "SerialNumber58" 57 "SerialNumber57" 56 "SerialNumber56" 55 "SerialNumber55" 54 "SerialNumber54" 53 "SerialNumber53" 52 "SerialNumber52" 51 "SerialNumber51" 50 "SerialNumber50" 49 "SerialNumber49" 48 "SerialNumber48" 47 "SerialNumber47" 46 "SerialNumber46" 45 "SerialNumber45" 44 "SerialNumber44" 43 "SerialNumber43" 42 "SerialNumber42" 41 "SerialNumber41" 40 "SerialNumber40" 39 "SerialNumber39" 38 "SerialNumber38" 37 "SerialNumber37" 36 "SerialNumber36" 35 "SerialNumber35" 34 "SerialNumber34" 33 "SerialNumber33" 32 "SerialNumber32" 31 "SerialNumber31" 30 "SerialNumber30" 29 "SerialNumber29" 28 "SerialNumber28" 27 "SerialNumber27" 26 "SerialNumber26" 25 "SerialNumber25" 24 "SerialNumber24" 23 "SerialNumber23" 22 "SerialNumber22" 21 "SerialNumber21" 20 "SerialNumber20" 19 "SerialNumber19" 18 "SerialNumber18" 17 "SerialNumber17" 16 "SerialNumber16" 15 "SerialNumber15" 14 "SerialNumber14" 13 "SerialNumber13" 12 "SerialNumber12" 11 "SerialNumber11" 10 "SerialNumber10" 9 "SerialNumber9" 8 "SerialNumber8" 7 "SerialNumber7" 6 "SerialNumber6" 5 "SerialNumber5" 4 "SerialNumber4" 3 "SerialNumber3" 2 "SerialNumber2" 1 "SerialNumber1" 0 "NrOfObjects" ;

SG_MUL_VAL_ 1436 Pressure_1_inverted_6402_02 SubIndex_6402 2-2;
SG_MUL_VAL_ 1436 Pressure_1_6402_01 SubIndex_6402 1-1;
SG_MUL_VAL_ 1436 Highest_sub_index_supported_6402 SubIndex_6402 0-0;
SG_MUL_VAL_ 1436 SubIndex_6402 Index 25602-25602;
SG_MUL_VAL_ 1436 Safety_Checksum_13FF_01 SubIndex_13FF 1-1;
SG_MUL_VAL_ 1436 Safety_checksum_Number_of_entrie SubIndex_13FF 0-0;
SG_MUL_VAL_ 1436 SubIndex_13FF Index 5119-5119;
SG_MUL_VAL_ 1436 Configuration_valid_13FE SubIndex_13FE 0-0;
SG_MUL_VAL_ 1436 SubIndex_13FE Index 5118-5118;
SG_MUL_VAL_ 1436 SRDO1_mapping_inv_Byte1_1381_02 SubIndex_1381 2-2;
SG_MUL_VAL_ 1436 SRDO1_mapping_Byte1_1381_01 SubIndex_1381 1-1;
SG_MUL_VAL_ 1436 SRDO1_Number_of_mapped_objects_1 SubIndex_1381 0-0;
SG_MUL_VAL_ 1436 SubIndex_1381 Index 4993-4993;
SG_MUL_VAL_ 1436 SRDO1_communication_par_COB_ID_2 SubIndex_1301 6-6;
SG_MUL_VAL_ 1436 SRDO1_communication_par_COB_ID_1 SubIndex_1301 5-5;
SG_MUL_VAL_ 1436 SRDO1_communication_par_Transmis SubIndex_1301 4-4;
SG_MUL_VAL_ 1436 SRDO1_communication_par_refresh_ SubIndex_1301 2-2;
SG_MUL_VAL_ 1436 SRDO1_communication_par_Informat SubIndex_1301 1-1;
SG_MUL_VAL_ 1436 Highest_sub_index_supported_1301 SubIndex_1301 0-0;
SG_MUL_VAL_ 1436 SubIndex_1301 Index 4865-4865;
SG_MUL_VAL_ 1436 Serial_number_1018_04 SubIndex_1018 4-4;
SG_MUL_VAL_ 1436 Revision_number_1018_03 SubIndex_1018 3-3;
SG_MUL_VAL_ 1436 Product_Code_1018_02 SubIndex_1018 2-2;
SG_MUL_VAL_ 1436 Vendor_Id_1018_01 SubIndex_1018 1-1;
SG_MUL_VAL_ 1436 Highest_sub_index_supported_1018 SubIndex_1018 0-0;
SG_MUL_VAL_ 1436 SubIndex_1018 Index 4120-4120;
SG_MUL_VAL_ 1436 Producer_Heartbeat_Time_1017 SubIndex_1017 0-0;
SG_MUL_VAL_ 1436 SubIndex_1017 Index 4119-4119;
SG_MUL_VAL_ 1436 Consumer_Heartbeat_Time16_1016_1 SubIndex_1016 16-16;
SG_MUL_VAL_ 1436 Consumer_Heartbeat_Time15_1016_0 SubIndex_1016 15-15;
SG_MUL_VAL_ 1436 Consumer_Heartbeat_Time14_1016_0 SubIndex_1016 14-14;
SG_MUL_VAL_ 1436 Consumer_Heartbeat_Time13_1016_0 SubIndex_1016 13-13;
SG_MUL_VAL_ 1436 Consumer_Heartbeat_Time12_1016_0 SubIndex_1016 12-12;
SG_MUL_VAL_ 1436 Consumer_Heartbeat_Time11_1016_0 SubIndex_1016 11-11;
SG_MUL_VAL_ 1436 Consumer_Heartbeat_Time10_1016_0 SubIndex_1016 10-10;
SG_MUL_VAL_ 1436 Consumer_Heartbeat_Time9_1016_09 SubIndex_1016 9-9;
SG_MUL_VAL_ 1436 Consumer_Heartbeat_Time8_1016_08 SubIndex_1016 8-8;
SG_MUL_VAL_ 1436 Consumer_Heartbeat_Time7_1016_07 SubIndex_1016 7-7;
SG_MUL_VAL_ 1436 Consumer_Heartbeat_Time6_1016_06 SubIndex_1016 6-6;
SG_MUL_VAL_ 1436 Consumer_Heartbeat_Time5_1016_05 SubIndex_1016 5-5;
SG_MUL_VAL_ 1436 Consumer_Heartbeat_Time4_1016_04 SubIndex_1016 4-4;
SG_MUL_VAL_ 1436 Consumer_Heartbeat_Time3_1016_03 SubIndex_1016 3-3;
SG_MUL_VAL_ 1436 Consumer_Heartbeat_Time2_1016_02 SubIndex_1016 2-2;
SG_MUL_VAL_ 1436 Consumer_Heartbeat_Time1_1016_01 SubIndex_1016 1-1;
SG_MUL_VAL_ 1436 NrOfObjects_1016_00 SubIndex_1016 0-0;
SG_MUL_VAL_ 1436 SubIndex_1016 Index 4118-4118;
SG_MUL_VAL_ 1436 COB_ID_EMCY_1014 SubIndex_1014 0-0;
SG_MUL_VAL_ 1436 SubIndex_1014 Index 4116-4116;
SG_MUL_VAL_ 1436 Restore_all_Default_Parameters_1 SubIndex_1011 1-1;
SG_MUL_VAL_ 1436 Highest_sub_index_supported_1011 SubIndex_1011 0-0;
SG_MUL_VAL_ 1436 SubIndex_1011 Index 4113-4113;
SG_MUL_VAL_ 1436 Save_all_Parameters_1010_01 SubIndex_1010 1-1;
SG_MUL_VAL_ 1436 Highest_sub_index_supported_1010 SubIndex_1010 0-0;
SG_MUL_VAL_ 1436 SubIndex_1010 Index 4112-4112;
SG_MUL_VAL_ 1436 Life_Time_Factor_100D SubIndex_100D 0-0;
SG_MUL_VAL_ 1436 SubIndex_100D Index 4109-4109;
SG_MUL_VAL_ 1436 Guard_Time_100C SubIndex_100C 0-0;
SG_MUL_VAL_ 1436 SubIndex_100C Index 4108-4108;
SG_MUL_VAL_ 1436 Sync_Window_Length_1007 SubIndex_1007 0-0;
SG_MUL_VAL_ 1436 SubIndex_1007 Index 4103-4103;
SG_MUL_VAL_ 1436 Communication_Cycle_Period_1006 SubIndex_1006 0-0;
SG_MUL_VAL_ 1436 SubIndex_1006 Index 4102-4102;
SG_MUL_VAL_ 1436 COB_ID_SYNC_1005 SubIndex_1005 0-0;
SG_MUL_VAL_ 1436 SubIndex_1005 Index 4101-4101;
SG_MUL_VAL_ 1436 Standard_error_field_1003_09 SubIndex_1003 9-9;
SG_MUL_VAL_ 1436 Standard_error_field_1003_08 SubIndex_1003 8-8;
SG_MUL_VAL_ 1436 Standard_error_field_1003_07 SubIndex_1003 7-7;
SG_MUL_VAL_ 1436 Standard_error_field_1003_06 SubIndex_1003 6-6;
SG_MUL_VAL_ 1436 Standard_error_field_1003_05 SubIndex_1003 5-5;
SG_MUL_VAL_ 1436 Standard_error_field_1003_04 SubIndex_1003 4-4;
SG_MUL_VAL_ 1436 Standard_error_field_1003_03 SubIndex_1003 3-3;
SG_MUL_VAL_ 1436 Standard_error_field_1003_02 SubIndex_1003 2-2;
SG_MUL_VAL_ 1436 Standard_error_field_1003_01 SubIndex_1003 1-1;
SG_MUL_VAL_ 1436 Number_of_Errors_1003_00 SubIndex_1003 0-0;
SG_MUL_VAL_ 1436 SubIndex_1003 Index 4099-4099;
SG_MUL_VAL_ 1436 Error_Register_1001 SubIndex_1001 0-0;
SG_MUL_VAL_ 1436 SubIndex_1001 Index 4097-4097;
SG_MUL_VAL_ 1436 Device_Type_1000 SubIndex_1000 0-0;
SG_MUL_VAL_ 1436 SubIndex_1000 Index 4096-4096;
SG_MUL_VAL_ 1436 Index TransferType 1-1;
SG_MUL_VAL_ 1436 TransferType SCS 1-2;
SG_MUL_VAL_ 1436 NotUsedBytes SCS 1-2;
SG_MUL_VAL_ 1436 SizeIndicator SCS 1-2;
SG_MUL_VAL_ 1564 Pressure_1_inverted_6402_02 SubIndex_6402 2-2;
SG_MUL_VAL_ 1564 Pressure_1_6402_01 SubIndex_6402 1-1;
SG_MUL_VAL_ 1564 Highest_sub_index_supported_0000 SubIndex_6402 0-0;
SG_MUL_VAL_ 1564 SubIndex_6402 Index 25602-25602;
SG_MUL_VAL_ 1564 Safety_Checksum_13FF_01 SubIndex_13FF 1-1;
SG_MUL_VAL_ 1564 Safety_checksum_Number_of_e_0000 SubIndex_13FF 0-0;
SG_MUL_VAL_ 1564 SubIndex_13FF Index 5119-5119;
SG_MUL_VAL_ 1564 Configuration_valid_13FE SubIndex_13FE 0-0;
SG_MUL_VAL_ 1564 SubIndex_13FE Index 5118-5118;
SG_MUL_VAL_ 1564 SRDO1_mapping_inv_Byte1_1381_02 SubIndex_1381 2-2;
SG_MUL_VAL_ 1564 SRDO1_mapping_Byte1_1381_01 SubIndex_1381 1-1;
SG_MUL_VAL_ 1564 SRDO1_Number_of_mapped_obje_0000 SubIndex_1381 0-0;
SG_MUL_VAL_ 1564 SubIndex_1381 Index 4993-4993;
SG_MUL_VAL_ 1564 SRDO1_communication_par_COB_0000 SubIndex_1301 6-6;
SG_MUL_VAL_ 1564 SRDO1_communication_par_COB_0001 SubIndex_1301 5-5;
SG_MUL_VAL_ 1564 SRDO1_communication_par_Tra_0000 SubIndex_1301 4-4;
SG_MUL_VAL_ 1564 SRDO1_communication_par_ref_0000 SubIndex_1301 2-2;
SG_MUL_VAL_ 1564 SRDO1_communication_par_Inf_0000 SubIndex_1301 1-1;
SG_MUL_VAL_ 1564 Highest_sub_index_supported_0001 SubIndex_1301 0-0;
SG_MUL_VAL_ 1564 SubIndex_1301 Index 4865-4865;
SG_MUL_VAL_ 1564 Serial_number_1018_04 SubIndex_1018 4-4;
SG_MUL_VAL_ 1564 Revision_number_1018_03 SubIndex_1018 3-3;
SG_MUL_VAL_ 1564 Product_Code_1018_02 SubIndex_1018 2-2;
SG_MUL_VAL_ 1564 Vendor_Id_1018_01 SubIndex_1018 1-1;
SG_MUL_VAL_ 1564 Highest_sub_index_supported_0002 SubIndex_1018 0-0;
SG_MUL_VAL_ 1564 SubIndex_1018 Index 4120-4120;
SG_MUL_VAL_ 1564 Producer_Heartbeat_Time_1017 SubIndex_1017 0-0;
SG_MUL_VAL_ 1564 SubIndex_1017 Index 4119-4119;
SG_MUL_VAL_ 1564 Consumer_Heartbeat_Time16_1_0000 SubIndex_1016 16-16;
SG_MUL_VAL_ 1564 Consumer_Heartbeat_Time15_1_0000 SubIndex_1016 15-15;
SG_MUL_VAL_ 1564 Consumer_Heartbeat_Time14_1_0000 SubIndex_1016 14-14;
SG_MUL_VAL_ 1564 Consumer_Heartbeat_Time13_1_0000 SubIndex_1016 13-13;
SG_MUL_VAL_ 1564 Consumer_Heartbeat_Time12_1_0000 SubIndex_1016 12-12;
SG_MUL_VAL_ 1564 Consumer_Heartbeat_Time11_1_0000 SubIndex_1016 11-11;
SG_MUL_VAL_ 1564 Consumer_Heartbeat_Time10_1_0000 SubIndex_1016 10-10;
SG_MUL_VAL_ 1564 Consumer_Heartbeat_Time9_1016_09 SubIndex_1016 9-9;
SG_MUL_VAL_ 1564 Consumer_Heartbeat_Time8_1016_08 SubIndex_1016 8-8;
SG_MUL_VAL_ 1564 Consumer_Heartbeat_Time7_1016_07 SubIndex_1016 7-7;
SG_MUL_VAL_ 1564 Consumer_Heartbeat_Time6_1016_06 SubIndex_1016 6-6;
SG_MUL_VAL_ 1564 Consumer_Heartbeat_Time5_1016_05 SubIndex_1016 5-5;
SG_MUL_VAL_ 1564 Consumer_Heartbeat_Time4_1016_04 SubIndex_1016 4-4;
SG_MUL_VAL_ 1564 Consumer_Heartbeat_Time3_1016_03 SubIndex_1016 3-3;
SG_MUL_VAL_ 1564 Consumer_Heartbeat_Time2_1016_02 SubIndex_1016 2-2;
SG_MUL_VAL_ 1564 Consumer_Heartbeat_Time1_1016_01 SubIndex_1016 1-1;
SG_MUL_VAL_ 1564 NrOfObjects_1016_00 SubIndex_1016 0-0;
SG_MUL_VAL_ 1564 SubIndex_1016 Index 4118-4118;
SG_MUL_VAL_ 1564 COB_ID_EMCY_1014 SubIndex_1014 0-0;
SG_MUL_VAL_ 1564 SubIndex_1014 Index 4116-4116;
SG_MUL_VAL_ 1564 Restore_all_Default_Paramet_0000 SubIndex_1011 1-1;
SG_MUL_VAL_ 1564 Highest_sub_index_supported_0003 SubIndex_1011 0-0;
SG_MUL_VAL_ 1564 SubIndex_1011 Index 4113-4113;
SG_MUL_VAL_ 1564 Save_all_Parameters_1010_01 SubIndex_1010 1-1;
SG_MUL_VAL_ 1564 Highest_sub_index_supported_0004 SubIndex_1010 0-0;
SG_MUL_VAL_ 1564 SubIndex_1010 Index 4112-4112;
SG_MUL_VAL_ 1564 Life_Time_Factor_100D SubIndex_100D 0-0;
SG_MUL_VAL_ 1564 SubIndex_100D Index 4109-4109;
SG_MUL_VAL_ 1564 Guard_Time_100C SubIndex_100C 0-0;
SG_MUL_VAL_ 1564 SubIndex_100C Index 4108-4108;
SG_MUL_VAL_ 1564 Sync_Window_Length_1007 SubIndex_1007 0-0;
SG_MUL_VAL_ 1564 SubIndex_1007 Index 4103-4103;
SG_MUL_VAL_ 1564 Communication_Cycle_Period_1006 SubIndex_1006 0-0;
SG_MUL_VAL_ 1564 SubIndex_1006 Index 4102-4102;
SG_MUL_VAL_ 1564 COB_ID_SYNC_1005 SubIndex_1005 0-0;
SG_MUL_VAL_ 1564 SubIndex_1005 Index 4101-4101;
SG_MUL_VAL_ 1564 Standard_error_field_1003_09 SubIndex_1003 9-9;
SG_MUL_VAL_ 1564 Standard_error_field_1003_08 SubIndex_1003 8-8;
SG_MUL_VAL_ 1564 Standard_error_field_1003_07 SubIndex_1003 7-7;
SG_MUL_VAL_ 1564 Standard_error_field_1003_06 SubIndex_1003 6-6;
SG_MUL_VAL_ 1564 Standard_error_field_1003_05 SubIndex_1003 5-5;
SG_MUL_VAL_ 1564 Standard_error_field_1003_04 SubIndex_1003 4-4;
SG_MUL_VAL_ 1564 Standard_error_field_1003_03 SubIndex_1003 3-3;
SG_MUL_VAL_ 1564 Standard_error_field_1003_02 SubIndex_1003 2-2;
SG_MUL_VAL_ 1564 Standard_error_field_1003_01 SubIndex_1003 1-1;
SG_MUL_VAL_ 1564 Number_of_Errors_1003_00 SubIndex_1003 0-0;
SG_MUL_VAL_ 1564 SubIndex_1003 Index 4099-4099;
SG_MUL_VAL_ 1564 Error_Register_1001 SubIndex_1001 0-0;
SG_MUL_VAL_ 1564 SubIndex_1001 Index 4097-4097;
SG_MUL_VAL_ 1564 Device_Type_1000 SubIndex_1000 0-0;
SG_MUL_VAL_ 1564 SubIndex_1000 Index 4096-4096;
SG_MUL_VAL_ 1564 Index TransferType 1-1;
SG_MUL_VAL_ 1564 TransferType CCS 1-2;
SG_MUL_VAL_ 1564 NotUsedBytes CCS 1-2;
SG_MUL_VAL_ 1564 SizeIndicator CCS 1-2;
SG_MUL_VAL_ 1435 Pressure_1_inverted_6402_02 SubIndex_6402 2-2;
SG_MUL_VAL_ 1435 Pressure_1_6402_01 SubIndex_6402 1-1;
SG_MUL_VAL_ 1435 Highest_sub_index_supported_0005 SubIndex_6402 0-0;
SG_MUL_VAL_ 1435 SubIndex_6402 Index 25602-25602;
SG_MUL_VAL_ 1435 Safety_Checksum_13FF_01 SubIndex_13FF 1-1;
SG_MUL_VAL_ 1435 Safety_checksum_Number_of_e_0001 SubIndex_13FF 0-0;
SG_MUL_VAL_ 1435 SubIndex_13FF Index 5119-5119;
SG_MUL_VAL_ 1435 Configuration_valid_13FE SubIndex_13FE 0-0;
SG_MUL_VAL_ 1435 SubIndex_13FE Index 5118-5118;
SG_MUL_VAL_ 1435 SRDO1_mapping_inv_Byte1_1381_02 SubIndex_1381 2-2;
SG_MUL_VAL_ 1435 SRDO1_mapping_Byte1_1381_01 SubIndex_1381 1-1;
SG_MUL_VAL_ 1435 SRDO1_Number_of_mapped_obje_0001 SubIndex_1381 0-0;
SG_MUL_VAL_ 1435 SubIndex_1381 Index 4993-4993;
SG_MUL_VAL_ 1435 SRDO1_communication_par_COB_0002 SubIndex_1301 6-6;
SG_MUL_VAL_ 1435 SRDO1_communication_par_COB_0003 SubIndex_1301 5-5;
SG_MUL_VAL_ 1435 SRDO1_communication_par_Tra_0001 SubIndex_1301 4-4;
SG_MUL_VAL_ 1435 SRDO1_communication_par_ref_0001 SubIndex_1301 2-2;
SG_MUL_VAL_ 1435 SRDO1_communication_par_Inf_0001 SubIndex_1301 1-1;
SG_MUL_VAL_ 1435 Highest_sub_index_supported_0006 SubIndex_1301 0-0;
SG_MUL_VAL_ 1435 SubIndex_1301 Index 4865-4865;
SG_MUL_VAL_ 1435 Serial_number_1018_04 SubIndex_1018 4-4;
SG_MUL_VAL_ 1435 Revision_number_1018_03 SubIndex_1018 3-3;
SG_MUL_VAL_ 1435 Product_Code_1018_02 SubIndex_1018 2-2;
SG_MUL_VAL_ 1435 Vendor_Id_1018_01 SubIndex_1018 1-1;
SG_MUL_VAL_ 1435 Highest_sub_index_supported_0007 SubIndex_1018 0-0;
SG_MUL_VAL_ 1435 SubIndex_1018 Index 4120-4120;
SG_MUL_VAL_ 1435 Producer_Heartbeat_Time_1017 SubIndex_1017 0-0;
SG_MUL_VAL_ 1435 SubIndex_1017 Index 4119-4119;
SG_MUL_VAL_ 1435 Consumer_Heartbeat_Time16_1_0001 SubIndex_1016 16-16;
SG_MUL_VAL_ 1435 Consumer_Heartbeat_Time15_1_0001 SubIndex_1016 15-15;
SG_MUL_VAL_ 1435 Consumer_Heartbeat_Time14_1_0001 SubIndex_1016 14-14;
SG_MUL_VAL_ 1435 Consumer_Heartbeat_Time13_1_0001 SubIndex_1016 13-13;
SG_MUL_VAL_ 1435 Consumer_Heartbeat_Time12_1_0001 SubIndex_1016 12-12;
SG_MUL_VAL_ 1435 Consumer_Heartbeat_Time11_1_0001 SubIndex_1016 11-11;
SG_MUL_VAL_ 1435 Consumer_Heartbeat_Time10_1_0001 SubIndex_1016 10-10;
SG_MUL_VAL_ 1435 Consumer_Heartbeat_Time9_1016_09 SubIndex_1016 9-9;
SG_MUL_VAL_ 1435 Consumer_Heartbeat_Time8_1016_08 SubIndex_1016 8-8;
SG_MUL_VAL_ 1435 Consumer_Heartbeat_Time7_1016_07 SubIndex_1016 7-7;
SG_MUL_VAL_ 1435 Consumer_Heartbeat_Time6_1016_06 SubIndex_1016 6-6;
SG_MUL_VAL_ 1435 Consumer_Heartbeat_Time5_1016_05 SubIndex_1016 5-5;
SG_MUL_VAL_ 1435 Consumer_Heartbeat_Time4_1016_04 SubIndex_1016 4-4;
SG_MUL_VAL_ 1435 Consumer_Heartbeat_Time3_1016_03 SubIndex_1016 3-3;
SG_MUL_VAL_ 1435 Consumer_Heartbeat_Time2_1016_02 SubIndex_1016 2-2;
SG_MUL_VAL_ 1435 Consumer_Heartbeat_Time1_1016_01 SubIndex_1016 1-1;
SG_MUL_VAL_ 1435 NrOfObjects_1016_00 SubIndex_1016 0-0;
SG_MUL_VAL_ 1435 SubIndex_1016 Index 4118-4118;
SG_MUL_VAL_ 1435 COB_ID_EMCY_1014 SubIndex_1014 0-0;
SG_MUL_VAL_ 1435 SubIndex_1014 Index 4116-4116;
SG_MUL_VAL_ 1435 Restore_all_Default_Paramet_0001 SubIndex_1011 1-1;
SG_MUL_VAL_ 1435 Highest_sub_index_supported_0008 SubIndex_1011 0-0;
SG_MUL_VAL_ 1435 SubIndex_1011 Index 4113-4113;
SG_MUL_VAL_ 1435 Save_all_Parameters_1010_01 SubIndex_1010 1-1;
SG_MUL_VAL_ 1435 Highest_sub_index_supported_0009 SubIndex_1010 0-0;
SG_MUL_VAL_ 1435 SubIndex_1010 Index 4112-4112;
SG_MUL_VAL_ 1435 Life_Time_Factor_100D SubIndex_100D 0-0;
SG_MUL_VAL_ 1435 SubIndex_100D Index 4109-4109;
SG_MUL_VAL_ 1435 Guard_Time_100C SubIndex_100C 0-0;
SG_MUL_VAL_ 1435 SubIndex_100C Index 4108-4108;
SG_MUL_VAL_ 1435 Sync_Window_Length_1007 SubIndex_1007 0-0;
SG_MUL_VAL_ 1435 SubIndex_1007 Index 4103-4103;
SG_MUL_VAL_ 1435 Communication_Cycle_Period_1006 SubIndex_1006 0-0;
SG_MUL_VAL_ 1435 SubIndex_1006 Index 4102-4102;
SG_MUL_VAL_ 1435 COB_ID_SYNC_1005 SubIndex_1005 0-0;
SG_MUL_VAL_ 1435 SubIndex_1005 Index 4101-4101;
SG_MUL_VAL_ 1435 Standard_error_field_1003_09 SubIndex_1003 9-9;
SG_MUL_VAL_ 1435 Standard_error_field_1003_08 SubIndex_1003 8-8;
SG_MUL_VAL_ 1435 Standard_error_field_1003_07 SubIndex_1003 7-7;
SG_MUL_VAL_ 1435 Standard_error_field_1003_06 SubIndex_1003 6-6;
SG_MUL_VAL_ 1435 Standard_error_field_1003_05 SubIndex_1003 5-5;
SG_MUL_VAL_ 1435 Standard_error_field_1003_04 SubIndex_1003 4-4;
SG_MUL_VAL_ 1435 Standard_error_field_1003_03 SubIndex_1003 3-3;
SG_MUL_VAL_ 1435 Standard_error_field_1003_02 SubIndex_1003 2-2;
SG_MUL_VAL_ 1435 Standard_error_field_1003_01 SubIndex_1003 1-1;
SG_MUL_VAL_ 1435 Number_of_Errors_1003_00 SubIndex_1003 0-0;
SG_MUL_VAL_ 1435 SubIndex_1003 Index 4099-4099;
SG_MUL_VAL_ 1435 Error_Register_1001 SubIndex_1001 0-0;
SG_MUL_VAL_ 1435 SubIndex_1001 Index 4097-4097;
SG_MUL_VAL_ 1435 Device_Type_1000 SubIndex_1000 0-0;
SG_MUL_VAL_ 1435 SubIndex_1000 Index 4096-4096;
SG_MUL_VAL_ 1435 Index TransferType 1-1;
SG_MUL_VAL_ 1435 TransferType SCS 1-2;
SG_MUL_VAL_ 1435 NotUsedBytes SCS 1-2;
SG_MUL_VAL_ 1435 SizeIndicator SCS 1-2;
SG_MUL_VAL_ 1563 Pressure_1_inverted_6402_02 SubIndex_6402 2-2;
SG_MUL_VAL_ 1563 Pressure_1_6402_01 SubIndex_6402 1-1;
SG_MUL_VAL_ 1563 Highest_sub_index_supported_0010 SubIndex_6402 0-0;
SG_MUL_VAL_ 1563 SubIndex_6402 Index 25602-25602;
SG_MUL_VAL_ 1563 Safety_Checksum_13FF_01 SubIndex_13FF 1-1;
SG_MUL_VAL_ 1563 Safety_checksum_Number_of_e_0002 SubIndex_13FF 0-0;
SG_MUL_VAL_ 1563 SubIndex_13FF Index 5119-5119;
SG_MUL_VAL_ 1563 Configuration_valid_13FE SubIndex_13FE 0-0;
SG_MUL_VAL_ 1563 SubIndex_13FE Index 5118-5118;
SG_MUL_VAL_ 1563 SRDO1_mapping_inv_Byte1_1381_02 SubIndex_1381 2-2;
SG_MUL_VAL_ 1563 SRDO1_mapping_Byte1_1381_01 SubIndex_1381 1-1;
SG_MUL_VAL_ 1563 SRDO1_Number_of_mapped_obje_0002 SubIndex_1381 0-0;
SG_MUL_VAL_ 1563 SubIndex_1381 Index 4993-4993;
SG_MUL_VAL_ 1563 SRDO1_communication_par_COB_0004 SubIndex_1301 6-6;
SG_MUL_VAL_ 1563 SRDO1_communication_par_COB_0005 SubIndex_1301 5-5;
SG_MUL_VAL_ 1563 SRDO1_communication_par_Tra_0002 SubIndex_1301 4-4;
SG_MUL_VAL_ 1563 SRDO1_communication_par_ref_0002 SubIndex_1301 2-2;
SG_MUL_VAL_ 1563 SRDO1_communication_par_Inf_0002 SubIndex_1301 1-1;
SG_MUL_VAL_ 1563 Highest_sub_index_supported_0011 SubIndex_1301 0-0;
SG_MUL_VAL_ 1563 SubIndex_1301 Index 4865-4865;
SG_MUL_VAL_ 1563 Serial_number_1018_04 SubIndex_1018 4-4;
SG_MUL_VAL_ 1563 Revision_number_1018_03 SubIndex_1018 3-3;
SG_MUL_VAL_ 1563 Product_Code_1018_02 SubIndex_1018 2-2;
SG_MUL_VAL_ 1563 Vendor_Id_1018_01 SubIndex_1018 1-1;
SG_MUL_VAL_ 1563 Highest_sub_index_supported_0012 SubIndex_1018 0-0;
SG_MUL_VAL_ 1563 SubIndex_1018 Index 4120-4120;
SG_MUL_VAL_ 1563 Producer_Heartbeat_Time_1017 SubIndex_1017 0-0;
SG_MUL_VAL_ 1563 SubIndex_1017 Index 4119-4119;
SG_MUL_VAL_ 1563 Consumer_Heartbeat_Time16_1_0002 SubIndex_1016 16-16;
SG_MUL_VAL_ 1563 Consumer_Heartbeat_Time15_1_0002 SubIndex_1016 15-15;
SG_MUL_VAL_ 1563 Consumer_Heartbeat_Time14_1_0002 SubIndex_1016 14-14;
SG_MUL_VAL_ 1563 Consumer_Heartbeat_Time13_1_0002 SubIndex_1016 13-13;
SG_MUL_VAL_ 1563 Consumer_Heartbeat_Time12_1_0002 SubIndex_1016 12-12;
SG_MUL_VAL_ 1563 Consumer_Heartbeat_Time11_1_0002 SubIndex_1016 11-11;
SG_MUL_VAL_ 1563 Consumer_Heartbeat_Time10_1_0002 SubIndex_1016 10-10;
SG_MUL_VAL_ 1563 Consumer_Heartbeat_Time9_1016_09 SubIndex_1016 9-9;
SG_MUL_VAL_ 1563 Consumer_Heartbeat_Time8_1016_08 SubIndex_1016 8-8;
SG_MUL_VAL_ 1563 Consumer_Heartbeat_Time7_1016_07 SubIndex_1016 7-7;
SG_MUL_VAL_ 1563 Consumer_Heartbeat_Time6_1016_06 SubIndex_1016 6-6;
SG_MUL_VAL_ 1563 Consumer_Heartbeat_Time5_1016_05 SubIndex_1016 5-5;
SG_MUL_VAL_ 1563 Consumer_Heartbeat_Time4_1016_04 SubIndex_1016 4-4;
SG_MUL_VAL_ 1563 Consumer_Heartbeat_Time3_1016_03 SubIndex_1016 3-3;
SG_MUL_VAL_ 1563 Consumer_Heartbeat_Time2_1016_02 SubIndex_1016 2-2;
SG_MUL_VAL_ 1563 Consumer_Heartbeat_Time1_1016_01 SubIndex_1016 1-1;
SG_MUL_VAL_ 1563 NrOfObjects_1016_00 SubIndex_1016 0-0;
SG_MUL_VAL_ 1563 SubIndex_1016 Index 4118-4118;
SG_MUL_VAL_ 1563 COB_ID_EMCY_1014 SubIndex_1014 0-0;
SG_MUL_VAL_ 1563 SubIndex_1014 Index 4116-4116;
SG_MUL_VAL_ 1563 Restore_all_Default_Paramet_0002 SubIndex_1011 1-1;
SG_MUL_VAL_ 1563 Highest_sub_index_supported_0013 SubIndex_1011 0-0;
SG_MUL_VAL_ 1563 SubIndex_1011 Index 4113-4113;
SG_MUL_VAL_ 1563 Save_all_Parameters_1010_01 SubIndex_1010 1-1;
SG_MUL_VAL_ 1563 Highest_sub_index_supported_0014 SubIndex_1010 0-0;
SG_MUL_VAL_ 1563 SubIndex_1010 Index 4112-4112;
SG_MUL_VAL_ 1563 Life_Time_Factor_100D SubIndex_100D 0-0;
SG_MUL_VAL_ 1563 SubIndex_100D Index 4109-4109;
SG_MUL_VAL_ 1563 Guard_Time_100C SubIndex_100C 0-0;
SG_MUL_VAL_ 1563 SubIndex_100C Index 4108-4108;
SG_MUL_VAL_ 1563 Sync_Window_Length_1007 SubIndex_1007 0-0;
SG_MUL_VAL_ 1563 SubIndex_1007 Index 4103-4103;
SG_MUL_VAL_ 1563 Communication_Cycle_Period_1006 SubIndex_1006 0-0;
SG_MUL_VAL_ 1563 SubIndex_1006 Index 4102-4102;
SG_MUL_VAL_ 1563 COB_ID_SYNC_1005 SubIndex_1005 0-0;
SG_MUL_VAL_ 1563 SubIndex_1005 Index 4101-4101;
SG_MUL_VAL_ 1563 Standard_error_field_1003_09 SubIndex_1003 9-9;
SG_MUL_VAL_ 1563 Standard_error_field_1003_08 SubIndex_1003 8-8;
SG_MUL_VAL_ 1563 Standard_error_field_1003_07 SubIndex_1003 7-7;
SG_MUL_VAL_ 1563 Standard_error_field_1003_06 SubIndex_1003 6-6;
SG_MUL_VAL_ 1563 Standard_error_field_1003_05 SubIndex_1003 5-5;
SG_MUL_VAL_ 1563 Standard_error_field_1003_04 SubIndex_1003 4-4;
SG_MUL_VAL_ 1563 Standard_error_field_1003_03 SubIndex_1003 3-3;
SG_MUL_VAL_ 1563 Standard_error_field_1003_02 SubIndex_1003 2-2;
SG_MUL_VAL_ 1563 Standard_error_field_1003_01 SubIndex_1003 1-1;
SG_MUL_VAL_ 1563 Number_of_Errors_1003_00 SubIndex_1003 0-0;
SG_MUL_VAL_ 1563 SubIndex_1003 Index 4099-4099;
SG_MUL_VAL_ 1563 Error_Register_1001 SubIndex_1001 0-0;
SG_MUL_VAL_ 1563 SubIndex_1001 Index 4097-4097;
SG_MUL_VAL_ 1563 Device_Type_1000 SubIndex_1000 0-0;
SG_MUL_VAL_ 1563 SubIndex_1000 Index 4096-4096;
SG_MUL_VAL_ 1563 Index TransferType 1-1;
SG_MUL_VAL_ 1563 TransferType CCS 1-2;
SG_MUL_VAL_ 1563 NotUsedBytes CCS 1-2;
SG_MUL_VAL_ 1563 SizeIndicator CCS 1-2;
SG_MUL_VAL_ 1431 Pressure_1_inverted_6402_02 SubIndex_6402 2-2;
SG_MUL_VAL_ 1431 Pressure_1_6402_01 SubIndex_6402 1-1;
SG_MUL_VAL_ 1431 Highest_sub_index_supported_0015 SubIndex_6402 0-0;
SG_MUL_VAL_ 1431 SubIndex_6402 Index 25602-25602;
SG_MUL_VAL_ 1431 Safety_Checksum_13FF_01 SubIndex_13FF 1-1;
SG_MUL_VAL_ 1431 Safety_checksum_Number_of_e_0003 SubIndex_13FF 0-0;
SG_MUL_VAL_ 1431 SubIndex_13FF Index 5119-5119;
SG_MUL_VAL_ 1431 Configuration_valid_13FE SubIndex_13FE 0-0;
SG_MUL_VAL_ 1431 SubIndex_13FE Index 5118-5118;
SG_MUL_VAL_ 1431 SRDO1_mapping_inv_Byte1_1381_02 SubIndex_1381 2-2;
SG_MUL_VAL_ 1431 SRDO1_mapping_Byte1_1381_01 SubIndex_1381 1-1;
SG_MUL_VAL_ 1431 SRDO1_Number_of_mapped_obje_0003 SubIndex_1381 0-0;
SG_MUL_VAL_ 1431 SubIndex_1381 Index 4993-4993;
SG_MUL_VAL_ 1431 SRDO1_communication_par_COB_0006 SubIndex_1301 6-6;
SG_MUL_VAL_ 1431 SRDO1_communication_par_COB_0007 SubIndex_1301 5-5;
SG_MUL_VAL_ 1431 SRDO1_communication_par_Tra_0003 SubIndex_1301 4-4;
SG_MUL_VAL_ 1431 SRDO1_communication_par_ref_0003 SubIndex_1301 2-2;
SG_MUL_VAL_ 1431 SRDO1_communication_par_Inf_0003 SubIndex_1301 1-1;
SG_MUL_VAL_ 1431 Highest_sub_index_supported_0016 SubIndex_1301 0-0;
SG_MUL_VAL_ 1431 SubIndex_1301 Index 4865-4865;
SG_MUL_VAL_ 1431 Serial_number_1018_04 SubIndex_1018 4-4;
SG_MUL_VAL_ 1431 Revision_number_1018_03 SubIndex_1018 3-3;
SG_MUL_VAL_ 1431 Product_Code_1018_02 SubIndex_1018 2-2;
SG_MUL_VAL_ 1431 Vendor_Id_1018_01 SubIndex_1018 1-1;
SG_MUL_VAL_ 1431 Highest_sub_index_supported_0017 SubIndex_1018 0-0;
SG_MUL_VAL_ 1431 SubIndex_1018 Index 4120-4120;
SG_MUL_VAL_ 1431 Producer_Heartbeat_Time_1017 SubIndex_1017 0-0;
SG_MUL_VAL_ 1431 SubIndex_1017 Index 4119-4119;
SG_MUL_VAL_ 1431 Consumer_Heartbeat_Time16_1_0003 SubIndex_1016 16-16;
SG_MUL_VAL_ 1431 Consumer_Heartbeat_Time15_1_0003 SubIndex_1016 15-15;
SG_MUL_VAL_ 1431 Consumer_Heartbeat_Time14_1_0003 SubIndex_1016 14-14;
SG_MUL_VAL_ 1431 Consumer_Heartbeat_Time13_1_0003 SubIndex_1016 13-13;
SG_MUL_VAL_ 1431 Consumer_Heartbeat_Time12_1_0003 SubIndex_1016 12-12;
SG_MUL_VAL_ 1431 Consumer_Heartbeat_Time11_1_0003 SubIndex_1016 11-11;
SG_MUL_VAL_ 1431 Consumer_Heartbeat_Time10_1_0003 SubIndex_1016 10-10;
SG_MUL_VAL_ 1431 Consumer_Heartbeat_Time9_1016_09 SubIndex_1016 9-9;
SG_MUL_VAL_ 1431 Consumer_Heartbeat_Time8_1016_08 SubIndex_1016 8-8;
SG_MUL_VAL_ 1431 Consumer_Heartbeat_Time7_1016_07 SubIndex_1016 7-7;
SG_MUL_VAL_ 1431 Consumer_Heartbeat_Time6_1016_06 SubIndex_1016 6-6;
SG_MUL_VAL_ 1431 Consumer_Heartbeat_Time5_1016_05 SubIndex_1016 5-5;
SG_MUL_VAL_ 1431 Consumer_Heartbeat_Time4_1016_04 SubIndex_1016 4-4;
SG_MUL_VAL_ 1431 Consumer_Heartbeat_Time3_1016_03 SubIndex_1016 3-3;
SG_MUL_VAL_ 1431 Consumer_Heartbeat_Time2_1016_02 SubIndex_1016 2-2;
SG_MUL_VAL_ 1431 Consumer_Heartbeat_Time1_1016_01 SubIndex_1016 1-1;
SG_MUL_VAL_ 1431 NrOfObjects_1016_00 SubIndex_1016 0-0;
SG_MUL_VAL_ 1431 SubIndex_1016 Index 4118-4118;
SG_MUL_VAL_ 1431 COB_ID_EMCY_1014 SubIndex_1014 0-0;
SG_MUL_VAL_ 1431 SubIndex_1014 Index 4116-4116;
SG_MUL_VAL_ 1431 Restore_all_Default_Paramet_0003 SubIndex_1011 1-1;
SG_MUL_VAL_ 1431 Highest_sub_index_supported_0018 SubIndex_1011 0-0;
SG_MUL_VAL_ 1431 SubIndex_1011 Index 4113-4113;
SG_MUL_VAL_ 1431 Save_all_Parameters_1010_01 SubIndex_1010 1-1;
SG_MUL_VAL_ 1431 Highest_sub_index_supported_0019 SubIndex_1010 0-0;
SG_MUL_VAL_ 1431 SubIndex_1010 Index 4112-4112;
SG_MUL_VAL_ 1431 Life_Time_Factor_100D SubIndex_100D 0-0;
SG_MUL_VAL_ 1431 SubIndex_100D Index 4109-4109;
SG_MUL_VAL_ 1431 Guard_Time_100C SubIndex_100C 0-0;
SG_MUL_VAL_ 1431 SubIndex_100C Index 4108-4108;
SG_MUL_VAL_ 1431 Sync_Window_Length_1007 SubIndex_1007 0-0;
SG_MUL_VAL_ 1431 SubIndex_1007 Index 4103-4103;
SG_MUL_VAL_ 1431 Communication_Cycle_Period_1006 SubIndex_1006 0-0;
SG_MUL_VAL_ 1431 SubIndex_1006 Index 4102-4102;
SG_MUL_VAL_ 1431 COB_ID_SYNC_1005 SubIndex_1005 0-0;
SG_MUL_VAL_ 1431 SubIndex_1005 Index 4101-4101;
SG_MUL_VAL_ 1431 Standard_error_field_1003_09 SubIndex_1003 9-9;
SG_MUL_VAL_ 1431 Standard_error_field_1003_08 SubIndex_1003 8-8;
SG_MUL_VAL_ 1431 Standard_error_field_1003_07 SubIndex_1003 7-7;
SG_MUL_VAL_ 1431 Standard_error_field_1003_06 SubIndex_1003 6-6;
SG_MUL_VAL_ 1431 Standard_error_field_1003_05 SubIndex_1003 5-5;
SG_MUL_VAL_ 1431 Standard_error_field_1003_04 SubIndex_1003 4-4;
SG_MUL_VAL_ 1431 Standard_error_field_1003_03 SubIndex_1003 3-3;
SG_MUL_VAL_ 1431 Standard_error_field_1003_02 SubIndex_1003 2-2;
SG_MUL_VAL_ 1431 Standard_error_field_1003_01 SubIndex_1003 1-1;
SG_MUL_VAL_ 1431 Number_of_Errors_1003_00 SubIndex_1003 0-0;
SG_MUL_VAL_ 1431 SubIndex_1003 Index 4099-4099;
SG_MUL_VAL_ 1431 Error_Register_1001 SubIndex_1001 0-0;
SG_MUL_VAL_ 1431 SubIndex_1001 Index 4097-4097;
SG_MUL_VAL_ 1431 Device_Type_1000 SubIndex_1000 0-0;
SG_MUL_VAL_ 1431 SubIndex_1000 Index 4096-4096;
SG_MUL_VAL_ 1431 Index TransferType 1-1;
SG_MUL_VAL_ 1431 TransferType SCS 1-2;
SG_MUL_VAL_ 1431 NotUsedBytes SCS 1-2;
SG_MUL_VAL_ 1431 SizeIndicator SCS 1-2;
SG_MUL_VAL_ 1559 Pressure_1_inverted_6402_02 SubIndex_6402 2-2;
SG_MUL_VAL_ 1559 Pressure_1_6402_01 SubIndex_6402 1-1;
SG_MUL_VAL_ 1559 Highest_sub_index_supported_0020 SubIndex_6402 0-0;
SG_MUL_VAL_ 1559 SubIndex_6402 Index 25602-25602;
SG_MUL_VAL_ 1559 Safety_Checksum_13FF_01 SubIndex_13FF 1-1;
SG_MUL_VAL_ 1559 Safety_checksum_Number_of_e_0004 SubIndex_13FF 0-0;
SG_MUL_VAL_ 1559 SubIndex_13FF Index 5119-5119;
SG_MUL_VAL_ 1559 Configuration_valid_13FE SubIndex_13FE 0-0;
SG_MUL_VAL_ 1559 SubIndex_13FE Index 5118-5118;
SG_MUL_VAL_ 1559 SRDO1_mapping_inv_Byte1_1381_02 SubIndex_1381 2-2;
SG_MUL_VAL_ 1559 SRDO1_mapping_Byte1_1381_01 SubIndex_1381 1-1;
SG_MUL_VAL_ 1559 SRDO1_Number_of_mapped_obje_0004 SubIndex_1381 0-0;
SG_MUL_VAL_ 1559 SubIndex_1381 Index 4993-4993;
SG_MUL_VAL_ 1559 SRDO1_communication_par_COB_0008 SubIndex_1301 6-6;
SG_MUL_VAL_ 1559 SRDO1_communication_par_COB_0009 SubIndex_1301 5-5;
SG_MUL_VAL_ 1559 SRDO1_communication_par_Tra_0004 SubIndex_1301 4-4;
SG_MUL_VAL_ 1559 SRDO1_communication_par_ref_0004 SubIndex_1301 2-2;
SG_MUL_VAL_ 1559 SRDO1_communication_par_Inf_0004 SubIndex_1301 1-1;
SG_MUL_VAL_ 1559 Highest_sub_index_supported_0021 SubIndex_1301 0-0;
SG_MUL_VAL_ 1559 SubIndex_1301 Index 4865-4865;
SG_MUL_VAL_ 1559 Serial_number_1018_04 SubIndex_1018 4-4;
SG_MUL_VAL_ 1559 Revision_number_1018_03 SubIndex_1018 3-3;
SG_MUL_VAL_ 1559 Product_Code_1018_02 SubIndex_1018 2-2;
SG_MUL_VAL_ 1559 Vendor_Id_1018_01 SubIndex_1018 1-1;
SG_MUL_VAL_ 1559 Highest_sub_index_supported_0022 SubIndex_1018 0-0;
SG_MUL_VAL_ 1559 SubIndex_1018 Index 4120-4120;
SG_MUL_VAL_ 1559 Producer_Heartbeat_Time_1017 SubIndex_1017 0-0;
SG_MUL_VAL_ 1559 SubIndex_1017 Index 4119-4119;
SG_MUL_VAL_ 1559 Consumer_Heartbeat_Time16_1_0004 SubIndex_1016 16-16;
SG_MUL_VAL_ 1559 Consumer_Heartbeat_Time15_1_0004 SubIndex_1016 15-15;
SG_MUL_VAL_ 1559 Consumer_Heartbeat_Time14_1_0004 SubIndex_1016 14-14;
SG_MUL_VAL_ 1559 Consumer_Heartbeat_Time13_1_0004 SubIndex_1016 13-13;
SG_MUL_VAL_ 1559 Consumer_Heartbeat_Time12_1_0004 SubIndex_1016 12-12;
SG_MUL_VAL_ 1559 Consumer_Heartbeat_Time11_1_0004 SubIndex_1016 11-11;
SG_MUL_VAL_ 1559 Consumer_Heartbeat_Time10_1_0004 SubIndex_1016 10-10;
SG_MUL_VAL_ 1559 Consumer_Heartbeat_Time9_1016_09 SubIndex_1016 9-9;
SG_MUL_VAL_ 1559 Consumer_Heartbeat_Time8_1016_08 SubIndex_1016 8-8;
SG_MUL_VAL_ 1559 Consumer_Heartbeat_Time7_1016_07 SubIndex_1016 7-7;
SG_MUL_VAL_ 1559 Consumer_Heartbeat_Time6_1016_06 SubIndex_1016 6-6;
SG_MUL_VAL_ 1559 Consumer_Heartbeat_Time5_1016_05 SubIndex_1016 5-5;
SG_MUL_VAL_ 1559 Consumer_Heartbeat_Time4_1016_04 SubIndex_1016 4-4;
SG_MUL_VAL_ 1559 Consumer_Heartbeat_Time3_1016_03 SubIndex_1016 3-3;
SG_MUL_VAL_ 1559 Consumer_Heartbeat_Time2_1016_02 SubIndex_1016 2-2;
SG_MUL_VAL_ 1559 Consumer_Heartbeat_Time1_1016_01 SubIndex_1016 1-1;
SG_MUL_VAL_ 1559 NrOfObjects_1016_00 SubIndex_1016 0-0;
SG_MUL_VAL_ 1559 SubIndex_1016 Index 4118-4118;
SG_MUL_VAL_ 1559 COB_ID_EMCY_1014 SubIndex_1014 0-0;
SG_MUL_VAL_ 1559 SubIndex_1014 Index 4116-4116;
SG_MUL_VAL_ 1559 Restore_all_Default_Paramet_0004 SubIndex_1011 1-1;
SG_MUL_VAL_ 1559 Highest_sub_index_supported_0023 SubIndex_1011 0-0;
SG_MUL_VAL_ 1559 SubIndex_1011 Index 4113-4113;
SG_MUL_VAL_ 1559 Save_all_Parameters_1010_01 SubIndex_1010 1-1;
SG_MUL_VAL_ 1559 Highest_sub_index_supported_0024 SubIndex_1010 0-0;
SG_MUL_VAL_ 1559 SubIndex_1010 Index 4112-4112;
SG_MUL_VAL_ 1559 Life_Time_Factor_100D SubIndex_100D 0-0;
SG_MUL_VAL_ 1559 SubIndex_100D Index 4109-4109;
SG_MUL_VAL_ 1559 Guard_Time_100C SubIndex_100C 0-0;
SG_MUL_VAL_ 1559 SubIndex_100C Index 4108-4108;
SG_MUL_VAL_ 1559 Sync_Window_Length_1007 SubIndex_1007 0-0;
SG_MUL_VAL_ 1559 SubIndex_1007 Index 4103-4103;
SG_MUL_VAL_ 1559 Communication_Cycle_Period_1006 SubIndex_1006 0-0;
SG_MUL_VAL_ 1559 SubIndex_1006 Index 4102-4102;
SG_MUL_VAL_ 1559 COB_ID_SYNC_1005 SubIndex_1005 0-0;
SG_MUL_VAL_ 1559 SubIndex_1005 Index 4101-4101;
SG_MUL_VAL_ 1559 Standard_error_field_1003_09 SubIndex_1003 9-9;
SG_MUL_VAL_ 1559 Standard_error_field_1003_08 SubIndex_1003 8-8;
SG_MUL_VAL_ 1559 Standard_error_field_1003_07 SubIndex_1003 7-7;
SG_MUL_VAL_ 1559 Standard_error_field_1003_06 SubIndex_1003 6-6;
SG_MUL_VAL_ 1559 Standard_error_field_1003_05 SubIndex_1003 5-5;
SG_MUL_VAL_ 1559 Standard_error_field_1003_04 SubIndex_1003 4-4;
SG_MUL_VAL_ 1559 Standard_error_field_1003_03 SubIndex_1003 3-3;
SG_MUL_VAL_ 1559 Standard_error_field_1003_02 SubIndex_1003 2-2;
SG_MUL_VAL_ 1559 Standard_error_field_1003_01 SubIndex_1003 1-1;
SG_MUL_VAL_ 1559 Number_of_Errors_1003_00 SubIndex_1003 0-0;
SG_MUL_VAL_ 1559 SubIndex_1003 Index 4099-4099;
SG_MUL_VAL_ 1559 Error_Register_1001 SubIndex_1001 0-0;
SG_MUL_VAL_ 1559 SubIndex_1001 Index 4097-4097;
SG_MUL_VAL_ 1559 Device_Type_1000 SubIndex_1000 0-0;
SG_MUL_VAL_ 1559 SubIndex_1000 Index 4096-4096;
SG_MUL_VAL_ 1559 Index TransferType 1-1;
SG_MUL_VAL_ 1559 TransferType CCS 1-2;
SG_MUL_VAL_ 1559 NotUsedBytes CCS 1-2;
SG_MUL_VAL_ 1559 SizeIndicator CCS 1-2;
SG_MUL_VAL_ 1418 UInt32_2_A643_03 SubIndex_A643 3-3;
SG_MUL_VAL_ 1418 UInt32_2_A643_02 SubIndex_A643 2-2;
SG_MUL_VAL_ 1418 UInt32_1_A643_01 SubIndex_A643 1-1;
SG_MUL_VAL_ 1418 NrOfObjects_A643_00 SubIndex_A643 0-0;
SG_MUL_VAL_ 1418 SubIndex_A643 Index 42563-42563;
SG_MUL_VAL_ 1418 Int16_2_A642_03 SubIndex_A642 3-3;
SG_MUL_VAL_ 1418 Int16_2_A642_02 SubIndex_A642 2-2;
SG_MUL_VAL_ 1418 Int16_1_A642_01 SubIndex_A642 1-1;
SG_MUL_VAL_ 1418 NrOfObjects_A642_00 SubIndex_A642 0-0;
SG_MUL_VAL_ 1418 SubIndex_A642 Index 42562-42562;
SG_MUL_VAL_ 1418 Pressure_1_Sensor3_Inverted_A641 SubIndex_A641 3-3;
SG_MUL_VAL_ 1418 Pressure_1_Sensor2_Inverted_A641 SubIndex_A641 2-2;
SG_MUL_VAL_ 1418 Pressure_1_Sensor1_Inverted_A641 SubIndex_A641 1-1;
SG_MUL_VAL_ 1418 NrOfObjects_A641_00 SubIndex_A641 0-0;
SG_MUL_VAL_ 1418 SubIndex_A641 Index 42561-42561;
SG_MUL_VAL_ 1418 Pressure_1_Sensor3_A640_03 SubIndex_A640 3-3;
SG_MUL_VAL_ 1418 Pressure_1_Sensor2_A640_02 SubIndex_A640 2-2;
SG_MUL_VAL_ 1418 Pressure_1_Sensor1_A640_01 SubIndex_A640 1-1;
SG_MUL_VAL_ 1418 NrOfObjects_A640_00 SubIndex_A640 0-0;
SG_MUL_VAL_ 1418 SubIndex_A640 Index 42560-42560;
SG_MUL_VAL_ 1418 BootTime_1F89 SubIndex_1F89 0-0;
SG_MUL_VAL_ 1418 SubIndex_1F89 Index 8073-8073;
SG_MUL_VAL_ 1418 SerialNumber127_1F88_7F SubIndex_1F88 127-127;
SG_MUL_VAL_ 1418 SerialNumber126_1F88_7E SubIndex_1F88 126-126;
SG_MUL_VAL_ 1418 SerialNumber125_1F88_7D SubIndex_1F88 125-125;
SG_MUL_VAL_ 1418 SerialNumber124_1F88_7C SubIndex_1F88 124-124;
SG_MUL_VAL_ 1418 SerialNumber123_1F88_7B SubIndex_1F88 123-123;
SG_MUL_VAL_ 1418 SerialNumber122_1F88_7A SubIndex_1F88 122-122;
SG_MUL_VAL_ 1418 SerialNumber121_1F88_79 SubIndex_1F88 121-121;
SG_MUL_VAL_ 1418 SerialNumber120_1F88_78 SubIndex_1F88 120-120;
SG_MUL_VAL_ 1418 SerialNumber119_1F88_77 SubIndex_1F88 119-119;
SG_MUL_VAL_ 1418 SerialNumber118_1F88_76 SubIndex_1F88 118-118;
SG_MUL_VAL_ 1418 SerialNumber117_1F88_75 SubIndex_1F88 117-117;
SG_MUL_VAL_ 1418 SerialNumber116_1F88_74 SubIndex_1F88 116-116;
SG_MUL_VAL_ 1418 SerialNumber115_1F88_73 SubIndex_1F88 115-115;
SG_MUL_VAL_ 1418 SerialNumber114_1F88_72 SubIndex_1F88 114-114;
SG_MUL_VAL_ 1418 SerialNumber113_1F88_71 SubIndex_1F88 113-113;
SG_MUL_VAL_ 1418 SerialNumber112_1F88_70 SubIndex_1F88 112-112;
SG_MUL_VAL_ 1418 SerialNumber111_1F88_6F SubIndex_1F88 111-111;
SG_MUL_VAL_ 1418 SerialNumber110_1F88_6E SubIndex_1F88 110-110;
SG_MUL_VAL_ 1418 SerialNumber109_1F88_6D SubIndex_1F88 109-109;
SG_MUL_VAL_ 1418 SerialNumber108_1F88_6C SubIndex_1F88 108-108;
SG_MUL_VAL_ 1418 SerialNumber107_1F88_6B SubIndex_1F88 107-107;
SG_MUL_VAL_ 1418 SerialNumber106_1F88_6A SubIndex_1F88 106-106;
SG_MUL_VAL_ 1418 SerialNumber105_1F88_69 SubIndex_1F88 105-105;
SG_MUL_VAL_ 1418 SerialNumber104_1F88_68 SubIndex_1F88 104-104;
SG_MUL_VAL_ 1418 SerialNumber103_1F88_67 SubIndex_1F88 103-103;
SG_MUL_VAL_ 1418 SerialNumber102_1F88_66 SubIndex_1F88 102-102;
SG_MUL_VAL_ 1418 SerialNumber101_1F88_65 SubIndex_1F88 101-101;
SG_MUL_VAL_ 1418 SerialNumber100_1F88_64 SubIndex_1F88 100-100;
SG_MUL_VAL_ 1418 SerialNumber99_1F88_63 SubIndex_1F88 99-99;
SG_MUL_VAL_ 1418 SerialNumber98_1F88_62 SubIndex_1F88 98-98;
SG_MUL_VAL_ 1418 SerialNumber97_1F88_61 SubIndex_1F88 97-97;
SG_MUL_VAL_ 1418 SerialNumber96_1F88_60 SubIndex_1F88 96-96;
SG_MUL_VAL_ 1418 SerialNumber95_1F88_5F SubIndex_1F88 95-95;
SG_MUL_VAL_ 1418 SerialNumber94_1F88_5E SubIndex_1F88 94-94;
SG_MUL_VAL_ 1418 SerialNumber93_1F88_5D SubIndex_1F88 93-93;
SG_MUL_VAL_ 1418 SerialNumber92_1F88_5C SubIndex_1F88 92-92;
SG_MUL_VAL_ 1418 SerialNumber91_1F88_5B SubIndex_1F88 91-91;
SG_MUL_VAL_ 1418 SerialNumber90_1F88_5A SubIndex_1F88 90-90;
SG_MUL_VAL_ 1418 SerialNumber89_1F88_59 SubIndex_1F88 89-89;
SG_MUL_VAL_ 1418 SerialNumber88_1F88_58 SubIndex_1F88 88-88;
SG_MUL_VAL_ 1418 SerialNumber87_1F88_57 SubIndex_1F88 87-87;
SG_MUL_VAL_ 1418 SerialNumber86_1F88_56 SubIndex_1F88 86-86;
SG_MUL_VAL_ 1418 SerialNumber85_1F88_55 SubIndex_1F88 85-85;
SG_MUL_VAL_ 1418 SerialNumber84_1F88_54 SubIndex_1F88 84-84;
SG_MUL_VAL_ 1418 SerialNumber83_1F88_53 SubIndex_1F88 83-83;
SG_MUL_VAL_ 1418 SerialNumber82_1F88_52 SubIndex_1F88 82-82;
SG_MUL_VAL_ 1418 SerialNumber81_1F88_51 SubIndex_1F88 81-81;
SG_MUL_VAL_ 1418 SerialNumber80_1F88_50 SubIndex_1F88 80-80;
SG_MUL_VAL_ 1418 SerialNumber79_1F88_4F SubIndex_1F88 79-79;
SG_MUL_VAL_ 1418 SerialNumber78_1F88_4E SubIndex_1F88 78-78;
SG_MUL_VAL_ 1418 SerialNumber77_1F88_4D SubIndex_1F88 77-77;
SG_MUL_VAL_ 1418 SerialNumber76_1F88_4C SubIndex_1F88 76-76;
SG_MUL_VAL_ 1418 SerialNumber75_1F88_4B SubIndex_1F88 75-75;
SG_MUL_VAL_ 1418 SerialNumber74_1F88_4A SubIndex_1F88 74-74;
SG_MUL_VAL_ 1418 SerialNumber73_1F88_49 SubIndex_1F88 73-73;
SG_MUL_VAL_ 1418 SerialNumber72_1F88_48 SubIndex_1F88 72-72;
SG_MUL_VAL_ 1418 SerialNumber71_1F88_47 SubIndex_1F88 71-71;
SG_MUL_VAL_ 1418 SerialNumber70_1F88_46 SubIndex_1F88 70-70;
SG_MUL_VAL_ 1418 SerialNumber69_1F88_45 SubIndex_1F88 69-69;
SG_MUL_VAL_ 1418 SerialNumber68_1F88_44 SubIndex_1F88 68-68;
SG_MUL_VAL_ 1418 SerialNumber67_1F88_43 SubIndex_1F88 67-67;
SG_MUL_VAL_ 1418 SerialNumber66_1F88_42 SubIndex_1F88 66-66;
SG_MUL_VAL_ 1418 SerialNumber65_1F88_41 SubIndex_1F88 65-65;
SG_MUL_VAL_ 1418 SerialNumber64_1F88_40 SubIndex_1F88 64-64;
SG_MUL_VAL_ 1418 SerialNumber63_1F88_3F SubIndex_1F88 63-63;
SG_MUL_VAL_ 1418 SerialNumber62_1F88_3E SubIndex_1F88 62-62;
SG_MUL_VAL_ 1418 SerialNumber61_1F88_3D SubIndex_1F88 61-61;
SG_MUL_VAL_ 1418 SerialNumber60_1F88_3C SubIndex_1F88 60-60;
SG_MUL_VAL_ 1418 SerialNumber59_1F88_3B SubIndex_1F88 59-59;
SG_MUL_VAL_ 1418 SerialNumber58_1F88_3A SubIndex_1F88 58-58;
SG_MUL_VAL_ 1418 SerialNumber57_1F88_39 SubIndex_1F88 57-57;
SG_MUL_VAL_ 1418 SerialNumber56_1F88_38 SubIndex_1F88 56-56;
SG_MUL_VAL_ 1418 SerialNumber55_1F88_37 SubIndex_1F88 55-55;
SG_MUL_VAL_ 1418 SerialNumber54_1F88_36 SubIndex_1F88 54-54;
SG_MUL_VAL_ 1418 SerialNumber53_1F88_35 SubIndex_1F88 53-53;
SG_MUL_VAL_ 1418 SerialNumber52_1F88_34 SubIndex_1F88 52-52;
SG_MUL_VAL_ 1418 SerialNumber51_1F88_33 SubIndex_1F88 51-51;
SG_MUL_VAL_ 1418 SerialNumber50_1F88_32 SubIndex_1F88 50-50;
SG_MUL_VAL_ 1418 SerialNumber49_1F88_31 SubIndex_1F88 49-49;
SG_MUL_VAL_ 1418 SerialNumber48_1F88_30 SubIndex_1F88 48-48;
SG_MUL_VAL_ 1418 SerialNumber47_1F88_2F SubIndex_1F88 47-47;
SG_MUL_VAL_ 1418 SerialNumber46_1F88_2E SubIndex_1F88 46-46;
SG_MUL_VAL_ 1418 SerialNumber45_1F88_2D SubIndex_1F88 45-45;
SG_MUL_VAL_ 1418 SerialNumber44_1F88_2C SubIndex_1F88 44-44;
SG_MUL_VAL_ 1418 SerialNumber43_1F88_2B SubIndex_1F88 43-43;
SG_MUL_VAL_ 1418 SerialNumber42_1F88_2A SubIndex_1F88 42-42;
SG_MUL_VAL_ 1418 SerialNumber41_1F88_29 SubIndex_1F88 41-41;
SG_MUL_VAL_ 1418 SerialNumber40_1F88_28 SubIndex_1F88 40-40;
SG_MUL_VAL_ 1418 SerialNumber39_1F88_27 SubIndex_1F88 39-39;
SG_MUL_VAL_ 1418 SerialNumber38_1F88_26 SubIndex_1F88 38-38;
SG_MUL_VAL_ 1418 SerialNumber37_1F88_25 SubIndex_1F88 37-37;
SG_MUL_VAL_ 1418 SerialNumber36_1F88_24 SubIndex_1F88 36-36;
SG_MUL_VAL_ 1418 SerialNumber35_1F88_23 SubIndex_1F88 35-35;
SG_MUL_VAL_ 1418 SerialNumber34_1F88_22 SubIndex_1F88 34-34;
SG_MUL_VAL_ 1418 SerialNumber33_1F88_21 SubIndex_1F88 33-33;
SG_MUL_VAL_ 1418 SerialNumber32_1F88_20 SubIndex_1F88 32-32;
SG_MUL_VAL_ 1418 SerialNumber31_1F88_1F SubIndex_1F88 31-31;
SG_MUL_VAL_ 1418 SerialNumber30_1F88_1E SubIndex_1F88 30-30;
SG_MUL_VAL_ 1418 SerialNumber29_1F88_1D SubIndex_1F88 29-29;
SG_MUL_VAL_ 1418 SerialNumber28_1F88_1C SubIndex_1F88 28-28;
SG_MUL_VAL_ 1418 SerialNumber27_1F88_1B SubIndex_1F88 27-27;
SG_MUL_VAL_ 1418 SerialNumber26_1F88_1A SubIndex_1F88 26-26;
SG_MUL_VAL_ 1418 SerialNumber25_1F88_19 SubIndex_1F88 25-25;
SG_MUL_VAL_ 1418 SerialNumber24_1F88_18 SubIndex_1F88 24-24;
SG_MUL_VAL_ 1418 SerialNumber23_1F88_17 SubIndex_1F88 23-23;
SG_MUL_VAL_ 1418 SerialNumber22_1F88_16 SubIndex_1F88 22-22;
SG_MUL_VAL_ 1418 SerialNumber21_1F88_15 SubIndex_1F88 21-21;
SG_MUL_VAL_ 1418 SerialNumber20_1F88_14 SubIndex_1F88 20-20;
SG_MUL_VAL_ 1418 SerialNumber19_1F88_13 SubIndex_1F88 19-19;
SG_MUL_VAL_ 1418 SerialNumber18_1F88_12 SubIndex_1F88 18-18;
SG_MUL_VAL_ 1418 SerialNumber17_1F88_11 SubIndex_1F88 17-17;
SG_MUL_VAL_ 1418 SerialNumber16_1F88_10 SubIndex_1F88 16-16;
SG_MUL_VAL_ 1418 SerialNumber15_1F88_0F SubIndex_1F88 15-15;
SG_MUL_VAL_ 1418 SerialNumber14_1F88_0E SubIndex_1F88 14-14;
SG_MUL_VAL_ 1418 SerialNumber13_1F88_0D SubIndex_1F88 13-13;
SG_MUL_VAL_ 1418 SerialNumber12_1F88_0C SubIndex_1F88 12-12;
SG_MUL_VAL_ 1418 SerialNumber11_1F88_0B SubIndex_1F88 11-11;
SG_MUL_VAL_ 1418 SerialNumber10_1F88_0A SubIndex_1F88 10-10;
SG_MUL_VAL_ 1418 SerialNumber9_1F88_09 SubIndex_1F88 9-9;
SG_MUL_VAL_ 1418 SerialNumber8_1F88_08 SubIndex_1F88 8-8;
SG_MUL_VAL_ 1418 SerialNumber7_1F88_07 SubIndex_1F88 7-7;
SG_MUL_VAL_ 1418 SerialNumber6_1F88_06 SubIndex_1F88 6-6;
SG_MUL_VAL_ 1418 SerialNumber5_1F88_05 SubIndex_1F88 5-5;
SG_MUL_VAL_ 1418 SerialNumber4_1F88_04 SubIndex_1F88 4-4;
SG_MUL_VAL_ 1418 SerialNumber3_1F88_03 SubIndex_1F88 3-3;
SG_MUL_VAL_ 1418 SerialNumber2_1F88_02 SubIndex_1F88 2-2;
SG_MUL_VAL_ 1418 SerialNumber1_1F88_01 SubIndex_1F88 1-1;
SG_MUL_VAL_ 1418 NrOfObjects_1F88_00 SubIndex_1F88 0-0;
SG_MUL_VAL_ 1418 SubIndex_1F88 Index 8072-8072;
SG_MUL_VAL_ 1418 RevisionNumber127_1F87_7F SubIndex_1F87 127-127;
SG_MUL_VAL_ 1418 RevisionNumber126_1F87_7E SubIndex_1F87 126-126;
SG_MUL_VAL_ 1418 RevisionNumber125_1F87_7D SubIndex_1F87 125-125;
SG_MUL_VAL_ 1418 RevisionNumber124_1F87_7C SubIndex_1F87 124-124;
SG_MUL_VAL_ 1418 RevisionNumber123_1F87_7B SubIndex_1F87 123-123;
SG_MUL_VAL_ 1418 RevisionNumber122_1F87_7A SubIndex_1F87 122-122;
SG_MUL_VAL_ 1418 RevisionNumber121_1F87_79 SubIndex_1F87 121-121;
SG_MUL_VAL_ 1418 RevisionNumber120_1F87_78 SubIndex_1F87 120-120;
SG_MUL_VAL_ 1418 RevisionNumber119_1F87_77 SubIndex_1F87 119-119;
SG_MUL_VAL_ 1418 RevisionNumber118_1F87_76 SubIndex_1F87 118-118;
SG_MUL_VAL_ 1418 RevisionNumber117_1F87_75 SubIndex_1F87 117-117;
SG_MUL_VAL_ 1418 RevisionNumber116_1F87_74 SubIndex_1F87 116-116;
SG_MUL_VAL_ 1418 RevisionNumber115_1F87_73 SubIndex_1F87 115-115;
SG_MUL_VAL_ 1418 RevisionNumber114_1F87_72 SubIndex_1F87 114-114;
SG_MUL_VAL_ 1418 RevisionNumber113_1F87_71 SubIndex_1F87 113-113;
SG_MUL_VAL_ 1418 RevisionNumber112_1F87_70 SubIndex_1F87 112-112;
SG_MUL_VAL_ 1418 RevisionNumber111_1F87_6F SubIndex_1F87 111-111;
SG_MUL_VAL_ 1418 RevisionNumber110_1F87_6E SubIndex_1F87 110-110;
SG_MUL_VAL_ 1418 RevisionNumber109_1F87_6D SubIndex_1F87 109-109;
SG_MUL_VAL_ 1418 RevisionNumber108_1F87_6C SubIndex_1F87 108-108;
SG_MUL_VAL_ 1418 RevisionNumber107_1F87_6B SubIndex_1F87 107-107;
SG_MUL_VAL_ 1418 RevisionNumber106_1F87_6A SubIndex_1F87 106-106;
SG_MUL_VAL_ 1418 RevisionNumber105_1F87_69 SubIndex_1F87 105-105;
SG_MUL_VAL_ 1418 RevisionNumber104_1F87_68 SubIndex_1F87 104-104;
SG_MUL_VAL_ 1418 RevisionNumber103_1F87_67 SubIndex_1F87 103-103;
SG_MUL_VAL_ 1418 RevisionNumber102_1F87_66 SubIndex_1F87 102-102;
SG_MUL_VAL_ 1418 RevisionNumber101_1F87_65 SubIndex_1F87 101-101;
SG_MUL_VAL_ 1418 RevisionNumber100_1F87_64 SubIndex_1F87 100-100;
SG_MUL_VAL_ 1418 RevisionNumber99_1F87_63 SubIndex_1F87 99-99;
SG_MUL_VAL_ 1418 RevisionNumber98_1F87_62 SubIndex_1F87 98-98;
SG_MUL_VAL_ 1418 RevisionNumber97_1F87_61 SubIndex_1F87 97-97;
SG_MUL_VAL_ 1418 RevisionNumber96_1F87_60 SubIndex_1F87 96-96;
SG_MUL_VAL_ 1418 RevisionNumber95_1F87_5F SubIndex_1F87 95-95;
SG_MUL_VAL_ 1418 RevisionNumber94_1F87_5E SubIndex_1F87 94-94;
SG_MUL_VAL_ 1418 RevisionNumber93_1F87_5D SubIndex_1F87 93-93;
SG_MUL_VAL_ 1418 RevisionNumber92_1F87_5C SubIndex_1F87 92-92;
SG_MUL_VAL_ 1418 RevisionNumber91_1F87_5B SubIndex_1F87 91-91;
SG_MUL_VAL_ 1418 RevisionNumber90_1F87_5A SubIndex_1F87 90-90;
SG_MUL_VAL_ 1418 RevisionNumber89_1F87_59 SubIndex_1F87 89-89;
SG_MUL_VAL_ 1418 RevisionNumber88_1F87_58 SubIndex_1F87 88-88;
SG_MUL_VAL_ 1418 RevisionNumber87_1F87_57 SubIndex_1F87 87-87;
SG_MUL_VAL_ 1418 RevisionNumber86_1F87_56 SubIndex_1F87 86-86;
SG_MUL_VAL_ 1418 RevisionNumber85_1F87_55 SubIndex_1F87 85-85;
SG_MUL_VAL_ 1418 RevisionNumber84_1F87_54 SubIndex_1F87 84-84;
SG_MUL_VAL_ 1418 RevisionNumber83_1F87_53 SubIndex_1F87 83-83;
SG_MUL_VAL_ 1418 RevisionNumber82_1F87_52 SubIndex_1F87 82-82;
SG_MUL_VAL_ 1418 RevisionNumber81_1F87_51 SubIndex_1F87 81-81;
SG_MUL_VAL_ 1418 RevisionNumber80_1F87_50 SubIndex_1F87 80-80;
SG_MUL_VAL_ 1418 RevisionNumber79_1F87_4F SubIndex_1F87 79-79;
SG_MUL_VAL_ 1418 RevisionNumber78_1F87_4E SubIndex_1F87 78-78;
SG_MUL_VAL_ 1418 RevisionNumber77_1F87_4D SubIndex_1F87 77-77;
SG_MUL_VAL_ 1418 RevisionNumber76_1F87_4C SubIndex_1F87 76-76;
SG_MUL_VAL_ 1418 RevisionNumber75_1F87_4B SubIndex_1F87 75-75;
SG_MUL_VAL_ 1418 RevisionNumber74_1F87_4A SubIndex_1F87 74-74;
SG_MUL_VAL_ 1418 RevisionNumber73_1F87_49 SubIndex_1F87 73-73;
SG_MUL_VAL_ 1418 RevisionNumber72_1F87_48 SubIndex_1F87 72-72;
SG_MUL_VAL_ 1418 RevisionNumber71_1F87_47 SubIndex_1F87 71-71;
SG_MUL_VAL_ 1418 RevisionNumber70_1F87_46 SubIndex_1F87 70-70;
SG_MUL_VAL_ 1418 RevisionNumber69_1F87_45 SubIndex_1F87 69-69;
SG_MUL_VAL_ 1418 RevisionNumber68_1F87_44 SubIndex_1F87 68-68;
SG_MUL_VAL_ 1418 RevisionNumber67_1F87_43 SubIndex_1F87 67-67;
SG_MUL_VAL_ 1418 RevisionNumber66_1F87_42 SubIndex_1F87 66-66;
SG_MUL_VAL_ 1418 RevisionNumber65_1F87_41 SubIndex_1F87 65-65;
SG_MUL_VAL_ 1418 RevisionNumber64_1F87_40 SubIndex_1F87 64-64;
SG_MUL_VAL_ 1418 RevisionNumber63_1F87_3F SubIndex_1F87 63-63;
SG_MUL_VAL_ 1418 RevisionNumber62_1F87_3E SubIndex_1F87 62-62;
SG_MUL_VAL_ 1418 RevisionNumber61_1F87_3D SubIndex_1F87 61-61;
SG_MUL_VAL_ 1418 RevisionNumber60_1F87_3C SubIndex_1F87 60-60;
SG_MUL_VAL_ 1418 RevisionNumber59_1F87_3B SubIndex_1F87 59-59;
SG_MUL_VAL_ 1418 RevisionNumber58_1F87_3A SubIndex_1F87 58-58;
SG_MUL_VAL_ 1418 RevisionNumber57_1F87_39 SubIndex_1F87 57-57;
SG_MUL_VAL_ 1418 RevisionNumber56_1F87_38 SubIndex_1F87 56-56;
SG_MUL_VAL_ 1418 RevisionNumber55_1F87_37 SubIndex_1F87 55-55;
SG_MUL_VAL_ 1418 RevisionNumber54_1F87_36 SubIndex_1F87 54-54;
SG_MUL_VAL_ 1418 RevisionNumber53_1F87_35 SubIndex_1F87 53-53;
SG_MUL_VAL_ 1418 RevisionNumber52_1F87_34 SubIndex_1F87 52-52;
SG_MUL_VAL_ 1418 RevisionNumber51_1F87_33 SubIndex_1F87 51-51;
SG_MUL_VAL_ 1418 RevisionNumber50_1F87_32 SubIndex_1F87 50-50;
SG_MUL_VAL_ 1418 RevisionNumber49_1F87_31 SubIndex_1F87 49-49;
SG_MUL_VAL_ 1418 RevisionNumber48_1F87_30 SubIndex_1F87 48-48;
SG_MUL_VAL_ 1418 RevisionNumber47_1F87_2F SubIndex_1F87 47-47;
SG_MUL_VAL_ 1418 RevisionNumber46_1F87_2E SubIndex_1F87 46-46;
SG_MUL_VAL_ 1418 RevisionNumber45_1F87_2D SubIndex_1F87 45-45;
SG_MUL_VAL_ 1418 RevisionNumber44_1F87_2C SubIndex_1F87 44-44;
SG_MUL_VAL_ 1418 RevisionNumber43_1F87_2B SubIndex_1F87 43-43;
SG_MUL_VAL_ 1418 RevisionNumber42_1F87_2A SubIndex_1F87 42-42;
SG_MUL_VAL_ 1418 RevisionNumber41_1F87_29 SubIndex_1F87 41-41;
SG_MUL_VAL_ 1418 RevisionNumber40_1F87_28 SubIndex_1F87 40-40;
SG_MUL_VAL_ 1418 RevisionNumber39_1F87_27 SubIndex_1F87 39-39;
SG_MUL_VAL_ 1418 RevisionNumber38_1F87_26 SubIndex_1F87 38-38;
SG_MUL_VAL_ 1418 RevisionNumber37_1F87_25 SubIndex_1F87 37-37;
SG_MUL_VAL_ 1418 RevisionNumber36_1F87_24 SubIndex_1F87 36-36;
SG_MUL_VAL_ 1418 RevisionNumber35_1F87_23 SubIndex_1F87 35-35;
SG_MUL_VAL_ 1418 RevisionNumber34_1F87_22 SubIndex_1F87 34-34;
SG_MUL_VAL_ 1418 RevisionNumber33_1F87_21 SubIndex_1F87 33-33;
SG_MUL_VAL_ 1418 RevisionNumber32_1F87_20 SubIndex_1F87 32-32;
SG_MUL_VAL_ 1418 RevisionNumber31_1F87_1F SubIndex_1F87 31-31;
SG_MUL_VAL_ 1418 RevisionNumber30_1F87_1E SubIndex_1F87 30-30;
SG_MUL_VAL_ 1418 RevisionNumber29_1F87_1D SubIndex_1F87 29-29;
SG_MUL_VAL_ 1418 RevisionNumber28_1F87_1C SubIndex_1F87 28-28;
SG_MUL_VAL_ 1418 RevisionNumber27_1F87_1B SubIndex_1F87 27-27;
SG_MUL_VAL_ 1418 RevisionNumber26_1F87_1A SubIndex_1F87 26-26;
SG_MUL_VAL_ 1418 RevisionNumber25_1F87_19 SubIndex_1F87 25-25;
SG_MUL_VAL_ 1418 RevisionNumber24_1F87_18 SubIndex_1F87 24-24;
SG_MUL_VAL_ 1418 RevisionNumber23_1F87_17 SubIndex_1F87 23-23;
SG_MUL_VAL_ 1418 RevisionNumber22_1F87_16 SubIndex_1F87 22-22;
SG_MUL_VAL_ 1418 RevisionNumber21_1F87_15 SubIndex_1F87 21-21;
SG_MUL_VAL_ 1418 RevisionNumber20_1F87_14 SubIndex_1F87 20-20;
SG_MUL_VAL_ 1418 RevisionNumber19_1F87_13 SubIndex_1F87 19-19;
SG_MUL_VAL_ 1418 RevisionNumber18_1F87_12 SubIndex_1F87 18-18;
SG_MUL_VAL_ 1418 RevisionNumber17_1F87_11 SubIndex_1F87 17-17;
SG_MUL_VAL_ 1418 RevisionNumber16_1F87_10 SubIndex_1F87 16-16;
SG_MUL_VAL_ 1418 RevisionNumber15_1F87_0F SubIndex_1F87 15-15;
SG_MUL_VAL_ 1418 RevisionNumber14_1F87_0E SubIndex_1F87 14-14;
SG_MUL_VAL_ 1418 RevisionNumber13_1F87_0D SubIndex_1F87 13-13;
SG_MUL_VAL_ 1418 RevisionNumber12_1F87_0C SubIndex_1F87 12-12;
SG_MUL_VAL_ 1418 RevisionNumber11_1F87_0B SubIndex_1F87 11-11;
SG_MUL_VAL_ 1418 RevisionNumber10_1F87_0A SubIndex_1F87 10-10;
SG_MUL_VAL_ 1418 RevisionNumber9_1F87_09 SubIndex_1F87 9-9;
SG_MUL_VAL_ 1418 RevisionNumber8_1F87_08 SubIndex_1F87 8-8;
SG_MUL_VAL_ 1418 RevisionNumber7_1F87_07 SubIndex_1F87 7-7;
SG_MUL_VAL_ 1418 RevisionNumber6_1F87_06 SubIndex_1F87 6-6;
SG_MUL_VAL_ 1418 RevisionNumber5_1F87_05 SubIndex_1F87 5-5;
SG_MUL_VAL_ 1418 RevisionNumber4_1F87_04 SubIndex_1F87 4-4;
SG_MUL_VAL_ 1418 RevisionNumber3_1F87_03 SubIndex_1F87 3-3;
SG_MUL_VAL_ 1418 RevisionNumber2_1F87_02 SubIndex_1F87 2-2;
SG_MUL_VAL_ 1418 RevisionNumber1_1F87_01 SubIndex_1F87 1-1;
